// *************************************************************************** *
// *                                                                           *
// * Description:         CANDB File                                           *
// * Generated at:        2025-10-17 10:36                                     *
// * System:              SPA8410_Final2                                       *
// * Variant:             ConfigurationsSPA3d2                                 *
// * Network:             ASDM3CANFD                                           *
// *                                                                           *
// *************************************************************************** *
VERSION "ASDM3CANFD"

NS_ :

BS_ :

BU_ :  ASDM RSRL RSRR
VAL_TABLE_ ElevAlignment_States_RR 2 "MBASC_ELEV_MISALIGNED" 1 "MBASC_ELEV_ALIGNED" 0 "MBASC_ELEV_CALIBRATING" ;
VAL_TABLE_ ElevAlignment_States_RL 2 "MBASC_ELEV_MISALIGNED" 1 "MBASC_ELEV_ALIGNED" 0 "MBASC_ELEV_CALIBRATING" ;

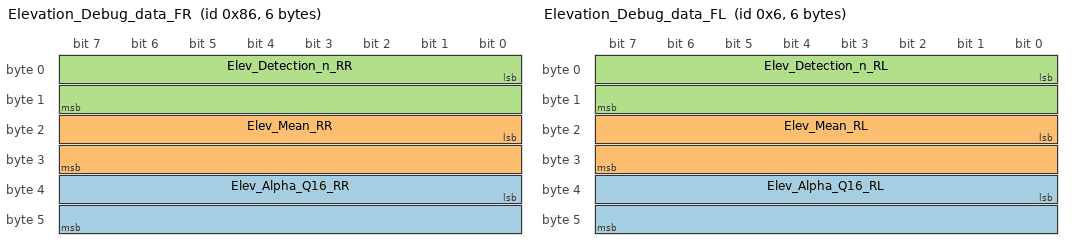
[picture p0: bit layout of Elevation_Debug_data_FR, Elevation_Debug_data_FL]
BO_ 134 Elevation_Debug_data_FR: 6 RSRR
 SG_ Elev_Alpha_Q16_RR : 32|16@1+ (1,0) [0|65535] ""  ASDM
 SG_ Elev_Mean_RR : 16|16@1- (1,0) [-32768|32767] ""  ASDM
 SG_ Elev_Detection_n_RR : 0|16@1+ (1,0) [0|65535] ""  ASDM

BO_ 6 Elevation_Debug_data_FL: 6 RSRL
 SG_ Elev_Alpha_Q16_RL : 32|16@1+ (1,0) [0|65535] ""  ASDM
 SG_ Elev_Mean_RL : 16|16@1- (1,0) [-32768|32767] ""  ASDM
 SG_ Elev_Detection_n_RL : 0|16@1+ (1,0) [0|65535] ""  ASDM

BO_ 917 MB79_PARAMETERS_RR: 24 RSRR
 SG_ Sensor_Serial_Number_RR : 0|192@1+ (1,0) [0|16777215] ""  ASDM

BO_ 789 MB79_PARAMETERS_RL: 24 RSRL
 SG_ Sensor_Serial_Number_RL : 0|192@1+ (1,0) [0|16777215] ""  ASDM

BO_ 898 MB79_SYSTEM_STATUS_RR: 8 RSRR
 SG_ Reserved_2bits_RR : 29|2@1+ (1,0) [0|3] "" Vector__XXX
 SG_ Sensor_Error_Synchronization_Err : 25|1@1+ (1,0) [0|1] "" Vector__XXX
 SG_ Sensor_Error_Supply_Error_RR : 24|1@1+ (1,0) [0|1] "" Vector__XXX
 SG_ Sensor_Error_Software_Incompatib : 27|1@1+ (1,0) [0|1] "" Vector__XXX
 SG_ Sensor_Error_Security_Breach_RR : 28|1@1+ (1,0) [0|1] "" Vector__XXX
 SG_ Sensor_Error_Position_Error_RR : 19|1@1+ (1,0) [0|1] "" Vector__XXX
 SG_ Sensor_Error_Misaligned_RR : 20|1@1+ (1,0) [0|1] "" Vector__XXX
 SG_ Sensor_Error_Internal_Failure_RR : 17|1@1+ (1,0) [0|1] "" Vector__XXX
 SG_ Sensor_Error_Interference_RR : 22|1@1+ (1,0) [0|1] "" Vector__XXX
 SG_ Sensor_Error_Initialization_RR : 23|1@1+ (1,0) [0|1] "" Vector__XXX
 SG_ Sensor_Error_HW_Error_RR : 26|1@1+ (1,0) [0|1] "" Vector__XXX
 SG_ Sensor_Error_Communication_RR : 16|1@1+ (1,0) [0|1] "" Vector__XXX
 SG_ Sensor_Error_Calibration_Error_R : 18|1@1+ (1,0) [0|1] "" Vector__XXX
 SG_ Sensor_Error_Blocked_RR : 21|1@1+ (1,0) [0|1] "" Vector__XXX
 SG_ Heater_Trigger_RR : 31|1@1+ (1,0) [0|1] "" Vector__XXX
 SG_ Sensor_Operation_Mode_RR : 12|4@1+ (1,0) [0|15] ""  ASDM
 SG_ Clock_SystemStatus_RR : 8|4@1+ (1,0) [0|15] ""  ASDM
 SG_ CRC_SystemStatus_RR : 0|8@1+ (1,0) [0|255] ""  ASDM

BO_ 770 MB79_SYSTEM_STATUS_RL: 8 RSRL
 SG_ Reserved_2bits_RL : 29|2@1+ (1,0) [0|3] "" Vector__XXX
 SG_ Sensor_Error_Synchronizatio_0000 : 25|1@1+ (1,0) [0|1] "" Vector__XXX
 SG_ Sensor_Error_Supply_Error_RL : 24|1@1+ (1,0) [0|1] "" Vector__XXX
 SG_ Sensor_Error_Software_Incom_0000 : 27|1@1+ (1,0) [0|1] "" Vector__XXX
 SG_ Sensor_Error_Security_Breach_RL : 28|1@1+ (1,0) [0|1] "" Vector__XXX
 SG_ Sensor_Error_Position_Error_RL : 19|1@1+ (1,0) [0|1] "" Vector__XXX
 SG_ Sensor_Error_Misaligned_RL : 20|1@1+ (1,0) [0|1] "" Vector__XXX
 SG_ Sensor_Error_Internal_Failure_RL : 17|1@1+ (1,0) [0|1] "" Vector__XXX
 SG_ Sensor_Error_Interference_RL : 22|1@1+ (1,0) [0|1] "" Vector__XXX
 SG_ Sensor_Error_Initialization_RL : 23|1@1+ (1,0) [0|1] "" Vector__XXX
 SG_ Sensor_Error_HW_Error_RL : 26|1@1+ (1,0) [0|1] "" Vector__XXX
 SG_ Sensor_Error_Communication_RL : 16|1@1+ (1,0) [0|1] "" Vector__XXX
 SG_ Sensor_Error_Calibration_Er_0000 : 18|1@1+ (1,0) [0|1] "" Vector__XXX
 SG_ Sensor_Error_Blocked_RL : 21|1@1+ (1,0) [0|1] "" Vector__XXX
 SG_ Heater_Trigger_RL : 31|1@1+ (1,0) [0|1] "" Vector__XXX
 SG_ Sensor_Operation_Mode_RL : 12|4@1+ (1,0) [0|15] ""  ASDM
 SG_ Clock_SystemStatus_RL : 8|4@1+ (1,0) [0|15] ""  ASDM
 SG_ CRC_SystemStatus_RL : 0|8@1+ (1,0) [0|255] ""  ASDM

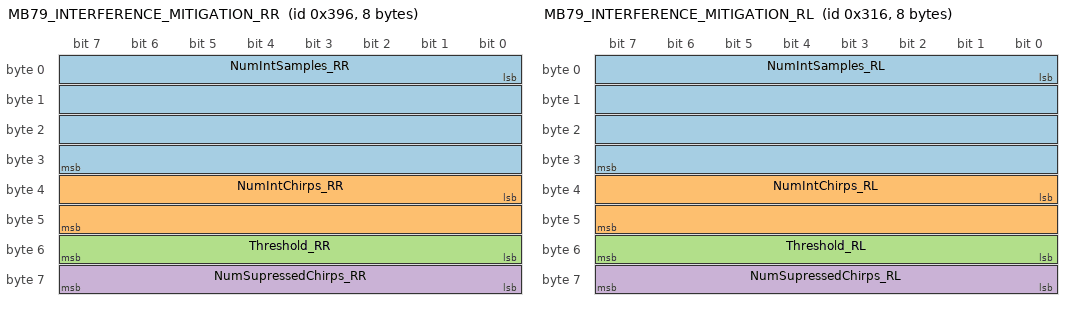
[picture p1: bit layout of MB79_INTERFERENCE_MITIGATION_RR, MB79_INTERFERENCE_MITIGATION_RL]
BO_ 918 MB79_INTERFERENCE_MITIGATION_RR: 8 RSRR
 SG_ NumIntSamples_RR : 0|32@1+ (1,0) [0|16777215] ""  ASDM
 SG_ NumIntChirps_RR : 32|16@1+ (1,0) [0|255] ""  ASDM
 SG_ Threshold_RR : 48|8@1+ (1,0) [0|65535] ""  ASDM
 SG_ NumSupressedChirps_RR : 56|8@1+ (1,0) [0|255] ""  ASDM

BO_ 790 MB79_INTERFERENCE_MITIGATION_RL: 8 RSRL
 SG_ NumIntSamples_RL : 0|32@1+ (1,0) [0|16777215] ""  ASDM
 SG_ NumIntChirps_RL : 32|16@1+ (1,0) [0|255] ""  ASDM
 SG_ Threshold_RL : 48|8@1+ (1,0) [0|65535] ""  ASDM
 SG_ NumSupressedChirps_RL : 56|8@1+ (1,0) [0|255] ""  ASDM

BO_ 2047 AsdmToAllFuncAsdm3CanDiagReqFrame : 64 ASDM
 SG_ AsdmToAllFuncAsdm3CanDiagReqNpdu : 7|512@0+ (1,0) [0|0] "" RSRL, RSRR

BO_ 1953 AsdmToRsrlAsdm3CanDiagReqFrame : 64 ASDM
 SG_ AsdmToRsrlAsdm3CanDiagReqNpdu : 7|512@0+ (1,0) [0|0] "" RSRL

BO_ 1954 AsdmToRsrrAsdm3CanDiagReqFrame : 64 ASDM
 SG_ AsdmToRsrrAsdm3CanDiagReqNpdu : 7|512@0+ (1,0) [0|0] "" RSRR

BO_ 1697 RsrlToAsdmAsdm3CanDiagResFrame : 64 RSRL
 SG_ RsrlToAsdmAsdm3CanDiagResNpdu : 7|512@0+ (1,0) [0|0] "" ASDM

BO_ 1698 RsrrToAsdmAsdm3CanDiagResFrame : 64 RSRR
 SG_ RsrrToAsdmAsdm3CanDiagResNpdu : 7|512@0+ (1,0) [0|0] "" ASDM

BO_ 288 ASDMtoRADAR: 20 ASDM
 SG_ Vehicle_Type : 123|8@0+ (1,0) [0|255] ""  RSRL,RSRR
 SG_ EmblmHeatrOutSts : 117|2@0+ (1,0) [0|0] ""  RSRL,RSRR
 SG_ WshngCycActv : 115|8@0+ (1,0) [0|1] ""  RSRL,RSRR
 SG_ isUsgModSts : 105|4@0+ (1,0) [0|15] ""  RSRL,RSRR
 SG_ PwrLvlElecSubtyp : 3|4@0+ (1,0) [0|15] ""  RSRL,RSRR
 SG_ PwrLvlElecMai : 7|4@0+ (1,0) [0|15] ""  RSRL,RSRR
 SG_ AmbTRawVal : 47|11@0+ (0.1,-70) [-70|134.7] "degC"  RSRL,RSRR
 SG_ AmbTRawQly : 52|2@0+ (1,0) [0|3] ""  RSRL,RSRR
 SG_ BkpOfDstTrvld : 50|21@0+ (1,0) [0|2000000] "km"  RSRL,RSRR
 SG_ CarTiGlb : 15|32@0+ (0.1,0) [0|429496729.5] "s"  RSRL,RSRR
 SG_ CarModSts1 : 81|3@0+ (1,0) [0|7] "N/A"  RSRL,RSRR
 SG_ DrvModReq : 85|4@0+ (1,0) [0|15] ""  RSRL,RSRR
 SG_ VehBattUSysU : 77|8@0+ (0.1,0) [0|25] "Volt"  RSRL,RSRR
 SG_ VehBattUSysUQf : 91|2@0+ (1,0) [0|3] ""  RSRL,RSRR
 SG_ WipgInfoWipgSpdInfo : 94|3@0+ (1,0) [0|7] ""  RSRL,RSRR
 SG_ WipgInfoWiprActv : 97|8@0+ (1,0) [0|255] ""  RSRL,RSRR
 SG_ WipgInfoWiprInWipgAr : 89|8@0+ (1,0) [0|255] ""  RSRL,RSRR

BO_ 1281 MB79_ECU_WAKE_UP_RL: 64 RSRL
 SG_ ECU_Wake_UP_0_RL : 7|8@0+ (1,0) [0|255] "N/A"  ASDM
 SG_ ECU_Wake_UP_1_RL : 15|8@0+ (1,0) [0|255] "N/A"  ASDM
 SG_ ECU_Wake_UP_2_RL : 23|8@0+ (1,0) [0|255] "N/A"  ASDM
 SG_ ECU_Wake_UP_3_RL : 31|8@0+ (1,0) [0|255] "N/A"  ASDM
 SG_ ECU_Wake_UP_4_RL : 39|8@0+ (1,0) [0|255] "N/A"  ASDM
 SG_ ECU_Wake_UP_5_RL : 47|8@0+ (1,0) [0|255] "N/A"  ASDM
 SG_ ECU_Wake_UP_6_RL : 55|8@0+ (1,0) [0|255] "N/A"  ASDM
 SG_ ECU_Wake_UP_7_RL : 63|8@0+ (1,0) [0|255] "N/A"  ASDM

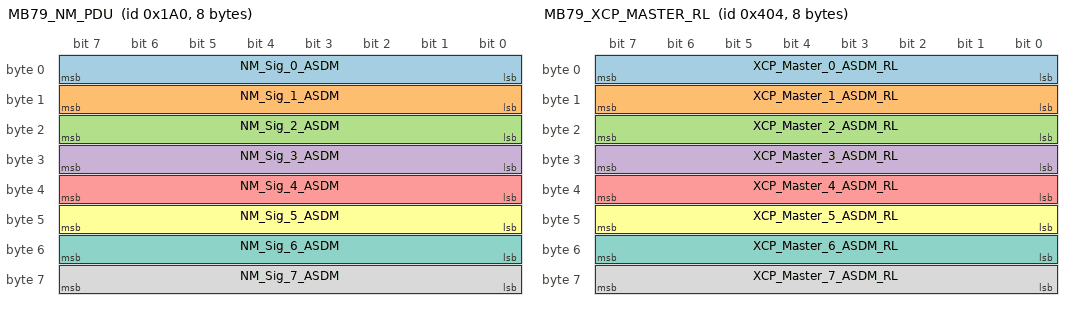
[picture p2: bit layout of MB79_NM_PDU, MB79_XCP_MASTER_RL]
BO_ 416 MB79_NM_PDU: 8 ASDM
 SG_ NM_Sig_0_ASDM : 7|8@0+ (1,0) [0|255] "N/A"  RSRL,RSRR
 SG_ NM_Sig_1_ASDM : 15|8@0+ (1,0) [0|255] "N/A"  RSRL,RSRR
 SG_ NM_Sig_2_ASDM : 23|8@0+ (1,0) [0|255] "N/A"  RSRL,RSRR
 SG_ NM_Sig_3_ASDM : 31|8@0+ (1,0) [0|255] "N/A"  RSRL,RSRR
 SG_ NM_Sig_4_ASDM : 39|8@0+ (1,0) [0|255] "N/A"  RSRL,RSRR
 SG_ NM_Sig_5_ASDM : 47|8@0+ (1,0) [0|255] "N/A"  RSRL,RSRR
 SG_ NM_Sig_6_ASDM : 55|8@0+ (1,0) [0|255] "N/A"  RSRL,RSRR
 SG_ NM_Sig_7_ASDM : 63|8@0+ (1,0) [0|255] "N/A"  RSRL,RSRR

BO_ 1028 MB79_XCP_MASTER_RL: 8 ASDM
 SG_ XCP_Master_0_ASDM_RL : 7|8@0+ (1,0) [0|255] "N/A"  RSRL
 SG_ XCP_Master_1_ASDM_RL : 15|8@0+ (1,0) [0|255] "N/A"  RSRL
 SG_ XCP_Master_2_ASDM_RL : 23|8@0+ (1,0) [0|255] "N/A"  RSRL
 SG_ XCP_Master_3_ASDM_RL : 31|8@0+ (1,0) [0|255] "N/A"  RSRL
 SG_ XCP_Master_4_ASDM_RL : 39|8@0+ (1,0) [0|255] "N/A"  RSRL
 SG_ XCP_Master_5_ASDM_RL : 47|8@0+ (1,0) [0|255] "N/A"  RSRL
 SG_ XCP_Master_6_ASDM_RL : 55|8@0+ (1,0) [0|255] "N/A"  RSRL
 SG_ XCP_Master_7_ASDM_RL : 63|8@0+ (1,0) [0|255] "N/A"  RSRL

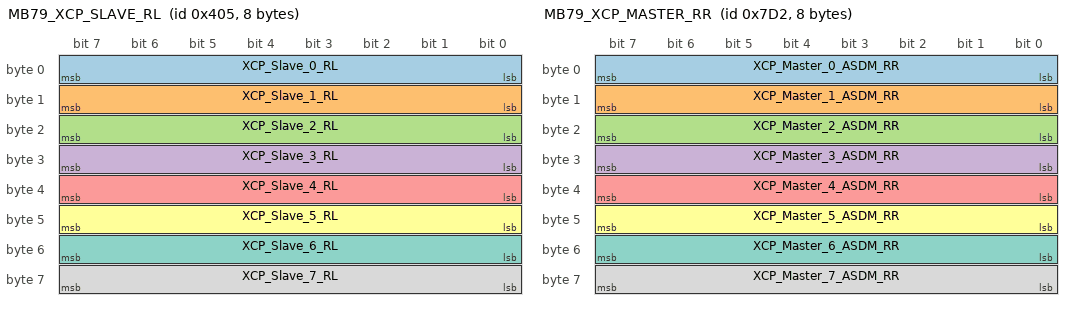
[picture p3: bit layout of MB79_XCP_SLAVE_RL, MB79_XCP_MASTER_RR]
BO_ 1029 MB79_XCP_SLAVE_RL: 8 RSRL
 SG_ XCP_Slave_0_RL : 7|8@0+ (1,0) [0|255] "N/A"  ASDM
 SG_ XCP_Slave_1_RL : 15|8@0+ (1,0) [0|255] "N/A"  ASDM
 SG_ XCP_Slave_2_RL : 23|8@0+ (1,0) [0|255] "N/A"  ASDM
 SG_ XCP_Slave_3_RL : 31|8@0+ (1,0) [0|255] "N/A"  ASDM
 SG_ XCP_Slave_4_RL : 39|8@0+ (1,0) [0|255] "N/A"  ASDM
 SG_ XCP_Slave_5_RL : 47|8@0+ (1,0) [0|255] "N/A"  ASDM
 SG_ XCP_Slave_6_RL : 55|8@0+ (1,0) [0|255] "N/A"  ASDM
 SG_ XCP_Slave_7_RL : 63|8@0+ (1,0) [0|255] "N/A"  ASDM

BO_ 1282 MB79_ECU_WAKE_UP_RR: 64 RSRR
 SG_ ECU_Wake_UP_0_RR : 7|8@0+ (1,0) [0|255] "N/A"  ASDM
 SG_ ECU_Wake_UP_1_RR : 15|8@0+ (1,0) [0|255] "N/A"  ASDM
 SG_ ECU_Wake_UP_2_RR : 23|8@0+ (1,0) [0|255] "N/A"  ASDM
 SG_ ECU_Wake_UP_3_RR : 31|8@0+ (1,0) [0|255] "N/A"  ASDM
 SG_ ECU_Wake_UP_4_RR : 39|8@0+ (1,0) [0|255] "N/A"  ASDM
 SG_ ECU_Wake_UP_5_RR : 47|8@0+ (1,0) [0|255] "N/A"  ASDM
 SG_ ECU_Wake_UP_6_RR : 55|8@0+ (1,0) [0|255] "N/A"  ASDM
 SG_ ECU_Wake_UP_7_RR : 63|8@0+ (1,0) [0|255] "N/A"  ASDM

BO_ 2002 MB79_XCP_MASTER_RR: 8 ASDM
 SG_ XCP_Master_0_ASDM_RR : 7|8@0+ (1,0) [0|255] "N/A"  RSRR
 SG_ XCP_Master_1_ASDM_RR : 15|8@0+ (1,0) [0|255] "N/A"  RSRR
 SG_ XCP_Master_2_ASDM_RR : 23|8@0+ (1,0) [0|255] "N/A"  RSRR
 SG_ XCP_Master_3_ASDM_RR : 31|8@0+ (1,0) [0|255] "N/A"  RSRR
 SG_ XCP_Master_4_ASDM_RR : 39|8@0+ (1,0) [0|255] "N/A"  RSRR
 SG_ XCP_Master_5_ASDM_RR : 47|8@0+ (1,0) [0|255] "N/A"  RSRR
 SG_ XCP_Master_6_ASDM_RR : 55|8@0+ (1,0) [0|255] "N/A"  RSRR
 SG_ XCP_Master_7_ASDM_RR : 63|8@0+ (1,0) [0|255] "N/A"  RSRR

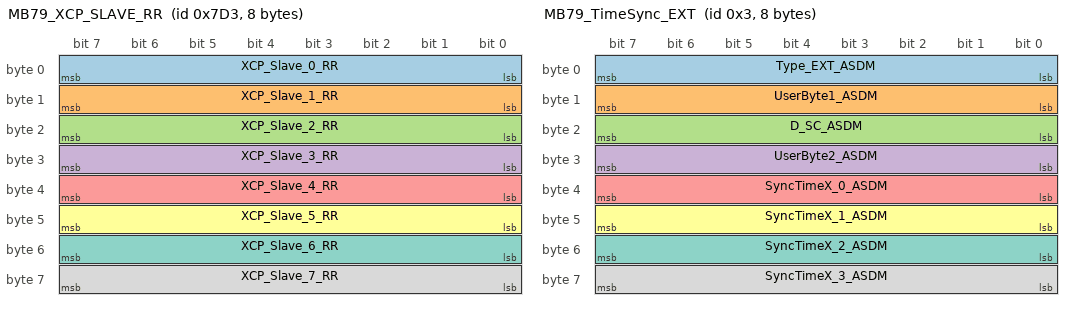
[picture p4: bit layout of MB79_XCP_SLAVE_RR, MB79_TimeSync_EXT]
BO_ 2003 MB79_XCP_SLAVE_RR: 8 RSRR
 SG_ XCP_Slave_0_RR : 7|8@0+ (1,0) [0|255] "N/A"  ASDM
 SG_ XCP_Slave_1_RR : 15|8@0+ (1,0) [0|255] "N/A"  ASDM
 SG_ XCP_Slave_2_RR : 23|8@0+ (1,0) [0|255] "N/A"  ASDM
 SG_ XCP_Slave_3_RR : 31|8@0+ (1,0) [0|255] "N/A"  ASDM
 SG_ XCP_Slave_4_RR : 39|8@0+ (1,0) [0|255] "N/A"  ASDM
 SG_ XCP_Slave_5_RR : 47|8@0+ (1,0) [0|255] "N/A"  ASDM
 SG_ XCP_Slave_6_RR : 55|8@0+ (1,0) [0|255] "N/A"  ASDM
 SG_ XCP_Slave_7_RR : 63|8@0+ (1,0) [0|255] "N/A"  ASDM

BO_ 3 MB79_TimeSync_EXT: 8 ASDM
 SG_ Type_EXT_ASDM : 7|8@0+ (1,0) [0|255] "N/A"  RSRL,RSRR
 SG_ UserByte1_ASDM : 15|8@0+ (1,0) [0|255] "N/A"  RSRL,RSRR
 SG_ D_SC_ASDM : 23|8@0+ (1,0) [0|255] "N/A"  RSRL,RSRR
 SG_ UserByte2_ASDM : 31|8@0+ (1,0) [0|255] "N/A"  RSRL,RSRR
 SG_ SyncTimeX_0_ASDM : 39|8@0+ (1,0) [0|255] "N/A"  RSRL,RSRR
 SG_ SyncTimeX_1_ASDM : 47|8@0+ (1,0) [0|255] "N/A"  RSRL,RSRR
 SG_ SyncTimeX_2_ASDM : 55|8@0+ (1,0) [0|255] "N/A"  RSRL,RSRR
 SG_ SyncTimeX_3_ASDM : 63|8@0+ (1,0) [0|255] "N/A"  RSRL,RSRR

BO_ 257 MB79_DETECTION_HEADER_RL: 64 RSRL
 SG_ ElevAlignment_Status_RL : 504|2@1+ (1,0) [0|3] "" Vector__XXX
 SG_ CRC_DetectionList_RL : 0|32@1+ (1,0) [0|4294967295] "N/A"  ASDM
 SG_ CycleNumber_RL : 32|32@1+ (1,0) [0|4294967295] "cycle"  ASDM
 SG_ TimeStamp_RL : 64|32@1+ (1,0) [0|4294967295] "us"  ASDM
 SG_ HostVelEst_RL : 96|16@1- (1,0) [-2000|14000] "cm/s"  ASDM
 SG_ HostYawEst_RL : 112|16@1- (0.000977,0) [-2|2] "rad/s"  ASDM
 SG_ HostAccelLatEst_RL : 128|16@1- (1,0) [-2000|2000] "cm/s.s"  ASDM
 SG_ HostAccelLongEst_RL : 144|16@1- (1,0) [-2000|2000] "cm/s.s"  ASDM
 SG_ Sensor_Elev_Angle_corr_RL : 160|16@1- (0.01,0) [-180|655.35] "degree"  ASDM
 SG_ Alignment_update_cycle_RL : 176|8@1+ (1,0) [0|255] "N/A"  ASDM
 SG_ Velocity_Correction_RL : 184|16@1- (0.0196,0) [-5|5] "%"  ASDM
 SG_ Sensor_Pos_X_RL : 200|16@1- (0.001,0) [-20|65.535] "m"  ASDM
 SG_ Sensor_Pos_Y_RL : 216|16@1- (0.001,0) [-20|65.535] "m"  ASDM
 SG_ Orientation_Angle_RL : 232|16@1- (0.1,0) [-180|180] "degree"  ASDM
 SG_ Calibrated_Angle_Az_RL : 248|16@1- (0.1,0) [-180|180] "degree"  ASDM
 SG_ Sensor_Pos_Z_RL : 264|8@1+ (0.01,0) [0|2.55] "m"  ASDM
 SG_ Sensor_FoV_Max_RL : 272|8@1+ (1,0) [0|255] "degree"  ASDM
 SG_ Sensor_FoV_Min_RL : 280|8@1+ (1,0) [0|255] "degree"  ASDM
 SG_ BW100KHz1_RL : 288|16@1+ (100,0) [0|6553500] "N/A"  ASDM
 SG_ UnambiguousVelMeas1_RL : 304|8@1+ (1,0) [0|255] "N/A"  ASDM
 SG_ Radar_Sensor_type_RL : 312|8@1+ (1,0) [0|255] "N/A"  ASDM
 SG_ Sensor_Position_ID_RL : 320|4@1+ (1,0) [0|15] "N/A"  ASDM
 SG_ DetectionListVersion_RL : 324|4@1+ (1,0) [0|15] "N/A"  ASDM
 SG_ Detection_Header_Version_RL : 328|4@1+ (1,0) [0|15] "N/A"  ASDM
 SG_ numInfrastructureDetected_RL : 332|10@1+ (1,0) [0|1023] "detection"  ASDM
 SG_ numNonInfraDetected_RL : 342|10@1+ (1,0) [0|1023] "detection"  ASDM
 SG_ numFreespaceDetections_RL : 352|2@1+ (1,0) [0|3] "detection"  ASDM
 SG_ interferenceDetected_RL : 354|2@1+ (1,0) [0|3] "N/A"  ASDM
 SG_ Blockage_Confidence_RL : 356|8@1+ (0.5,0) [0|200] "%"  ASDM
 SG_ Blockage_Level_RL : 364|8@1+ (0.5,0) [0|200] "%"  ASDM
 SG_ Blockage_Status_RL : 372|3@1+ (1,0) [0|7] "N/A"  ASDM
 SG_ max_instrumented_range_2m_RL : 375|8@1+ (2,0) [0|510] "m"  ASDM
 SG_ Sensor_Operation_Mode_RL : 383|4@1+ (1,0) [0|15] "Mode"  ASDM
 SG_ AutoAlignment_Status_RL : 387|4@1+ (1,0) [0|15] "N/A"  ASDM
 SG_ Testing_Mode_RL : 391|4@1+ (1,0) [0|15] "N/A"  ASDM
 SG_ NearZoneDetectionsCount_RL : 395|10@1+ (1,0) [0|512] "detection" Vector__XXX
 SG_ HorizonZoneDetectionsCount_RL : 405|10@1+ (1,0) [0|512] "detection" Vector__XXX
 SG_ Reserved_1byte_RL : 415|8@1- (1,0) [0|0] "" Vector__XXX
 SG_ Detection_Data_Mode_RL : 423|1@1+ (1,0) [0|1] "" Vector__XXX
 SG_ Reserved_3bits_RL : 424|3@1- (1,0) [0|0] "" Vector__XXX
 SG_ AR_Counter_DetectionList_RL : 427|32@1+ (1,0) [0|4294967295] "N/A"  ASDM
 SG_ MAC_DetectionList_RL : 459|24@1+ (1,0) [0|16777215] "N/A"  ASDM
 SG_ Sensor_Topology_RL : 483|1@1+ (1,0) [0|1] "N/A"  ASDM
 SG_ AASC_Calibration_flag_RL : 484|1@1+ (1,0) [0|1] "N/A"  ASDM
 SG_ selected_chirp_config_RL : 485|3@1+ (1,0) [0|7] "N/A"  ASDM
 SG_ FC1MHz1_RL : 488|16@1+ (10,0) [0|65535] "MHz"  ASDM

BO_ 304 MB79_DETECTIONS_0_RL: 64 RSRL
 SG_ zipy_serialized_data_0_RL : 0|32@1- (0.1,0) [-102.4|429496729.5] "degree"  ASDM
 SG_ zipy_serialized_data_1_RL : 32|32@1- (0.1,0) [-102.4|429496729.5] "degree"  ASDM
 SG_ zipy_serialized_data_2_RL : 64|32@1- (0.1,0) [-102.4|429496729.5] "degree"  ASDM
 SG_ zipy_serialized_data_3_RL : 96|32@1- (0.1,0) [-102.4|429496729.5] "degree"  ASDM
 SG_ zipy_serialized_data_4_RL : 128|32@1- (0.1,0) [-102.4|429496729.5] "degree"  ASDM
 SG_ zipy_serialized_data_5_RL : 160|32@1- (0.1,0) [-102.4|429496729.5] "degree"  ASDM
 SG_ zipy_serialized_data_6_RL : 192|32@1- (0.1,0) [-102.4|429496729.5] "degree"  ASDM
 SG_ zipy_serialized_data_7_RL : 224|32@1- (0.1,0) [-102.4|429496729.5] "degree"  ASDM
 SG_ zipy_serialized_data_8_RL : 256|32@1- (0.1,0) [-102.4|429496729.5] "degree"  ASDM
 SG_ zipy_serialized_data_9_RL : 288|32@1- (0.1,0) [-102.4|429496729.5] "degree"  ASDM
 SG_ zipy_serialized_data_10_RL : 320|32@1- (0.1,0) [-102.4|429496729.5] "degree"  ASDM
 SG_ zipy_serialized_data_11_RL : 352|32@1- (0.1,0) [-102.4|429496729.5] "degree"  ASDM
 SG_ zipy_serialized_data_12_RL : 384|32@1- (0.1,0) [-102.4|429496729.5] "degree"  ASDM
 SG_ zipy_serialized_data_13_RL : 416|32@1- (0.1,0) [-102.4|429496729.5] "degree"  ASDM
 SG_ zipy_serialized_data_14_RL : 448|32@1- (0.1,0) [-102.4|429496729.5] "degree"  ASDM
 SG_ zipy_serialized_data_15_RL : 480|32@1- (0.1,0) [-102.4|429496729.5] "degree"  ASDM

BO_ 305 MB79_DETECTIONS_1_RL: 64 RSRL
 SG_ zipy_serialized_data_16_RL : 0|32@1- (0.1,0) [-102.4|429496729.5] "degree"  ASDM
 SG_ zipy_serialized_data_17_RL : 32|32@1- (0.1,0) [-102.4|429496729.5] "degree"  ASDM
 SG_ zipy_serialized_data_18_RL : 64|32@1- (0.1,0) [-102.4|429496729.5] "degree"  ASDM
 SG_ zipy_serialized_data_19_RL : 96|32@1- (0.1,0) [-102.4|429496729.5] "degree"  ASDM
 SG_ zipy_serialized_data_20_RL : 128|32@1- (0.1,0) [-102.4|429496729.5] "degree"  ASDM
 SG_ zipy_serialized_data_21_RL : 160|32@1- (0.1,0) [-102.4|429496729.5] "degree"  ASDM
 SG_ zipy_serialized_data_22_RL : 192|32@1- (0.1,0) [-102.4|429496729.5] "degree"  ASDM
 SG_ zipy_serialized_data_23_RL : 224|32@1- (0.1,0) [-102.4|429496729.5] "degree"  ASDM
 SG_ zipy_serialized_data_24_RL : 256|32@1- (0.1,0) [-102.4|429496729.5] "degree"  ASDM
 SG_ zipy_serialized_data_25_RL : 288|32@1- (0.1,0) [-102.4|429496729.5] "degree"  ASDM
 SG_ zipy_serialized_data_26_RL : 320|32@1- (0.1,0) [-102.4|429496729.5] "degree"  ASDM
 SG_ zipy_serialized_data_27_RL : 352|32@1- (0.1,0) [-102.4|429496729.5] "degree"  ASDM
 SG_ zipy_serialized_data_28_RL : 384|32@1- (0.1,0) [-102.4|429496729.5] "degree"  ASDM
 SG_ zipy_serialized_data_29_RL : 416|32@1- (0.1,0) [-102.4|429496729.5] "degree"  ASDM
 SG_ zipy_serialized_data_30_RL : 448|32@1- (0.1,0) [-102.4|429496729.5] "degree"  ASDM
 SG_ zipy_serialized_data_31_RL : 480|32@1- (0.1,0) [-102.4|429496729.5] "degree"  ASDM

BO_ 306 MB79_DETECTIONS_2_RL: 64 RSRL
 SG_ zipy_serialized_data_32_RL : 0|32@1- (0.1,0) [-102.4|429496729.5] "degree"  ASDM
 SG_ zipy_serialized_data_33_RL : 32|32@1- (0.1,0) [-102.4|429496729.5] "degree"  ASDM
 SG_ zipy_serialized_data_34_RL : 64|32@1- (0.1,0) [-102.4|429496729.5] "degree"  ASDM
 SG_ zipy_serialized_data_35_RL : 96|32@1- (0.1,0) [-102.4|429496729.5] "degree"  ASDM
 SG_ zipy_serialized_data_36_RL : 128|32@1- (0.1,0) [-102.4|429496729.5] "degree"  ASDM
 SG_ zipy_serialized_data_37_RL : 160|32@1- (0.1,0) [-102.4|429496729.5] "degree"  ASDM
 SG_ zipy_serialized_data_38_RL : 192|32@1- (0.1,0) [-102.4|429496729.5] "degree"  ASDM
 SG_ zipy_serialized_data_39_RL : 224|32@1- (0.1,0) [-102.4|429496729.5] "degree"  ASDM
 SG_ zipy_serialized_data_40_RL : 256|32@1- (0.1,0) [-102.4|429496729.5] "degree"  ASDM
 SG_ zipy_serialized_data_41_RL : 288|32@1- (0.1,0) [-102.4|429496729.5] "degree"  ASDM
 SG_ zipy_serialized_data_42_RL : 320|32@1- (0.1,0) [-102.4|429496729.5] "degree"  ASDM
 SG_ zipy_serialized_data_43_RL : 352|32@1- (0.1,0) [-102.4|429496729.5] "degree"  ASDM
 SG_ zipy_serialized_data_44_RL : 384|32@1- (0.1,0) [-102.4|429496729.5] "degree"  ASDM
 SG_ zipy_serialized_data_45_RL : 416|32@1- (0.1,0) [-102.4|429496729.5] "degree"  ASDM
 SG_ zipy_serialized_data_46_RL : 448|32@1- (0.1,0) [-102.4|429496729.5] "degree"  ASDM
 SG_ zipy_serialized_data_47_RL : 480|32@1- (0.1,0) [-102.4|429496729.5] "degree"  ASDM

BO_ 307 MB79_DETECTIONS_3_RL: 64 RSRL
 SG_ zipy_serialized_data_48_RL : 0|32@1- (0.1,0) [-102.4|429496729.5] "degree"  ASDM
 SG_ zipy_serialized_data_49_RL : 32|32@1- (0.1,0) [-102.4|429496729.5] "degree"  ASDM
 SG_ zipy_serialized_data_50_RL : 64|32@1- (0.1,0) [-102.4|429496729.5] "degree"  ASDM
 SG_ zipy_serialized_data_51_RL : 96|32@1- (0.1,0) [-102.4|429496729.5] "degree"  ASDM
 SG_ zipy_serialized_data_52_RL : 128|32@1- (0.1,0) [-102.4|429496729.5] "degree"  ASDM
 SG_ zipy_serialized_data_53_RL : 160|32@1- (0.1,0) [-102.4|429496729.5] "degree"  ASDM
 SG_ zipy_serialized_data_54_RL : 192|32@1- (0.1,0) [-102.4|429496729.5] "degree"  ASDM
 SG_ zipy_serialized_data_55_RL : 224|32@1- (0.1,0) [-102.4|429496729.5] "degree"  ASDM
 SG_ zipy_serialized_data_56_RL : 256|32@1- (0.1,0) [-102.4|429496729.5] "degree"  ASDM
 SG_ zipy_serialized_data_57_RL : 288|32@1- (0.1,0) [-102.4|429496729.5] "degree"  ASDM
 SG_ zipy_serialized_data_58_RL : 320|32@1- (0.1,0) [-102.4|429496729.5] "degree"  ASDM
 SG_ zipy_serialized_data_59_RL : 352|32@1- (0.1,0) [-102.4|429496729.5] "degree"  ASDM
 SG_ zipy_serialized_data_60_RL : 384|32@1- (0.1,0) [-102.4|429496729.5] "degree"  ASDM
 SG_ zipy_serialized_data_61_RL : 416|32@1- (0.1,0) [-102.4|429496729.5] "degree"  ASDM
 SG_ zipy_serialized_data_62_RL : 448|32@1- (0.1,0) [-102.4|429496729.5] "degree"  ASDM
 SG_ zipy_serialized_data_63_RL : 480|32@1- (0.1,0) [-102.4|429496729.5] "degree"  ASDM

BO_ 308 MB79_DETECTIONS_4_RL: 64 RSRL
 SG_ zipy_serialized_data_64_RL : 0|32@1- (0.1,0) [-102.4|429496729.5] "degree"  ASDM
 SG_ zipy_serialized_data_65_RL : 32|32@1- (0.1,0) [-102.4|429496729.5] "degree"  ASDM
 SG_ zipy_serialized_data_66_RL : 64|32@1- (0.1,0) [-102.4|429496729.5] "degree"  ASDM
 SG_ zipy_serialized_data_67_RL : 96|32@1- (0.1,0) [-102.4|429496729.5] "degree"  ASDM
 SG_ zipy_serialized_data_68_RL : 128|32@1- (0.1,0) [-102.4|429496729.5] "degree"  ASDM
 SG_ zipy_serialized_data_69_RL : 160|32@1- (0.1,0) [-102.4|429496729.5] "degree"  ASDM
 SG_ zipy_serialized_data_70_RL : 192|32@1- (0.1,0) [-102.4|429496729.5] "degree"  ASDM
 SG_ zipy_serialized_data_71_RL : 224|32@1- (0.1,0) [-102.4|429496729.5] "degree"  ASDM
 SG_ zipy_serialized_data_72_RL : 256|32@1- (0.1,0) [-102.4|429496729.5] "degree"  ASDM
 SG_ zipy_serialized_data_73_RL : 288|32@1- (0.1,0) [-102.4|429496729.5] "degree"  ASDM
 SG_ zipy_serialized_data_74_RL : 320|32@1- (0.1,0) [-102.4|429496729.5] "degree"  ASDM
 SG_ zipy_serialized_data_75_RL : 352|32@1- (0.1,0) [-102.4|429496729.5] "degree"  ASDM
 SG_ zipy_serialized_data_76_RL : 384|32@1- (0.1,0) [-102.4|429496729.5] "degree"  ASDM
 SG_ zipy_serialized_data_77_RL : 416|32@1- (0.1,0) [-102.4|429496729.5] "degree"  ASDM
 SG_ zipy_serialized_data_78_RL : 448|32@1- (0.1,0) [-102.4|429496729.5] "degree"  ASDM
 SG_ zipy_serialized_data_79_RL : 480|32@1- (0.1,0) [-102.4|429496729.5] "degree"  ASDM

BO_ 309 MB79_DETECTIONS_5_RL: 64 RSRL
 SG_ zipy_serialized_data_80_RL : 0|32@1- (0.1,0) [-102.4|429496729.5] "degree"  ASDM
 SG_ zipy_serialized_data_81_RL : 32|32@1- (0.1,0) [-102.4|429496729.5] "degree"  ASDM
 SG_ zipy_serialized_data_82_RL : 64|32@1- (0.1,0) [-102.4|429496729.5] "degree"  ASDM
 SG_ zipy_serialized_data_83_RL : 96|32@1- (0.1,0) [-102.4|429496729.5] "degree"  ASDM
 SG_ zipy_serialized_data_84_RL : 128|32@1- (0.1,0) [-102.4|429496729.5] "degree"  ASDM
 SG_ zipy_serialized_data_85_RL : 160|32@1- (0.1,0) [-102.4|429496729.5] "degree"  ASDM
 SG_ zipy_serialized_data_86_RL : 192|32@1- (0.1,0) [-102.4|429496729.5] "degree"  ASDM
 SG_ zipy_serialized_data_87_RL : 224|32@1- (0.1,0) [-102.4|429496729.5] "degree"  ASDM
 SG_ zipy_serialized_data_88_RL : 256|32@1- (0.1,0) [-102.4|429496729.5] "degree"  ASDM
 SG_ zipy_serialized_data_89_RL : 288|32@1- (0.1,0) [-102.4|429496729.5] "degree"  ASDM
 SG_ zipy_serialized_data_90_RL : 320|32@1- (0.1,0) [-102.4|429496729.5] "degree"  ASDM
 SG_ zipy_serialized_data_91_RL : 352|32@1- (0.1,0) [-102.4|429496729.5] "degree"  ASDM
 SG_ zipy_serialized_data_92_RL : 384|32@1- (0.1,0) [-102.4|429496729.5] "degree"  ASDM
 SG_ zipy_serialized_data_93_RL : 416|32@1- (0.1,0) [-102.4|429496729.5] "degree"  ASDM
 SG_ zipy_serialized_data_94_RL : 448|32@1- (0.1,0) [-102.4|429496729.5] "degree"  ASDM
 SG_ zipy_serialized_data_95_RL : 480|32@1- (0.1,0) [-102.4|429496729.5] "degree"  ASDM

BO_ 310 MB79_DETECTIONS_6_RL: 64 RSRL
 SG_ zipy_serialized_data_96_RL : 0|32@1- (0.1,0) [-102.4|429496729.5] "degree"  ASDM
 SG_ zipy_serialized_data_97_RL : 32|32@1- (0.1,0) [-102.4|429496729.5] "degree"  ASDM
 SG_ zipy_serialized_data_98_RL : 64|32@1- (0.1,0) [-102.4|429496729.5] "degree"  ASDM
 SG_ zipy_serialized_data_99_RL : 96|32@1- (0.1,0) [-102.4|429496729.5] "degree"  ASDM
 SG_ zipy_serialized_data_100_RL : 128|32@1- (0.1,0) [-102.4|429496729.5] "degree"  ASDM
 SG_ zipy_serialized_data_101_RL : 160|32@1- (0.1,0) [-102.4|429496729.5] "degree"  ASDM
 SG_ zipy_serialized_data_102_RL : 192|32@1- (0.1,0) [-102.4|429496729.5] "degree"  ASDM
 SG_ zipy_serialized_data_103_RL : 224|32@1- (0.1,0) [-102.4|429496729.5] "degree"  ASDM
 SG_ zipy_serialized_data_104_RL : 256|32@1- (0.1,0) [-102.4|429496729.5] "degree"  ASDM
 SG_ zipy_serialized_data_105_RL : 288|32@1- (0.1,0) [-102.4|429496729.5] "degree"  ASDM
 SG_ zipy_serialized_data_106_RL : 320|32@1- (0.1,0) [-102.4|429496729.5] "degree"  ASDM
 SG_ zipy_serialized_data_107_RL : 352|32@1- (0.1,0) [-102.4|429496729.5] "degree"  ASDM
 SG_ zipy_serialized_data_108_RL : 384|32@1- (0.1,0) [-102.4|429496729.5] "degree"  ASDM
 SG_ zipy_serialized_data_109_RL : 416|32@1- (0.1,0) [-102.4|429496729.5] "degree"  ASDM
 SG_ zipy_serialized_data_110_RL : 448|32@1- (0.1,0) [-102.4|429496729.5] "degree"  ASDM
 SG_ zipy_serialized_data_111_RL : 480|32@1- (0.1,0) [-102.4|429496729.5] "degree"  ASDM

BO_ 311 MB79_DETECTIONS_7_RL: 64 RSRL
 SG_ zipy_serialized_data_112_RL : 0|32@1- (0.1,0) [-102.4|429496729.5] "degree"  ASDM
 SG_ zipy_serialized_data_113_RL : 32|32@1- (0.1,0) [-102.4|429496729.5] "degree"  ASDM
 SG_ zipy_serialized_data_114_RL : 64|32@1- (0.1,0) [-102.4|429496729.5] "degree"  ASDM
 SG_ zipy_serialized_data_115_RL : 96|32@1- (0.1,0) [-102.4|429496729.5] "degree"  ASDM
 SG_ zipy_serialized_data_116_RL : 128|32@1- (0.1,0) [-102.4|429496729.5] "degree"  ASDM
 SG_ zipy_serialized_data_117_RL : 160|32@1- (0.1,0) [-102.4|429496729.5] "degree"  ASDM
 SG_ zipy_serialized_data_118_RL : 192|32@1- (0.1,0) [-102.4|429496729.5] "degree"  ASDM
 SG_ zipy_serialized_data_119_RL : 224|32@1- (0.1,0) [-102.4|429496729.5] "degree"  ASDM
 SG_ zipy_serialized_data_120_RL : 256|32@1- (0.1,0) [-102.4|429496729.5] "degree"  ASDM
 SG_ zipy_serialized_data_121_RL : 288|32@1- (0.1,0) [-102.4|429496729.5] "degree"  ASDM
 SG_ zipy_serialized_data_122_RL : 320|32@1- (0.1,0) [-102.4|429496729.5] "degree"  ASDM
 SG_ zipy_serialized_data_123_RL : 352|32@1- (0.1,0) [-102.4|429496729.5] "degree"  ASDM
 SG_ zipy_serialized_data_124_RL : 384|32@1- (0.1,0) [-102.4|429496729.5] "degree"  ASDM
 SG_ zipy_serialized_data_125_RL : 416|32@1- (0.1,0) [-102.4|429496729.5] "degree"  ASDM
 SG_ zipy_serialized_data_126_RL : 448|32@1- (0.1,0) [-102.4|429496729.5] "degree"  ASDM
 SG_ zipy_serialized_data_127_RL : 480|32@1- (0.1,0) [-102.4|429496729.5] "degree"  ASDM

BO_ 312 MB79_DETECTIONS_8_RL: 64 RSRL
 SG_ zipy_serialized_data_128_RL : 0|32@1- (0.1,0) [-102.4|429496729.5] "degree"  ASDM
 SG_ zipy_serialized_data_129_RL : 32|32@1- (0.1,0) [-102.4|429496729.5] "degree"  ASDM
 SG_ zipy_serialized_data_130_RL : 64|32@1- (0.1,0) [-102.4|429496729.5] "degree"  ASDM
 SG_ zipy_serialized_data_131_RL : 96|32@1- (0.1,0) [-102.4|429496729.5] "degree"  ASDM
 SG_ zipy_serialized_data_132_RL : 128|32@1- (0.1,0) [-102.4|429496729.5] "degree"  ASDM
 SG_ zipy_serialized_data_133_RL : 160|32@1- (0.1,0) [-102.4|429496729.5] "degree"  ASDM
 SG_ zipy_serialized_data_134_RL : 192|32@1- (0.1,0) [-102.4|429496729.5] "degree"  ASDM
 SG_ zipy_serialized_data_135_RL : 224|32@1- (0.1,0) [-102.4|429496729.5] "degree"  ASDM
 SG_ zipy_serialized_data_136_RL : 256|32@1- (0.1,0) [-102.4|429496729.5] "degree"  ASDM
 SG_ zipy_serialized_data_137_RL : 288|32@1- (0.1,0) [-102.4|429496729.5] "degree"  ASDM
 SG_ zipy_serialized_data_138_RL : 320|32@1- (0.1,0) [-102.4|429496729.5] "degree"  ASDM
 SG_ zipy_serialized_data_139_RL : 352|32@1- (0.1,0) [-102.4|429496729.5] "degree"  ASDM
 SG_ zipy_serialized_data_140_RL : 384|32@1- (0.1,0) [-102.4|429496729.5] "degree"  ASDM
 SG_ zipy_serialized_data_141_RL : 416|32@1- (0.1,0) [-102.4|429496729.5] "degree"  ASDM
 SG_ zipy_serialized_data_142_RL : 448|32@1- (0.1,0) [-102.4|429496729.5] "degree"  ASDM
 SG_ zipy_serialized_data_143_RL : 480|32@1- (0.1,0) [-102.4|429496729.5] "degree"  ASDM

BO_ 313 MB79_DETECTIONS_9_RL: 64 RSRL
 SG_ zipy_serialized_data_144_RL : 0|32@1- (0.1,0) [-102.4|429496729.5] "degree"  ASDM
 SG_ zipy_serialized_data_145_RL : 32|32@1- (0.1,0) [-102.4|429496729.5] "degree"  ASDM
 SG_ zipy_serialized_data_146_RL : 64|32@1- (0.1,0) [-102.4|429496729.5] "degree"  ASDM
 SG_ zipy_serialized_data_147_RL : 96|32@1- (0.1,0) [-102.4|429496729.5] "degree"  ASDM
 SG_ zipy_serialized_data_148_RL : 128|32@1- (0.1,0) [-102.4|429496729.5] "degree"  ASDM
 SG_ zipy_serialized_data_149_RL : 160|32@1- (0.1,0) [-102.4|429496729.5] "degree"  ASDM
 SG_ zipy_serialized_data_150_RL : 192|32@1- (0.1,0) [-102.4|429496729.5] "degree"  ASDM
 SG_ zipy_serialized_data_151_RL : 224|32@1- (0.1,0) [-102.4|429496729.5] "degree"  ASDM
 SG_ zipy_serialized_data_152_RL : 256|32@1- (0.1,0) [-102.4|429496729.5] "degree"  ASDM
 SG_ zipy_serialized_data_153_RL : 288|32@1- (0.1,0) [-102.4|429496729.5] "degree"  ASDM
 SG_ zipy_serialized_data_154_RL : 320|32@1- (0.1,0) [-102.4|429496729.5] "degree"  ASDM
 SG_ zipy_serialized_data_155_RL : 352|32@1- (0.1,0) [-102.4|429496729.5] "degree"  ASDM
 SG_ zipy_serialized_data_156_RL : 384|32@1- (0.1,0) [-102.4|429496729.5] "degree"  ASDM
 SG_ zipy_serialized_data_157_RL : 416|32@1- (0.1,0) [-102.4|429496729.5] "degree"  ASDM
 SG_ zipy_serialized_data_158_RL : 448|32@1- (0.1,0) [-102.4|429496729.5] "degree"  ASDM
 SG_ zipy_serialized_data_159_RL : 480|32@1- (0.1,0) [-102.4|429496729.5] "degree"  ASDM

BO_ 314 MB79_DETECTIONS_10_RL: 64 RSRL
 SG_ zipy_serialized_data_160_RL : 0|32@1- (0.1,0) [-102.4|429496729.5] "degree"  ASDM
 SG_ zipy_serialized_data_161_RL : 32|32@1- (0.1,0) [-102.4|429496729.5] "degree"  ASDM
 SG_ zipy_serialized_data_162_RL : 64|32@1- (0.1,0) [-102.4|429496729.5] "degree"  ASDM
 SG_ zipy_serialized_data_163_RL : 96|32@1- (0.1,0) [-102.4|429496729.5] "degree"  ASDM
 SG_ zipy_serialized_data_164_RL : 128|32@1- (0.1,0) [-102.4|429496729.5] "degree"  ASDM
 SG_ zipy_serialized_data_165_RL : 160|32@1- (0.1,0) [-102.4|429496729.5] "degree"  ASDM
 SG_ zipy_serialized_data_166_RL : 192|32@1- (0.1,0) [-102.4|429496729.5] "degree"  ASDM
 SG_ zipy_serialized_data_167_RL : 224|32@1- (0.1,0) [-102.4|429496729.5] "degree"  ASDM
 SG_ zipy_serialized_data_168_RL : 256|32@1- (0.1,0) [-102.4|429496729.5] "degree"  ASDM
 SG_ zipy_serialized_data_169_RL : 288|32@1- (0.1,0) [-102.4|429496729.5] "degree"  ASDM
 SG_ zipy_serialized_data_170_RL : 320|32@1- (0.1,0) [-102.4|429496729.5] "degree"  ASDM
 SG_ zipy_serialized_data_171_RL : 352|32@1- (0.1,0) [-102.4|429496729.5] "degree"  ASDM
 SG_ zipy_serialized_data_172_RL : 384|32@1- (0.1,0) [-102.4|429496729.5] "degree"  ASDM
 SG_ zipy_serialized_data_173_RL : 416|32@1- (0.1,0) [-102.4|429496729.5] "degree"  ASDM
 SG_ zipy_serialized_data_174_RL : 448|32@1- (0.1,0) [-102.4|429496729.5] "degree"  ASDM
 SG_ zipy_serialized_data_175_RL : 480|32@1- (0.1,0) [-102.4|429496729.5] "degree"  ASDM

BO_ 315 MB79_DETECTIONS_11_RL: 64 RSRL
 SG_ zipy_serialized_data_176_RL : 0|32@1- (0.1,0) [-102.4|429496729.5] "degree"  ASDM
 SG_ zipy_serialized_data_177_RL : 32|32@1- (0.1,0) [-102.4|429496729.5] "degree"  ASDM
 SG_ zipy_serialized_data_178_RL : 64|32@1- (0.1,0) [-102.4|429496729.5] "degree"  ASDM
 SG_ zipy_serialized_data_179_RL : 96|32@1- (0.1,0) [-102.4|429496729.5] "degree"  ASDM
 SG_ zipy_serialized_data_180_RL : 128|32@1- (0.1,0) [-102.4|429496729.5] "degree"  ASDM
 SG_ zipy_serialized_data_181_RL : 160|32@1- (0.1,0) [-102.4|429496729.5] "degree"  ASDM
 SG_ zipy_serialized_data_182_RL : 192|32@1- (0.1,0) [-102.4|429496729.5] "degree"  ASDM
 SG_ zipy_serialized_data_183_RL : 224|32@1- (0.1,0) [-102.4|429496729.5] "degree"  ASDM
 SG_ zipy_serialized_data_184_RL : 256|32@1- (0.1,0) [-102.4|429496729.5] "degree"  ASDM
 SG_ zipy_serialized_data_185_RL : 288|32@1- (0.1,0) [-102.4|429496729.5] "degree"  ASDM
 SG_ zipy_serialized_data_186_RL : 320|32@1- (0.1,0) [-102.4|429496729.5] "degree"  ASDM
 SG_ zipy_serialized_data_187_RL : 352|32@1- (0.1,0) [-102.4|429496729.5] "degree"  ASDM
 SG_ zipy_serialized_data_188_RL : 384|32@1- (0.1,0) [-102.4|429496729.5] "degree"  ASDM
 SG_ zipy_serialized_data_189_RL : 416|32@1- (0.1,0) [-102.4|429496729.5] "degree"  ASDM
 SG_ zipy_serialized_data_190_RL : 448|32@1- (0.1,0) [-102.4|429496729.5] "degree"  ASDM
 SG_ zipy_serialized_data_191_RL : 480|32@1- (0.1,0) [-102.4|429496729.5] "degree"  ASDM

BO_ 316 MB79_DETECTIONS_12_RL: 64 RSRL
 SG_ zipy_serialized_data_192_RL : 0|32@1- (0.1,0) [-102.4|429496729.5] "degree"  ASDM
 SG_ zipy_serialized_data_193_RL : 32|32@1- (0.1,0) [-102.4|429496729.5] "degree"  ASDM
 SG_ zipy_serialized_data_194_RL : 64|32@1- (0.1,0) [-102.4|429496729.5] "degree"  ASDM
 SG_ zipy_serialized_data_195_RL : 96|32@1- (0.1,0) [-102.4|429496729.5] "degree"  ASDM
 SG_ zipy_serialized_data_196_RL : 128|32@1- (0.1,0) [-102.4|429496729.5] "degree"  ASDM
 SG_ zipy_serialized_data_197_RL : 160|32@1- (0.1,0) [-102.4|429496729.5] "degree"  ASDM
 SG_ zipy_serialized_data_198_RL : 192|32@1- (0.1,0) [-102.4|429496729.5] "degree"  ASDM
 SG_ zipy_serialized_data_199_RL : 224|32@1- (0.1,0) [-102.4|429496729.5] "degree"  ASDM
 SG_ zipy_serialized_data_200_RL : 256|32@1- (0.1,0) [-102.4|429496729.5] "degree"  ASDM
 SG_ zipy_serialized_data_201_RL : 288|32@1- (0.1,0) [-102.4|429496729.5] "degree"  ASDM
 SG_ zipy_serialized_data_202_RL : 320|32@1- (0.1,0) [-102.4|429496729.5] "degree"  ASDM
 SG_ zipy_serialized_data_203_RL : 352|32@1- (0.1,0) [-102.4|429496729.5] "degree"  ASDM
 SG_ zipy_serialized_data_204_RL : 384|32@1- (0.1,0) [-102.4|429496729.5] "degree"  ASDM
 SG_ zipy_serialized_data_205_RL : 416|32@1- (0.1,0) [-102.4|429496729.5] "degree"  ASDM
 SG_ zipy_serialized_data_206_RL : 448|32@1- (0.1,0) [-102.4|429496729.5] "degree"  ASDM
 SG_ zipy_serialized_data_207_RL : 480|32@1- (0.1,0) [-102.4|429496729.5] "degree"  ASDM

BO_ 317 MB79_DETECTIONS_13_RL: 64 RSRL
 SG_ zipy_serialized_data_208_RL : 0|32@1- (0.1,0) [-102.4|429496729.5] "degree"  ASDM
 SG_ zipy_serialized_data_209_RL : 32|32@1- (0.1,0) [-102.4|429496729.5] "degree"  ASDM
 SG_ zipy_serialized_data_210_RL : 64|32@1- (0.1,0) [-102.4|429496729.5] "degree"  ASDM
 SG_ zipy_serialized_data_211_RL : 96|32@1- (0.1,0) [-102.4|429496729.5] "degree"  ASDM
 SG_ zipy_serialized_data_212_RL : 128|32@1- (0.1,0) [-102.4|429496729.5] "degree"  ASDM
 SG_ zipy_serialized_data_213_RL : 160|32@1- (0.1,0) [-102.4|429496729.5] "degree"  ASDM
 SG_ zipy_serialized_data_214_RL : 192|32@1- (0.1,0) [-102.4|429496729.5] "degree"  ASDM
 SG_ zipy_serialized_data_215_RL : 224|32@1- (0.1,0) [-102.4|429496729.5] "degree"  ASDM
 SG_ zipy_serialized_data_216_RL : 256|32@1- (0.1,0) [-102.4|429496729.5] "degree"  ASDM
 SG_ zipy_serialized_data_217_RL : 288|32@1- (0.1,0) [-102.4|429496729.5] "degree"  ASDM
 SG_ zipy_serialized_data_218_RL : 320|32@1- (0.1,0) [-102.4|429496729.5] "degree"  ASDM
 SG_ zipy_serialized_data_219_RL : 352|32@1- (0.1,0) [-102.4|429496729.5] "degree"  ASDM
 SG_ zipy_serialized_data_220_RL : 384|32@1- (0.1,0) [-102.4|429496729.5] "degree"  ASDM
 SG_ zipy_serialized_data_221_RL : 416|32@1- (0.1,0) [-102.4|429496729.5] "degree"  ASDM
 SG_ zipy_serialized_data_222_RL : 448|32@1- (0.1,0) [-102.4|429496729.5] "degree"  ASDM
 SG_ zipy_serialized_data_223_RL : 480|32@1- (0.1,0) [-102.4|429496729.5] "degree"  ASDM

BO_ 318 MB79_DETECTIONS_14_RL: 64 RSRL
 SG_ zipy_serialized_data_224_RL : 0|32@1- (0.1,0) [-102.4|429496729.5] "degree"  ASDM
 SG_ zipy_serialized_data_225_RL : 32|32@1- (0.1,0) [-102.4|429496729.5] "degree"  ASDM
 SG_ zipy_serialized_data_226_RL : 64|32@1- (0.1,0) [-102.4|429496729.5] "degree"  ASDM
 SG_ zipy_serialized_data_227_RL : 96|32@1- (0.1,0) [-102.4|429496729.5] "degree"  ASDM
 SG_ zipy_serialized_data_228_RL : 128|32@1- (0.1,0) [-102.4|429496729.5] "degree"  ASDM
 SG_ zipy_serialized_data_229_RL : 160|32@1- (0.1,0) [-102.4|429496729.5] "degree"  ASDM
 SG_ zipy_serialized_data_230_RL : 192|32@1- (0.1,0) [-102.4|429496729.5] "degree"  ASDM
 SG_ zipy_serialized_data_231_RL : 224|32@1- (0.1,0) [-102.4|429496729.5] "degree"  ASDM
 SG_ zipy_serialized_data_232_RL : 256|32@1- (0.1,0) [-102.4|429496729.5] "degree"  ASDM
 SG_ zipy_serialized_data_233_RL : 288|32@1- (0.1,0) [-102.4|429496729.5] "degree"  ASDM
 SG_ zipy_serialized_data_234_RL : 320|32@1- (0.1,0) [-102.4|429496729.5] "degree"  ASDM
 SG_ zipy_serialized_data_235_RL : 352|32@1- (0.1,0) [-102.4|429496729.5] "degree"  ASDM
 SG_ zipy_serialized_data_236_RL : 384|32@1- (0.1,0) [-102.4|429496729.5] "degree"  ASDM
 SG_ zipy_serialized_data_237_RL : 416|32@1- (0.1,0) [-102.4|429496729.5] "degree"  ASDM
 SG_ zipy_serialized_data_238_RL : 448|32@1- (0.1,0) [-102.4|429496729.5] "degree"  ASDM
 SG_ zipy_serialized_data_239_RL : 480|32@1- (0.1,0) [-102.4|429496729.5] "degree"  ASDM

BO_ 319 MB79_DETECTIONS_15_RL: 64 RSRL
 SG_ zipy_serialized_data_240_RL : 0|32@1- (0.1,0) [-102.4|429496729.5] "degree"  ASDM
 SG_ zipy_serialized_data_241_RL : 32|32@1- (0.1,0) [-102.4|429496729.5] "degree"  ASDM
 SG_ zipy_serialized_data_242_RL : 64|32@1- (0.1,0) [-102.4|429496729.5] "degree"  ASDM
 SG_ zipy_serialized_data_243_RL : 96|32@1- (0.1,0) [-102.4|429496729.5] "degree"  ASDM
 SG_ zipy_serialized_data_244_RL : 128|32@1- (0.1,0) [-102.4|429496729.5] "degree"  ASDM
 SG_ zipy_serialized_data_245_RL : 160|32@1- (0.1,0) [-102.4|429496729.5] "degree"  ASDM
 SG_ zipy_serialized_data_246_RL : 192|32@1- (0.1,0) [-102.4|429496729.5] "degree"  ASDM
 SG_ zipy_serialized_data_247_RL : 224|32@1- (0.1,0) [-102.4|429496729.5] "degree"  ASDM
 SG_ zipy_serialized_data_248_RL : 256|32@1- (0.1,0) [-102.4|429496729.5] "degree"  ASDM
 SG_ zipy_serialized_data_249_RL : 288|32@1- (0.1,0) [-102.4|429496729.5] "degree"  ASDM
 SG_ zipy_serialized_data_250_RL : 320|32@1- (0.1,0) [-102.4|429496729.5] "degree"  ASDM
 SG_ zipy_serialized_data_251_RL : 352|32@1- (0.1,0) [-102.4|429496729.5] "degree"  ASDM
 SG_ zipy_serialized_data_252_RL : 384|32@1- (0.1,0) [-102.4|429496729.5] "degree"  ASDM
 SG_ zipy_serialized_data_253_RL : 416|32@1- (0.1,0) [-102.4|429496729.5] "degree"  ASDM
 SG_ zipy_serialized_data_254_RL : 448|32@1- (0.1,0) [-102.4|429496729.5] "degree"  ASDM
 SG_ zipy_serialized_data_255_RL : 480|32@1- (0.1,0) [-102.4|429496729.5] "degree"  ASDM

BO_ 320 MB79_DETECTIONS_16_RL: 64 RSRL
 SG_ zipy_serialized_data_256_RL : 0|32@1- (0.1,0) [-102.4|429496729.5] "degree"  ASDM
 SG_ zipy_serialized_data_257_RL : 32|32@1- (0.1,0) [-102.4|429496729.5] "degree"  ASDM
 SG_ zipy_serialized_data_258_RL : 64|32@1- (0.1,0) [-102.4|429496729.5] "degree"  ASDM
 SG_ zipy_serialized_data_259_RL : 96|32@1- (0.1,0) [-102.4|429496729.5] "degree"  ASDM
 SG_ zipy_serialized_data_260_RL : 128|32@1- (0.1,0) [-102.4|429496729.5] "degree"  ASDM
 SG_ zipy_serialized_data_261_RL : 160|32@1- (0.1,0) [-102.4|429496729.5] "degree"  ASDM
 SG_ zipy_serialized_data_262_RL : 192|32@1- (0.1,0) [-102.4|429496729.5] "degree"  ASDM
 SG_ zipy_serialized_data_263_RL : 224|32@1- (0.1,0) [-102.4|429496729.5] "degree"  ASDM
 SG_ zipy_serialized_data_264_RL : 256|32@1- (0.1,0) [-102.4|429496729.5] "degree"  ASDM
 SG_ zipy_serialized_data_265_RL : 288|32@1- (0.1,0) [-102.4|429496729.5] "degree"  ASDM
 SG_ zipy_serialized_data_266_RL : 320|32@1- (0.1,0) [-102.4|429496729.5] "degree"  ASDM
 SG_ zipy_serialized_data_267_RL : 352|32@1- (0.1,0) [-102.4|429496729.5] "degree"  ASDM
 SG_ zipy_serialized_data_268_RL : 384|32@1- (0.1,0) [-102.4|429496729.5] "degree"  ASDM
 SG_ zipy_serialized_data_269_RL : 416|32@1- (0.1,0) [-102.4|429496729.5] "degree"  ASDM
 SG_ zipy_serialized_data_270_RL : 448|32@1- (0.1,0) [-102.4|429496729.5] "degree"  ASDM
 SG_ zipy_serialized_data_271_RL : 480|32@1- (0.1,0) [-102.4|429496729.5] "degree"  ASDM

BO_ 321 MB79_DETECTIONS_17_RL: 64 RSRL
 SG_ zipy_serialized_data_272_RL : 0|32@1- (0.1,0) [-102.4|429496729.5] "degree"  ASDM
 SG_ zipy_serialized_data_273_RL : 32|32@1- (0.1,0) [-102.4|429496729.5] "degree"  ASDM
 SG_ zipy_serialized_data_274_RL : 64|32@1- (0.1,0) [-102.4|429496729.5] "degree"  ASDM
 SG_ zipy_serialized_data_275_RL : 96|32@1- (0.1,0) [-102.4|429496729.5] "degree"  ASDM
 SG_ zipy_serialized_data_276_RL : 128|32@1- (0.1,0) [-102.4|429496729.5] "degree"  ASDM
 SG_ zipy_serialized_data_277_RL : 160|32@1- (0.1,0) [-102.4|429496729.5] "degree"  ASDM
 SG_ zipy_serialized_data_278_RL : 192|32@1- (0.1,0) [-102.4|429496729.5] "degree"  ASDM
 SG_ zipy_serialized_data_279_RL : 224|32@1- (0.1,0) [-102.4|429496729.5] "degree"  ASDM
 SG_ zipy_serialized_data_280_RL : 256|32@1- (0.1,0) [-102.4|429496729.5] "degree"  ASDM
 SG_ zipy_serialized_data_281_RL : 288|32@1- (0.1,0) [-102.4|429496729.5] "degree"  ASDM
 SG_ zipy_serialized_data_282_RL : 320|32@1- (0.1,0) [-102.4|429496729.5] "degree"  ASDM
 SG_ zipy_serialized_data_283_RL : 352|32@1- (0.1,0) [-102.4|429496729.5] "degree"  ASDM
 SG_ zipy_serialized_data_284_RL : 384|32@1- (0.1,0) [-102.4|429496729.5] "degree"  ASDM
 SG_ zipy_serialized_data_285_RL : 416|32@1- (0.1,0) [-102.4|429496729.5] "degree"  ASDM
 SG_ zipy_serialized_data_286_RL : 448|32@1- (0.1,0) [-102.4|429496729.5] "degree"  ASDM
 SG_ zipy_serialized_data_287_RL : 480|32@1- (0.1,0) [-102.4|429496729.5] "degree"  ASDM

BO_ 322 MB79_DETECTIONS_18_RL: 64 RSRL
 SG_ zipy_serialized_data_288_RL : 0|32@1- (0.1,0) [-102.4|429496729.5] "degree"  ASDM
 SG_ zipy_serialized_data_289_RL : 32|32@1- (0.1,0) [-102.4|429496729.5] "degree"  ASDM
 SG_ zipy_serialized_data_290_RL : 64|32@1- (0.1,0) [-102.4|429496729.5] "degree"  ASDM
 SG_ zipy_serialized_data_291_RL : 96|32@1- (0.1,0) [-102.4|429496729.5] "degree"  ASDM
 SG_ zipy_serialized_data_292_RL : 128|32@1- (0.1,0) [-102.4|429496729.5] "degree"  ASDM
 SG_ zipy_serialized_data_293_RL : 160|32@1- (0.1,0) [-102.4|429496729.5] "degree"  ASDM
 SG_ zipy_serialized_data_294_RL : 192|32@1- (0.1,0) [-102.4|429496729.5] "degree"  ASDM
 SG_ zipy_serialized_data_295_RL : 224|32@1- (0.1,0) [-102.4|429496729.5] "degree"  ASDM
 SG_ zipy_serialized_data_296_RL : 256|32@1- (0.1,0) [-102.4|429496729.5] "degree"  ASDM
 SG_ zipy_serialized_data_297_RL : 288|32@1- (0.1,0) [-102.4|429496729.5] "degree"  ASDM
 SG_ zipy_serialized_data_298_RL : 320|32@1- (0.1,0) [-102.4|429496729.5] "degree"  ASDM
 SG_ zipy_serialized_data_299_RL : 352|32@1- (0.1,0) [-102.4|429496729.5] "degree"  ASDM
 SG_ zipy_serialized_data_300_RL : 384|32@1- (0.1,0) [-102.4|429496729.5] "degree"  ASDM
 SG_ zipy_serialized_data_301_RL : 416|32@1- (0.1,0) [-102.4|429496729.5] "degree"  ASDM
 SG_ zipy_serialized_data_302_RL : 448|32@1- (0.1,0) [-102.4|429496729.5] "degree"  ASDM
 SG_ zipy_serialized_data_303_RL : 480|32@1- (0.1,0) [-102.4|429496729.5] "degree"  ASDM

BO_ 323 MB79_DETECTIONS_19_RL: 64 RSRL
 SG_ zipy_serialized_data_304_RL : 0|32@1- (0.1,0) [-102.4|429496729.5] "degree"  ASDM
 SG_ zipy_serialized_data_305_RL : 32|32@1- (0.1,0) [-102.4|429496729.5] "degree"  ASDM
 SG_ zipy_serialized_data_306_RL : 64|32@1- (0.1,0) [-102.4|429496729.5] "degree"  ASDM
 SG_ zipy_serialized_data_307_RL : 96|32@1- (0.1,0) [-102.4|429496729.5] "degree"  ASDM
 SG_ zipy_serialized_data_308_RL : 128|32@1- (0.1,0) [-102.4|429496729.5] "degree"  ASDM
 SG_ zipy_serialized_data_309_RL : 160|32@1- (0.1,0) [-102.4|429496729.5] "degree"  ASDM
 SG_ zipy_serialized_data_310_RL : 192|32@1- (0.1,0) [-102.4|429496729.5] "degree"  ASDM
 SG_ zipy_serialized_data_311_RL : 224|32@1- (0.1,0) [-102.4|429496729.5] "degree"  ASDM
 SG_ zipy_serialized_data_312_RL : 256|32@1- (0.1,0) [-102.4|429496729.5] "degree"  ASDM
 SG_ zipy_serialized_data_313_RL : 288|32@1- (0.1,0) [-102.4|429496729.5] "degree"  ASDM
 SG_ zipy_serialized_data_314_RL : 320|32@1- (0.1,0) [-102.4|429496729.5] "degree"  ASDM
 SG_ zipy_serialized_data_315_RL : 352|32@1- (0.1,0) [-102.4|429496729.5] "degree"  ASDM
 SG_ zipy_serialized_data_316_RL : 384|32@1- (0.1,0) [-102.4|429496729.5] "degree"  ASDM
 SG_ zipy_serialized_data_317_RL : 416|32@1- (0.1,0) [-102.4|429496729.5] "degree"  ASDM
 SG_ zipy_serialized_data_318_RL : 448|32@1- (0.1,0) [-102.4|429496729.5] "degree"  ASDM
 SG_ zipy_serialized_data_319_RL : 480|32@1- (0.1,0) [-102.4|429496729.5] "degree"  ASDM

BO_ 324 MB79_DETECTIONS_20_RL: 64 RSRL
 SG_ zipy_serialized_data_320_RL : 0|32@1- (0.1,0) [-102.4|429496729.5] "degree"  ASDM
 SG_ zipy_serialized_data_321_RL : 32|32@1- (0.1,0) [-102.4|429496729.5] "degree"  ASDM
 SG_ zipy_serialized_data_322_RL : 64|32@1- (0.1,0) [-102.4|429496729.5] "degree"  ASDM
 SG_ zipy_serialized_data_323_RL : 96|32@1- (0.1,0) [-102.4|429496729.5] "degree"  ASDM
 SG_ zipy_serialized_data_324_RL : 128|32@1- (0.1,0) [-102.4|429496729.5] "degree"  ASDM
 SG_ zipy_serialized_data_325_RL : 160|32@1- (0.1,0) [-102.4|429496729.5] "degree"  ASDM
 SG_ zipy_serialized_data_326_RL : 192|32@1- (0.1,0) [-102.4|429496729.5] "degree"  ASDM
 SG_ zipy_serialized_data_327_RL : 224|32@1- (0.1,0) [-102.4|429496729.5] "degree"  ASDM
 SG_ zipy_serialized_data_328_RL : 256|32@1- (0.1,0) [-102.4|429496729.5] "degree"  ASDM
 SG_ zipy_serialized_data_329_RL : 288|32@1- (0.1,0) [-102.4|429496729.5] "degree"  ASDM
 SG_ zipy_serialized_data_330_RL : 320|32@1- (0.1,0) [-102.4|429496729.5] "degree"  ASDM
 SG_ zipy_serialized_data_331_RL : 352|32@1- (0.1,0) [-102.4|429496729.5] "degree"  ASDM
 SG_ zipy_serialized_data_332_RL : 384|32@1- (0.1,0) [-102.4|429496729.5] "degree"  ASDM
 SG_ zipy_serialized_data_333_RL : 416|32@1- (0.1,0) [-102.4|429496729.5] "degree"  ASDM
 SG_ zipy_serialized_data_334_RL : 448|32@1- (0.1,0) [-102.4|429496729.5] "degree"  ASDM
 SG_ zipy_serialized_data_335_RL : 480|32@1- (0.1,0) [-102.4|429496729.5] "degree"  ASDM

BO_ 325 MB79_DETECTIONS_21_RL: 64 RSRL
 SG_ zipy_serialized_data_336_RL : 0|32@1- (0.1,0) [-102.4|429496729.5] "degree"  ASDM
 SG_ zipy_serialized_data_337_RL : 32|32@1- (0.1,0) [-102.4|429496729.5] "degree"  ASDM
 SG_ zipy_serialized_data_338_RL : 64|32@1- (0.1,0) [-102.4|429496729.5] "degree"  ASDM
 SG_ zipy_serialized_data_339_RL : 96|32@1- (0.1,0) [-102.4|429496729.5] "degree"  ASDM
 SG_ zipy_serialized_data_340_RL : 128|32@1- (0.1,0) [-102.4|429496729.5] "degree"  ASDM
 SG_ zipy_serialized_data_341_RL : 160|32@1- (0.1,0) [-102.4|429496729.5] "degree"  ASDM
 SG_ zipy_serialized_data_342_RL : 192|32@1- (0.1,0) [-102.4|429496729.5] "degree"  ASDM
 SG_ zipy_serialized_data_343_RL : 224|32@1- (0.1,0) [-102.4|429496729.5] "degree"  ASDM
 SG_ zipy_serialized_data_344_RL : 256|32@1- (0.1,0) [-102.4|429496729.5] "degree"  ASDM
 SG_ zipy_serialized_data_345_RL : 288|32@1- (0.1,0) [-102.4|429496729.5] "degree"  ASDM
 SG_ zipy_serialized_data_346_RL : 320|32@1- (0.1,0) [-102.4|429496729.5] "degree"  ASDM
 SG_ zipy_serialized_data_347_RL : 352|32@1- (0.1,0) [-102.4|429496729.5] "degree"  ASDM
 SG_ zipy_serialized_data_348_RL : 384|32@1- (0.1,0) [-102.4|429496729.5] "degree"  ASDM
 SG_ zipy_serialized_data_349_RL : 416|32@1- (0.1,0) [-102.4|429496729.5] "degree"  ASDM
 SG_ zipy_serialized_data_350_RL : 448|32@1- (0.1,0) [-102.4|429496729.5] "degree"  ASDM
 SG_ zipy_serialized_data_351_RL : 480|32@1- (0.1,0) [-102.4|429496729.5] "degree"  ASDM

BO_ 326 MB79_DETECTIONS_22_RL: 64 RSRL
 SG_ zipy_serialized_data_352_RL : 0|32@1- (0.1,0) [-102.4|429496729.5] "degree"  ASDM
 SG_ zipy_serialized_data_353_RL : 32|32@1- (0.1,0) [-102.4|429496729.5] "degree"  ASDM
 SG_ zipy_serialized_data_354_RL : 64|32@1- (0.1,0) [-102.4|429496729.5] "degree"  ASDM
 SG_ zipy_serialized_data_355_RL : 96|32@1- (0.1,0) [-102.4|429496729.5] "degree"  ASDM
 SG_ zipy_serialized_data_356_RL : 128|32@1- (0.1,0) [-102.4|429496729.5] "degree"  ASDM
 SG_ zipy_serialized_data_357_RL : 160|32@1- (0.1,0) [-102.4|429496729.5] "degree"  ASDM
 SG_ zipy_serialized_data_358_RL : 192|32@1- (0.1,0) [-102.4|429496729.5] "degree"  ASDM
 SG_ zipy_serialized_data_359_RL : 224|32@1- (0.1,0) [-102.4|429496729.5] "degree"  ASDM
 SG_ zipy_serialized_data_360_RL : 256|32@1- (0.1,0) [-102.4|429496729.5] "degree"  ASDM
 SG_ zipy_serialized_data_361_RL : 288|32@1- (0.1,0) [-102.4|429496729.5] "degree"  ASDM
 SG_ zipy_serialized_data_362_RL : 320|32@1- (0.1,0) [-102.4|429496729.5] "degree"  ASDM
 SG_ zipy_serialized_data_363_RL : 352|32@1- (0.1,0) [-102.4|429496729.5] "degree"  ASDM
 SG_ zipy_serialized_data_364_RL : 384|32@1- (0.1,0) [-102.4|429496729.5] "degree"  ASDM
 SG_ zipy_serialized_data_365_RL : 416|32@1- (0.1,0) [-102.4|429496729.5] "degree"  ASDM
 SG_ zipy_serialized_data_366_RL : 448|32@1- (0.1,0) [-102.4|429496729.5] "degree"  ASDM
 SG_ zipy_serialized_data_367_RL : 480|32@1- (0.1,0) [-102.4|429496729.5] "degree"  ASDM

BO_ 327 MB79_DETECTIONS_23_RL: 64 RSRL
 SG_ zipy_serialized_data_368_RL : 0|32@1- (0.1,0) [-102.4|429496729.5] "degree"  ASDM
 SG_ zipy_serialized_data_369_RL : 32|32@1- (0.1,0) [-102.4|429496729.5] "degree"  ASDM
 SG_ zipy_serialized_data_370_RL : 64|32@1- (0.1,0) [-102.4|429496729.5] "degree"  ASDM
 SG_ zipy_serialized_data_371_RL : 96|32@1- (0.1,0) [-102.4|429496729.5] "degree"  ASDM
 SG_ zipy_serialized_data_372_RL : 128|32@1- (0.1,0) [-102.4|429496729.5] "degree"  ASDM
 SG_ zipy_serialized_data_373_RL : 160|32@1- (0.1,0) [-102.4|429496729.5] "degree"  ASDM
 SG_ zipy_serialized_data_374_RL : 192|32@1- (0.1,0) [-102.4|429496729.5] "degree"  ASDM
 SG_ zipy_serialized_data_375_RL : 224|32@1- (0.1,0) [-102.4|429496729.5] "degree"  ASDM
 SG_ zipy_serialized_data_376_RL : 256|32@1- (0.1,0) [-102.4|429496729.5] "degree"  ASDM
 SG_ zipy_serialized_data_377_RL : 288|32@1- (0.1,0) [-102.4|429496729.5] "degree"  ASDM
 SG_ zipy_serialized_data_378_RL : 320|32@1- (0.1,0) [-102.4|429496729.5] "degree"  ASDM
 SG_ zipy_serialized_data_379_RL : 352|32@1- (0.1,0) [-102.4|429496729.5] "degree"  ASDM
 SG_ zipy_serialized_data_380_RL : 384|32@1- (0.1,0) [-102.4|429496729.5] "degree"  ASDM
 SG_ zipy_serialized_data_381_RL : 416|32@1- (0.1,0) [-102.4|429496729.5] "degree"  ASDM
 SG_ zipy_serialized_data_382_RL : 448|32@1- (0.1,0) [-102.4|429496729.5] "degree"  ASDM
 SG_ zipy_serialized_data_383_RL : 480|32@1- (0.1,0) [-102.4|429496729.5] "degree"  ASDM

BO_ 328 MB79_DETECTIONS_24_RL: 64 RSRL
 SG_ zipy_serialized_data_384_RL : 0|32@1- (0.1,0) [-102.4|429496729.5] "degree"  ASDM
 SG_ zipy_serialized_data_385_RL : 32|32@1- (0.1,0) [-102.4|429496729.5] "degree"  ASDM
 SG_ zipy_serialized_data_386_RL : 64|32@1- (0.1,0) [-102.4|429496729.5] "degree"  ASDM
 SG_ zipy_serialized_data_387_RL : 96|32@1- (0.1,0) [-102.4|429496729.5] "degree"  ASDM
 SG_ zipy_serialized_data_388_RL : 128|32@1- (0.1,0) [-102.4|429496729.5] "degree"  ASDM
 SG_ zipy_serialized_data_389_RL : 160|32@1- (0.1,0) [-102.4|429496729.5] "degree"  ASDM
 SG_ zipy_serialized_data_390_RL : 192|32@1- (0.1,0) [-102.4|429496729.5] "degree"  ASDM
 SG_ zipy_serialized_data_391_RL : 224|32@1- (0.1,0) [-102.4|429496729.5] "degree"  ASDM
 SG_ zipy_serialized_data_392_RL : 256|32@1- (0.1,0) [-102.4|429496729.5] "degree"  ASDM
 SG_ zipy_serialized_data_393_RL : 288|32@1- (0.1,0) [-102.4|429496729.5] "degree"  ASDM
 SG_ zipy_serialized_data_394_RL : 320|32@1- (0.1,0) [-102.4|429496729.5] "degree"  ASDM
 SG_ zipy_serialized_data_395_RL : 352|32@1- (0.1,0) [-102.4|429496729.5] "degree"  ASDM
 SG_ zipy_serialized_data_396_RL : 384|32@1- (0.1,0) [-102.4|429496729.5] "degree"  ASDM
 SG_ zipy_serialized_data_397_RL : 416|32@1- (0.1,0) [-102.4|429496729.5] "degree"  ASDM
 SG_ zipy_serialized_data_398_RL : 448|32@1- (0.1,0) [-102.4|429496729.5] "degree"  ASDM
 SG_ zipy_serialized_data_399_RL : 480|32@1- (0.1,0) [-102.4|429496729.5] "degree"  ASDM

BO_ 329 MB79_DETECTIONS_25_RL: 64 RSRL
 SG_ zipy_serialized_data_400_RL : 0|32@1- (0.1,0) [-102.4|429496729.5] "degree"  ASDM
 SG_ zipy_serialized_data_401_RL : 32|32@1- (0.1,0) [-102.4|429496729.5] "degree"  ASDM
 SG_ zipy_serialized_data_402_RL : 64|32@1- (0.1,0) [-102.4|429496729.5] "degree"  ASDM
 SG_ zipy_serialized_data_403_RL : 96|32@1- (0.1,0) [-102.4|429496729.5] "degree"  ASDM
 SG_ zipy_serialized_data_404_RL : 128|32@1- (0.1,0) [-102.4|429496729.5] "degree"  ASDM
 SG_ zipy_serialized_data_405_RL : 160|32@1- (0.1,0) [-102.4|429496729.5] "degree"  ASDM
 SG_ zipy_serialized_data_406_RL : 192|32@1- (0.1,0) [-102.4|429496729.5] "degree"  ASDM
 SG_ zipy_serialized_data_407_RL : 224|32@1- (0.1,0) [-102.4|429496729.5] "degree"  ASDM
 SG_ zipy_serialized_data_408_RL : 256|32@1- (0.1,0) [-102.4|429496729.5] "degree"  ASDM
 SG_ zipy_serialized_data_409_RL : 288|32@1- (0.1,0) [-102.4|429496729.5] "degree"  ASDM
 SG_ zipy_serialized_data_410_RL : 320|32@1- (0.1,0) [-102.4|429496729.5] "degree"  ASDM
 SG_ zipy_serialized_data_411_RL : 352|32@1- (0.1,0) [-102.4|429496729.5] "degree"  ASDM
 SG_ zipy_serialized_data_412_RL : 384|32@1- (0.1,0) [-102.4|429496729.5] "degree"  ASDM
 SG_ zipy_serialized_data_413_RL : 416|32@1- (0.1,0) [-102.4|429496729.5] "degree"  ASDM
 SG_ zipy_serialized_data_414_RL : 448|32@1- (0.1,0) [-102.4|429496729.5] "degree"  ASDM
 SG_ zipy_serialized_data_415_RL : 480|32@1- (0.1,0) [-102.4|429496729.5] "degree"  ASDM

BO_ 330 MB79_DETECTIONS_26_RL: 64 RSRL
 SG_ zipy_serialized_data_416_RL : 0|32@1- (0.1,0) [-102.4|429496729.5] "degree"  ASDM
 SG_ zipy_serialized_data_417_RL : 32|32@1- (0.1,0) [-102.4|429496729.5] "degree"  ASDM
 SG_ zipy_serialized_data_418_RL : 64|32@1- (0.1,0) [-102.4|429496729.5] "degree"  ASDM
 SG_ zipy_serialized_data_419_RL : 96|32@1- (0.1,0) [-102.4|429496729.5] "degree"  ASDM
 SG_ zipy_serialized_data_420_RL : 128|32@1- (0.1,0) [-102.4|429496729.5] "degree"  ASDM
 SG_ zipy_serialized_data_421_RL : 160|32@1- (0.1,0) [-102.4|429496729.5] "degree"  ASDM
 SG_ zipy_serialized_data_422_RL : 192|32@1- (0.1,0) [-102.4|429496729.5] "degree"  ASDM
 SG_ zipy_serialized_data_423_RL : 224|32@1- (0.1,0) [-102.4|429496729.5] "degree"  ASDM
 SG_ zipy_serialized_data_424_RL : 256|32@1- (0.1,0) [-102.4|429496729.5] "degree"  ASDM
 SG_ zipy_serialized_data_425_RL : 288|32@1- (0.1,0) [-102.4|429496729.5] "degree"  ASDM
 SG_ zipy_serialized_data_426_RL : 320|32@1- (0.1,0) [-102.4|429496729.5] "degree"  ASDM
 SG_ zipy_serialized_data_427_RL : 352|32@1- (0.1,0) [-102.4|429496729.5] "degree"  ASDM
 SG_ zipy_serialized_data_428_RL : 384|32@1- (0.1,0) [-102.4|429496729.5] "degree"  ASDM
 SG_ zipy_serialized_data_429_RL : 416|32@1- (0.1,0) [-102.4|429496729.5] "degree"  ASDM
 SG_ zipy_serialized_data_430_RL : 448|32@1- (0.1,0) [-102.4|429496729.5] "degree"  ASDM
 SG_ zipy_serialized_data_431_RL : 480|32@1- (0.1,0) [-102.4|429496729.5] "degree"  ASDM

BO_ 331 MB79_DETECTIONS_27_RL: 64 RSRL
 SG_ zipy_serialized_data_432_RL : 0|32@1- (0.1,0) [-102.4|429496729.5] "degree"  ASDM
 SG_ zipy_serialized_data_433_RL : 32|32@1- (0.1,0) [-102.4|429496729.5] "degree"  ASDM
 SG_ zipy_serialized_data_434_RL : 64|32@1- (0.1,0) [-102.4|429496729.5] "degree"  ASDM
 SG_ zipy_serialized_data_435_RL : 96|32@1- (0.1,0) [-102.4|429496729.5] "degree"  ASDM
 SG_ zipy_serialized_data_436_RL : 128|32@1- (0.1,0) [-102.4|429496729.5] "degree"  ASDM
 SG_ zipy_serialized_data_437_RL : 160|32@1- (0.1,0) [-102.4|429496729.5] "degree"  ASDM
 SG_ zipy_serialized_data_438_RL : 192|32@1- (0.1,0) [-102.4|429496729.5] "degree"  ASDM
 SG_ zipy_serialized_data_439_RL : 224|32@1- (0.1,0) [-102.4|429496729.5] "degree"  ASDM
 SG_ zipy_serialized_data_440_RL : 256|32@1- (0.1,0) [-102.4|429496729.5] "degree"  ASDM
 SG_ zipy_serialized_data_441_RL : 288|32@1- (0.1,0) [-102.4|429496729.5] "degree"  ASDM
 SG_ zipy_serialized_data_442_RL : 320|32@1- (0.1,0) [-102.4|429496729.5] "degree"  ASDM
 SG_ zipy_serialized_data_443_RL : 352|32@1- (0.1,0) [-102.4|429496729.5] "degree"  ASDM
 SG_ zipy_serialized_data_444_RL : 384|32@1- (0.1,0) [-102.4|429496729.5] "degree"  ASDM
 SG_ zipy_serialized_data_445_RL : 416|32@1- (0.1,0) [-102.4|429496729.5] "degree"  ASDM
 SG_ zipy_serialized_data_446_RL : 448|32@1- (0.1,0) [-102.4|429496729.5] "degree"  ASDM
 SG_ zipy_serialized_data_447_RL : 480|32@1- (0.1,0) [-102.4|429496729.5] "degree"  ASDM

BO_ 332 MB79_DETECTIONS_28_RL: 64 RSRL
 SG_ zipy_serialized_data_448_RL : 0|32@1- (0.1,0) [-102.4|429496729.5] "degree"  ASDM
 SG_ zipy_serialized_data_449_RL : 32|32@1- (0.1,0) [-102.4|429496729.5] "degree"  ASDM
 SG_ zipy_serialized_data_450_RL : 64|32@1- (0.1,0) [-102.4|429496729.5] "degree"  ASDM
 SG_ zipy_serialized_data_451_RL : 96|32@1- (0.1,0) [-102.4|429496729.5] "degree"  ASDM
 SG_ zipy_serialized_data_452_RL : 128|32@1- (0.1,0) [-102.4|429496729.5] "degree"  ASDM
 SG_ zipy_serialized_data_453_RL : 160|32@1- (0.1,0) [-102.4|429496729.5] "degree"  ASDM
 SG_ zipy_serialized_data_454_RL : 192|32@1- (0.1,0) [-102.4|429496729.5] "degree"  ASDM
 SG_ zipy_serialized_data_455_RL : 224|32@1- (0.1,0) [-102.4|429496729.5] "degree"  ASDM
 SG_ zipy_serialized_data_456_RL : 256|32@1- (0.1,0) [-102.4|429496729.5] "degree"  ASDM
 SG_ zipy_serialized_data_457_RL : 288|32@1- (0.1,0) [-102.4|429496729.5] "degree"  ASDM
 SG_ zipy_serialized_data_458_RL : 320|32@1- (0.1,0) [-102.4|429496729.5] "degree"  ASDM
 SG_ zipy_serialized_data_459_RL : 352|32@1- (0.1,0) [-102.4|429496729.5] "degree"  ASDM
 SG_ zipy_serialized_data_460_RL : 384|32@1- (0.1,0) [-102.4|429496729.5] "degree"  ASDM
 SG_ zipy_serialized_data_461_RL : 416|32@1- (0.1,0) [-102.4|429496729.5] "degree"  ASDM
 SG_ zipy_serialized_data_462_RL : 448|32@1- (0.1,0) [-102.4|429496729.5] "degree"  ASDM
 SG_ zipy_serialized_data_463_RL : 480|32@1- (0.1,0) [-102.4|429496729.5] "degree"  ASDM

BO_ 333 MB79_DETECTIONS_29_RL: 64 RSRL
 SG_ zipy_serialized_data_464_RL : 0|32@1- (0.1,0) [-102.4|429496729.5] "degree"  ASDM
 SG_ zipy_serialized_data_465_RL : 32|32@1- (0.1,0) [-102.4|429496729.5] "degree"  ASDM
 SG_ zipy_serialized_data_466_RL : 64|32@1- (0.1,0) [-102.4|429496729.5] "degree"  ASDM
 SG_ zipy_serialized_data_467_RL : 96|32@1- (0.1,0) [-102.4|429496729.5] "degree"  ASDM
 SG_ zipy_serialized_data_468_RL : 128|32@1- (0.1,0) [-102.4|429496729.5] "degree"  ASDM
 SG_ zipy_serialized_data_469_RL : 160|32@1- (0.1,0) [-102.4|429496729.5] "degree"  ASDM
 SG_ zipy_serialized_data_470_RL : 192|32@1- (0.1,0) [-102.4|429496729.5] "degree"  ASDM
 SG_ zipy_serialized_data_471_RL : 224|32@1- (0.1,0) [-102.4|429496729.5] "degree"  ASDM
 SG_ zipy_serialized_data_472_RL : 256|32@1- (0.1,0) [-102.4|429496729.5] "degree"  ASDM
 SG_ zipy_serialized_data_473_RL : 288|32@1- (0.1,0) [-102.4|429496729.5] "degree"  ASDM
 SG_ zipy_serialized_data_474_RL : 320|32@1- (0.1,0) [-102.4|429496729.5] "degree"  ASDM
 SG_ zipy_serialized_data_475_RL : 352|32@1- (0.1,0) [-102.4|429496729.5] "degree"  ASDM
 SG_ zipy_serialized_data_476_RL : 384|32@1- (0.1,0) [-102.4|429496729.5] "degree"  ASDM
 SG_ zipy_serialized_data_477_RL : 416|32@1- (0.1,0) [-102.4|429496729.5] "degree"  ASDM
 SG_ zipy_serialized_data_478_RL : 448|32@1- (0.1,0) [-102.4|429496729.5] "degree"  ASDM
 SG_ zipy_serialized_data_479_RL : 480|32@1- (0.1,0) [-102.4|429496729.5] "degree"  ASDM

BO_ 334 MB79_DETECTIONS_30_RL: 64 RSRL
 SG_ zipy_serialized_data_480_RL : 0|32@1- (0.1,0) [-102.4|429496729.5] "degree"  ASDM
 SG_ zipy_serialized_data_481_RL : 32|32@1- (0.1,0) [-102.4|429496729.5] "degree"  ASDM
 SG_ zipy_serialized_data_482_RL : 64|32@1- (0.1,0) [-102.4|429496729.5] "degree"  ASDM
 SG_ zipy_serialized_data_483_RL : 96|32@1- (0.1,0) [-102.4|429496729.5] "degree"  ASDM
 SG_ zipy_serialized_data_484_RL : 128|32@1- (0.1,0) [-102.4|429496729.5] "degree"  ASDM
 SG_ zipy_serialized_data_485_RL : 160|32@1- (0.1,0) [-102.4|429496729.5] "degree"  ASDM
 SG_ zipy_serialized_data_486_RL : 192|32@1- (0.1,0) [-102.4|429496729.5] "degree"  ASDM
 SG_ zipy_serialized_data_487_RL : 224|32@1- (0.1,0) [-102.4|429496729.5] "degree"  ASDM
 SG_ zipy_serialized_data_488_RL : 256|32@1- (0.1,0) [-102.4|429496729.5] "degree"  ASDM
 SG_ zipy_serialized_data_489_RL : 288|32@1- (0.1,0) [-102.4|429496729.5] "degree"  ASDM
 SG_ zipy_serialized_data_490_RL : 320|32@1- (0.1,0) [-102.4|429496729.5] "degree"  ASDM
 SG_ zipy_serialized_data_491_RL : 352|32@1- (0.1,0) [-102.4|429496729.5] "degree"  ASDM
 SG_ zipy_serialized_data_492_RL : 384|32@1- (0.1,0) [-102.4|429496729.5] "degree"  ASDM
 SG_ zipy_serialized_data_493_RL : 416|32@1- (0.1,0) [-102.4|429496729.5] "degree"  ASDM
 SG_ zipy_serialized_data_494_RL : 448|32@1- (0.1,0) [-102.4|429496729.5] "degree"  ASDM
 SG_ zipy_serialized_data_495_RL : 480|32@1- (0.1,0) [-102.4|429496729.5] "degree"  ASDM

BO_ 335 MB79_DETECTIONS_31_RL: 64 RSRL
 SG_ zipy_serialized_data_496_RL : 0|32@1- (0.1,0) [-102.4|429496729.5] "degree"  ASDM
 SG_ zipy_serialized_data_497_RL : 32|32@1- (0.1,0) [-102.4|429496729.5] "degree"  ASDM
 SG_ zipy_serialized_data_498_RL : 64|32@1- (0.1,0) [-102.4|429496729.5] "degree"  ASDM
 SG_ zipy_serialized_data_499_RL : 96|32@1- (0.1,0) [-102.4|429496729.5] "degree"  ASDM
 SG_ zipy_serialized_data_500_RL : 128|32@1- (0.1,0) [-102.4|429496729.5] "degree"  ASDM
 SG_ zipy_serialized_data_501_RL : 160|32@1- (0.1,0) [-102.4|429496729.5] "degree"  ASDM
 SG_ zipy_serialized_data_502_RL : 192|32@1- (0.1,0) [-102.4|429496729.5] "degree"  ASDM
 SG_ zipy_serialized_data_503_RL : 224|32@1- (0.1,0) [-102.4|429496729.5] "degree"  ASDM
 SG_ zipy_serialized_data_504_RL : 256|32@1- (0.1,0) [-102.4|429496729.5] "degree"  ASDM
 SG_ zipy_serialized_data_505_RL : 288|32@1- (0.1,0) [-102.4|429496729.5] "degree"  ASDM
 SG_ zipy_serialized_data_506_RL : 320|32@1- (0.1,0) [-102.4|429496729.5] "degree"  ASDM
 SG_ zipy_serialized_data_507_RL : 352|32@1- (0.1,0) [-102.4|429496729.5] "degree"  ASDM
 SG_ zipy_serialized_data_508_RL : 384|32@1- (0.1,0) [-102.4|429496729.5] "degree"  ASDM
 SG_ zipy_serialized_data_509_RL : 416|32@1- (0.1,0) [-102.4|429496729.5] "degree"  ASDM
 SG_ zipy_serialized_data_510_RL : 448|32@1- (0.1,0) [-102.4|429496729.5] "degree"  ASDM
 SG_ zipy_serialized_data_511_RL : 480|32@1- (0.1,0) [-102.4|429496729.5] "degree"  ASDM

BO_ 336 MB79_DETECTIONS_32_RL: 64 RSRL
 SG_ zipy_serialized_data_512_RL : 0|32@1- (0.1,0) [-102.4|429496729.5] "degree"  ASDM
 SG_ zipy_serialized_data_513_RL : 32|32@1- (0.1,0) [-102.4|429496729.5] "degree"  ASDM
 SG_ zipy_serialized_data_514_RL : 64|32@1- (0.1,0) [-102.4|429496729.5] "degree"  ASDM
 SG_ zipy_serialized_data_515_RL : 96|32@1- (0.1,0) [-102.4|429496729.5] "degree"  ASDM
 SG_ zipy_serialized_data_516_RL : 128|32@1- (0.1,0) [-102.4|429496729.5] "degree"  ASDM
 SG_ zipy_serialized_data_517_RL : 160|32@1- (0.1,0) [-102.4|429496729.5] "degree"  ASDM
 SG_ zipy_serialized_data_518_RL : 192|32@1- (0.1,0) [-102.4|429496729.5] "degree"  ASDM
 SG_ zipy_serialized_data_519_RL : 224|32@1- (0.1,0) [-102.4|429496729.5] "degree"  ASDM
 SG_ zipy_serialized_data_520_RL : 256|32@1- (0.1,0) [-102.4|429496729.5] "degree"  ASDM
 SG_ zipy_serialized_data_521_RL : 288|32@1- (0.1,0) [-102.4|429496729.5] "degree"  ASDM
 SG_ zipy_serialized_data_522_RL : 320|32@1- (0.1,0) [-102.4|429496729.5] "degree"  ASDM
 SG_ zipy_serialized_data_523_RL : 352|32@1- (0.1,0) [-102.4|429496729.5] "degree"  ASDM
 SG_ zipy_serialized_data_524_RL : 384|32@1- (0.1,0) [-102.4|429496729.5] "degree"  ASDM
 SG_ zipy_serialized_data_525_RL : 416|32@1- (0.1,0) [-102.4|429496729.5] "degree"  ASDM
 SG_ zipy_serialized_data_526_RL : 448|32@1- (0.1,0) [-102.4|429496729.5] "degree"  ASDM
 SG_ zipy_serialized_data_527_RL : 480|32@1- (0.1,0) [-102.4|429496729.5] "degree"  ASDM

BO_ 337 MB79_DETECTIONS_33_RL: 64 RSRL
 SG_ zipy_serialized_data_528_RL : 0|32@1- (0.1,0) [-102.4|429496729.5] "degree"  ASDM
 SG_ zipy_serialized_data_529_RL : 32|32@1- (0.1,0) [-102.4|429496729.5] "degree"  ASDM
 SG_ zipy_serialized_data_530_RL : 64|32@1- (0.1,0) [-102.4|429496729.5] "degree"  ASDM
 SG_ zipy_serialized_data_531_RL : 96|32@1- (0.1,0) [-102.4|429496729.5] "degree"  ASDM
 SG_ zipy_serialized_data_532_RL : 128|32@1- (0.1,0) [-102.4|429496729.5] "degree"  ASDM
 SG_ zipy_serialized_data_533_RL : 160|32@1- (0.1,0) [-102.4|429496729.5] "degree"  ASDM
 SG_ zipy_serialized_data_534_RL : 192|32@1- (0.1,0) [-102.4|429496729.5] "degree"  ASDM
 SG_ zipy_serialized_data_535_RL : 224|32@1- (0.1,0) [-102.4|429496729.5] "degree"  ASDM
 SG_ zipy_serialized_data_536_RL : 256|32@1- (0.1,0) [-102.4|429496729.5] "degree"  ASDM
 SG_ zipy_serialized_data_537_RL : 288|32@1- (0.1,0) [-102.4|429496729.5] "degree"  ASDM
 SG_ zipy_serialized_data_538_RL : 320|32@1- (0.1,0) [-102.4|429496729.5] "degree"  ASDM
 SG_ zipy_serialized_data_539_RL : 352|32@1- (0.1,0) [-102.4|429496729.5] "degree"  ASDM
 SG_ zipy_serialized_data_540_RL : 384|32@1- (0.1,0) [-102.4|429496729.5] "degree"  ASDM
 SG_ zipy_serialized_data_541_RL : 416|32@1- (0.1,0) [-102.4|429496729.5] "degree"  ASDM
 SG_ zipy_serialized_data_542_RL : 448|32@1- (0.1,0) [-102.4|429496729.5] "degree"  ASDM
 SG_ zipy_serialized_data_543_RL : 480|32@1- (0.1,0) [-102.4|429496729.5] "degree"  ASDM

BO_ 338 MB79_DETECTIONS_34_RL: 64 RSRL
 SG_ zipy_serialized_data_544_RL : 0|32@1- (0.1,0) [-102.4|429496729.5] "degree"  ASDM
 SG_ zipy_serialized_data_545_RL : 32|32@1- (0.1,0) [-102.4|429496729.5] "degree"  ASDM
 SG_ zipy_serialized_data_546_RL : 64|32@1- (0.1,0) [-102.4|429496729.5] "degree"  ASDM
 SG_ zipy_serialized_data_547_RL : 96|32@1- (0.1,0) [-102.4|429496729.5] "degree"  ASDM
 SG_ zipy_serialized_data_548_RL : 128|32@1- (0.1,0) [-102.4|429496729.5] "degree"  ASDM
 SG_ zipy_serialized_data_549_RL : 160|32@1- (0.1,0) [-102.4|429496729.5] "degree"  ASDM
 SG_ zipy_serialized_data_550_RL : 192|32@1- (0.1,0) [-102.4|429496729.5] "degree"  ASDM
 SG_ zipy_serialized_data_551_RL : 224|32@1- (0.1,0) [-102.4|429496729.5] "degree"  ASDM
 SG_ zipy_serialized_data_552_RL : 256|32@1- (0.1,0) [-102.4|429496729.5] "degree"  ASDM
 SG_ zipy_serialized_data_553_RL : 288|32@1- (0.1,0) [-102.4|429496729.5] "degree"  ASDM
 SG_ zipy_serialized_data_554_RL : 320|32@1- (0.1,0) [-102.4|429496729.5] "degree"  ASDM
 SG_ zipy_serialized_data_555_RL : 352|32@1- (0.1,0) [-102.4|429496729.5] "degree"  ASDM
 SG_ zipy_serialized_data_556_RL : 384|32@1- (0.1,0) [-102.4|429496729.5] "degree"  ASDM
 SG_ zipy_serialized_data_557_RL : 416|32@1- (0.1,0) [-102.4|429496729.5] "degree"  ASDM
 SG_ zipy_serialized_data_558_RL : 448|32@1- (0.1,0) [-102.4|429496729.5] "degree"  ASDM
 SG_ zipy_serialized_data_559_RL : 480|32@1- (0.1,0) [-102.4|429496729.5] "degree"  ASDM

BO_ 339 MB79_DETECTIONS_35_RL: 64 RSRL
 SG_ zipy_serialized_data_560_RL : 0|32@1- (0.1,0) [-102.4|429496729.5] "degree"  ASDM
 SG_ zipy_serialized_data_561_RL : 32|32@1- (0.1,0) [-102.4|429496729.5] "degree"  ASDM
 SG_ zipy_serialized_data_562_RL : 64|32@1- (0.1,0) [-102.4|429496729.5] "degree"  ASDM
 SG_ zipy_serialized_data_563_RL : 96|32@1- (0.1,0) [-102.4|429496729.5] "degree"  ASDM
 SG_ zipy_serialized_data_564_RL : 128|32@1- (0.1,0) [-102.4|429496729.5] "degree"  ASDM
 SG_ zipy_serialized_data_565_RL : 160|32@1- (0.1,0) [-102.4|429496729.5] "degree"  ASDM
 SG_ zipy_serialized_data_566_RL : 192|32@1- (0.1,0) [-102.4|429496729.5] "degree"  ASDM
 SG_ zipy_serialized_data_567_RL : 224|32@1- (0.1,0) [-102.4|429496729.5] "degree"  ASDM
 SG_ zipy_serialized_data_568_RL : 256|32@1- (0.1,0) [-102.4|429496729.5] "degree"  ASDM
 SG_ zipy_serialized_data_569_RL : 288|32@1- (0.1,0) [-102.4|429496729.5] "degree"  ASDM
 SG_ zipy_serialized_data_570_RL : 320|32@1- (0.1,0) [-102.4|429496729.5] "degree"  ASDM
 SG_ zipy_serialized_data_571_RL : 352|32@1- (0.1,0) [-102.4|429496729.5] "degree"  ASDM
 SG_ zipy_serialized_data_572_RL : 384|32@1- (0.1,0) [-102.4|429496729.5] "degree"  ASDM
 SG_ zipy_serialized_data_573_RL : 416|32@1- (0.1,0) [-102.4|429496729.5] "degree"  ASDM
 SG_ zipy_serialized_data_574_RL : 448|32@1- (0.1,0) [-102.4|429496729.5] "degree"  ASDM
 SG_ zipy_serialized_data_575_RL : 480|32@1- (0.1,0) [-102.4|429496729.5] "degree"  ASDM

BO_ 340 MB79_DETECTIONS_36_RL: 64 RSRL
 SG_ zipy_serialized_data_576_RL : 0|32@1- (0.1,0) [-102.4|429496729.5] "degree"  ASDM
 SG_ zipy_serialized_data_577_RL : 32|32@1- (0.1,0) [-102.4|429496729.5] "degree"  ASDM
 SG_ zipy_serialized_data_578_RL : 64|32@1- (0.1,0) [-102.4|429496729.5] "degree"  ASDM
 SG_ zipy_serialized_data_579_RL : 96|32@1- (0.1,0) [-102.4|429496729.5] "degree"  ASDM
 SG_ zipy_serialized_data_580_RL : 128|32@1- (0.1,0) [-102.4|429496729.5] "degree"  ASDM
 SG_ zipy_serialized_data_581_RL : 160|32@1- (0.1,0) [-102.4|429496729.5] "degree"  ASDM
 SG_ zipy_serialized_data_582_RL : 192|32@1- (0.1,0) [-102.4|429496729.5] "degree"  ASDM
 SG_ zipy_serialized_data_583_RL : 224|32@1- (0.1,0) [-102.4|429496729.5] "degree"  ASDM
 SG_ zipy_serialized_data_584_RL : 256|32@1- (0.1,0) [-102.4|429496729.5] "degree"  ASDM
 SG_ zipy_serialized_data_585_RL : 288|32@1- (0.1,0) [-102.4|429496729.5] "degree"  ASDM
 SG_ zipy_serialized_data_586_RL : 320|32@1- (0.1,0) [-102.4|429496729.5] "degree"  ASDM
 SG_ zipy_serialized_data_587_RL : 352|32@1- (0.1,0) [-102.4|429496729.5] "degree"  ASDM
 SG_ zipy_serialized_data_588_RL : 384|32@1- (0.1,0) [-102.4|429496729.5] "degree"  ASDM
 SG_ zipy_serialized_data_589_RL : 416|32@1- (0.1,0) [-102.4|429496729.5] "degree"  ASDM
 SG_ zipy_serialized_data_590_RL : 448|32@1- (0.1,0) [-102.4|429496729.5] "degree"  ASDM
 SG_ zipy_serialized_data_591_RL : 480|32@1- (0.1,0) [-102.4|429496729.5] "degree"  ASDM

BO_ 341 MB79_DETECTIONS_37_RL: 64 RSRL
 SG_ zipy_serialized_data_592_RL : 0|32@1- (0.1,0) [-102.4|429496729.5] "degree"  ASDM
 SG_ zipy_serialized_data_593_RL : 32|32@1- (0.1,0) [-102.4|429496729.5] "degree"  ASDM
 SG_ zipy_serialized_data_594_RL : 64|32@1- (0.1,0) [-102.4|429496729.5] "degree"  ASDM
 SG_ zipy_serialized_data_595_RL : 96|32@1- (0.1,0) [-102.4|429496729.5] "degree"  ASDM
 SG_ zipy_serialized_data_596_RL : 128|32@1- (0.1,0) [-102.4|429496729.5] "degree"  ASDM
 SG_ zipy_serialized_data_597_RL : 160|32@1- (0.1,0) [-102.4|429496729.5] "degree"  ASDM
 SG_ zipy_serialized_data_598_RL : 192|32@1- (0.1,0) [-102.4|429496729.5] "degree"  ASDM
 SG_ zipy_serialized_data_599_RL : 224|32@1- (0.1,0) [-102.4|429496729.5] "degree"  ASDM
 SG_ zipy_serialized_data_600_RL : 256|32@1- (0.1,0) [-102.4|429496729.5] "degree"  ASDM
 SG_ zipy_serialized_data_601_RL : 288|32@1- (0.1,0) [-102.4|429496729.5] "degree"  ASDM
 SG_ zipy_serialized_data_602_RL : 320|32@1- (0.1,0) [-102.4|429496729.5] "degree"  ASDM
 SG_ zipy_serialized_data_603_RL : 352|32@1- (0.1,0) [-102.4|429496729.5] "degree"  ASDM
 SG_ zipy_serialized_data_604_RL : 384|32@1- (0.1,0) [-102.4|429496729.5] "degree"  ASDM
 SG_ zipy_serialized_data_605_RL : 416|32@1- (0.1,0) [-102.4|429496729.5] "degree"  ASDM
 SG_ zipy_serialized_data_606_RL : 448|32@1- (0.1,0) [-102.4|429496729.5] "degree"  ASDM
 SG_ zipy_serialized_data_607_RL : 480|32@1- (0.1,0) [-102.4|429496729.5] "degree"  ASDM

BO_ 342 MB79_DETECTIONS_38_RL: 64 RSRL
 SG_ zipy_serialized_data_608_RL : 0|32@1- (0.1,0) [-102.4|429496729.5] "degree"  ASDM
 SG_ zipy_serialized_data_609_RL : 32|32@1- (0.1,0) [-102.4|429496729.5] "degree"  ASDM
 SG_ zipy_serialized_data_610_RL : 64|32@1- (0.1,0) [-102.4|429496729.5] "degree"  ASDM
 SG_ zipy_serialized_data_611_RL : 96|32@1- (0.1,0) [-102.4|429496729.5] "degree"  ASDM
 SG_ zipy_serialized_data_612_RL : 128|32@1- (0.1,0) [-102.4|429496729.5] "degree"  ASDM
 SG_ zipy_serialized_data_613_RL : 160|32@1- (0.1,0) [-102.4|429496729.5] "degree"  ASDM
 SG_ zipy_serialized_data_614_RL : 192|32@1- (0.1,0) [-102.4|429496729.5] "degree"  ASDM
 SG_ zipy_serialized_data_615_RL : 224|32@1- (0.1,0) [-102.4|429496729.5] "degree"  ASDM
 SG_ zipy_serialized_data_616_RL : 256|32@1- (0.1,0) [-102.4|429496729.5] "degree"  ASDM
 SG_ zipy_serialized_data_617_RL : 288|32@1- (0.1,0) [-102.4|429496729.5] "degree"  ASDM
 SG_ zipy_serialized_data_618_RL : 320|32@1- (0.1,0) [-102.4|429496729.5] "degree"  ASDM
 SG_ zipy_serialized_data_619_RL : 352|32@1- (0.1,0) [-102.4|429496729.5] "degree"  ASDM
 SG_ zipy_serialized_data_620_RL : 384|32@1- (0.1,0) [-102.4|429496729.5] "degree"  ASDM
 SG_ zipy_serialized_data_621_RL : 416|32@1- (0.1,0) [-102.4|429496729.5] "degree"  ASDM
 SG_ zipy_serialized_data_622_RL : 448|32@1- (0.1,0) [-102.4|429496729.5] "degree"  ASDM
 SG_ zipy_serialized_data_623_RL : 480|32@1- (0.1,0) [-102.4|429496729.5] "degree"  ASDM

BO_ 343 MB79_DETECTIONS_39_RL: 64 RSRL
 SG_ zipy_serialized_data_624_RL : 0|32@1- (0.1,0) [-102.4|429496729.5] "degree"  ASDM
 SG_ zipy_serialized_data_625_RL : 32|32@1- (0.1,0) [-102.4|429496729.5] "degree"  ASDM
 SG_ zipy_serialized_data_626_RL : 64|32@1- (0.1,0) [-102.4|429496729.5] "degree"  ASDM
 SG_ zipy_serialized_data_627_RL : 96|32@1- (0.1,0) [-102.4|429496729.5] "degree"  ASDM
 SG_ zipy_serialized_data_628_RL : 128|32@1- (0.1,0) [-102.4|429496729.5] "degree"  ASDM
 SG_ zipy_serialized_data_629_RL : 160|32@1- (0.1,0) [-102.4|429496729.5] "degree"  ASDM
 SG_ zipy_serialized_data_630_RL : 192|32@1- (0.1,0) [-102.4|429496729.5] "degree"  ASDM
 SG_ zipy_serialized_data_631_RL : 224|32@1- (0.1,0) [-102.4|429496729.5] "degree"  ASDM
 SG_ zipy_serialized_data_632_RL : 256|32@1- (0.1,0) [-102.4|429496729.5] "degree"  ASDM
 SG_ zipy_serialized_data_633_RL : 288|32@1- (0.1,0) [-102.4|429496729.5] "degree"  ASDM
 SG_ zipy_serialized_data_634_RL : 320|32@1- (0.1,0) [-102.4|429496729.5] "degree"  ASDM
 SG_ zipy_serialized_data_635_RL : 352|32@1- (0.1,0) [-102.4|429496729.5] "degree"  ASDM
 SG_ zipy_serialized_data_636_RL : 384|32@1- (0.1,0) [-102.4|429496729.5] "degree"  ASDM
 SG_ zipy_serialized_data_637_RL : 416|32@1- (0.1,0) [-102.4|429496729.5] "degree"  ASDM
 SG_ zipy_serialized_data_638_RL : 448|32@1- (0.1,0) [-102.4|429496729.5] "degree"  ASDM
 SG_ zipy_serialized_data_639_RL : 480|32@1- (0.1,0) [-102.4|429496729.5] "degree"  ASDM

BO_ 344 MB79_DETECTIONS_40_RL: 64 RSRL
 SG_ zipy_serialized_data_640_RL : 0|32@1- (0.1,0) [-102.4|429496729.5] "degree"  ASDM
 SG_ zipy_serialized_data_641_RL : 32|32@1- (0.1,0) [-102.4|429496729.5] "degree"  ASDM
 SG_ zipy_serialized_data_642_RL : 64|32@1- (0.1,0) [-102.4|429496729.5] "degree"  ASDM
 SG_ zipy_serialized_data_643_RL : 96|32@1- (0.1,0) [-102.4|429496729.5] "degree"  ASDM
 SG_ zipy_serialized_data_644_RL : 128|32@1- (0.1,0) [-102.4|429496729.5] "degree"  ASDM
 SG_ zipy_serialized_data_645_RL : 160|32@1- (0.1,0) [-102.4|429496729.5] "degree"  ASDM
 SG_ zipy_serialized_data_646_RL : 192|32@1- (0.1,0) [-102.4|429496729.5] "degree"  ASDM
 SG_ zipy_serialized_data_647_RL : 224|32@1- (0.1,0) [-102.4|429496729.5] "degree"  ASDM
 SG_ zipy_serialized_data_648_RL : 256|32@1- (0.1,0) [-102.4|429496729.5] "degree"  ASDM
 SG_ zipy_serialized_data_649_RL : 288|32@1- (0.1,0) [-102.4|429496729.5] "degree"  ASDM
 SG_ zipy_serialized_data_650_RL : 320|32@1- (0.1,0) [-102.4|429496729.5] "degree"  ASDM
 SG_ zipy_serialized_data_651_RL : 352|32@1- (0.1,0) [-102.4|429496729.5] "degree"  ASDM
 SG_ zipy_serialized_data_652_RL : 384|32@1- (0.1,0) [-102.4|429496729.5] "degree"  ASDM
 SG_ zipy_serialized_data_653_RL : 416|32@1- (0.1,0) [-102.4|429496729.5] "degree"  ASDM
 SG_ zipy_serialized_data_654_RL : 448|32@1- (0.1,0) [-102.4|429496729.5] "degree"  ASDM
 SG_ zipy_serialized_data_655_RL : 480|32@1- (0.1,0) [-102.4|429496729.5] "degree"  ASDM

BO_ 345 MB79_DETECTIONS_41_RL: 64 RSRL
 SG_ zipy_serialized_data_656_RL : 0|32@1- (0.1,0) [-102.4|429496729.5] "degree"  ASDM
 SG_ zipy_serialized_data_657_RL : 32|32@1- (0.1,0) [-102.4|429496729.5] "degree"  ASDM
 SG_ zipy_serialized_data_658_RL : 64|32@1- (0.1,0) [-102.4|429496729.5] "degree"  ASDM
 SG_ zipy_serialized_data_659_RL : 96|32@1- (0.1,0) [-102.4|429496729.5] "degree"  ASDM
 SG_ zipy_serialized_data_660_RL : 128|32@1- (0.1,0) [-102.4|429496729.5] "degree"  ASDM
 SG_ zipy_serialized_data_661_RL : 160|32@1- (0.1,0) [-102.4|429496729.5] "degree"  ASDM
 SG_ zipy_serialized_data_662_RL : 192|32@1- (0.1,0) [-102.4|429496729.5] "degree"  ASDM
 SG_ zipy_serialized_data_663_RL : 224|32@1- (0.1,0) [-102.4|429496729.5] "degree"  ASDM
 SG_ zipy_serialized_data_664_RL : 256|32@1- (0.1,0) [-102.4|429496729.5] "degree"  ASDM
 SG_ zipy_serialized_data_665_RL : 288|32@1- (0.1,0) [-102.4|429496729.5] "degree"  ASDM
 SG_ zipy_serialized_data_666_RL : 320|32@1- (0.1,0) [-102.4|429496729.5] "degree"  ASDM
 SG_ zipy_serialized_data_667_RL : 352|32@1- (0.1,0) [-102.4|429496729.5] "degree"  ASDM
 SG_ zipy_serialized_data_668_RL : 384|32@1- (0.1,0) [-102.4|429496729.5] "degree"  ASDM
 SG_ zipy_serialized_data_669_RL : 416|32@1- (0.1,0) [-102.4|429496729.5] "degree"  ASDM
 SG_ zipy_serialized_data_670_RL : 448|32@1- (0.1,0) [-102.4|429496729.5] "degree"  ASDM
 SG_ zipy_serialized_data_671_RL : 480|32@1- (0.1,0) [-102.4|429496729.5] "degree"  ASDM

BO_ 346 MB79_DETECTIONS_42_RL: 64 RSRL
 SG_ zipy_serialized_data_672_RL : 0|32@1- (0.1,0) [-102.4|429496729.5] "degree"  ASDM
 SG_ zipy_serialized_data_673_RL : 32|32@1- (0.1,0) [-102.4|429496729.5] "degree"  ASDM
 SG_ zipy_serialized_data_674_RL : 64|32@1- (0.1,0) [-102.4|429496729.5] "degree"  ASDM
 SG_ zipy_serialized_data_675_RL : 96|32@1- (0.1,0) [-102.4|429496729.5] "degree"  ASDM
 SG_ zipy_serialized_data_676_RL : 128|32@1- (0.1,0) [-102.4|429496729.5] "degree"  ASDM
 SG_ zipy_serialized_data_677_RL : 160|32@1- (0.1,0) [-102.4|429496729.5] "degree"  ASDM
 SG_ zipy_serialized_data_678_RL : 192|32@1- (0.1,0) [-102.4|429496729.5] "degree"  ASDM
 SG_ zipy_serialized_data_679_RL : 224|32@1- (0.1,0) [-102.4|429496729.5] "degree"  ASDM
 SG_ zipy_serialized_data_680_RL : 256|32@1- (0.1,0) [-102.4|429496729.5] "degree"  ASDM
 SG_ zipy_serialized_data_681_RL : 288|32@1- (0.1,0) [-102.4|429496729.5] "degree"  ASDM
 SG_ zipy_serialized_data_682_RL : 320|32@1- (0.1,0) [-102.4|429496729.5] "degree"  ASDM
 SG_ zipy_serialized_data_683_RL : 352|32@1- (0.1,0) [-102.4|429496729.5] "degree"  ASDM
 SG_ zipy_serialized_data_684_RL : 384|32@1- (0.1,0) [-102.4|429496729.5] "degree"  ASDM
 SG_ zipy_serialized_data_685_RL : 416|32@1- (0.1,0) [-102.4|429496729.5] "degree"  ASDM
 SG_ zipy_serialized_data_686_RL : 448|32@1- (0.1,0) [-102.4|429496729.5] "degree"  ASDM
 SG_ zipy_serialized_data_687_RL : 480|32@1- (0.1,0) [-102.4|429496729.5] "degree"  ASDM

BO_ 347 MB79_DETECTIONS_43_RL: 64 RSRL
 SG_ zipy_serialized_data_688_RL : 0|32@1- (0.1,0) [-102.4|429496729.5] "degree"  ASDM
 SG_ zipy_serialized_data_689_RL : 32|32@1- (0.1,0) [-102.4|429496729.5] "degree"  ASDM
 SG_ zipy_serialized_data_690_RL : 64|32@1- (0.1,0) [-102.4|429496729.5] "degree"  ASDM
 SG_ zipy_serialized_data_691_RL : 96|32@1- (0.1,0) [-102.4|429496729.5] "degree"  ASDM
 SG_ zipy_serialized_data_692_RL : 128|32@1- (0.1,0) [-102.4|429496729.5] "degree"  ASDM
 SG_ zipy_serialized_data_693_RL : 160|32@1- (0.1,0) [-102.4|429496729.5] "degree"  ASDM
 SG_ zipy_serialized_data_694_RL : 192|32@1- (0.1,0) [-102.4|429496729.5] "degree"  ASDM
 SG_ zipy_serialized_data_695_RL : 224|32@1- (0.1,0) [-102.4|429496729.5] "degree"  ASDM
 SG_ zipy_serialized_data_696_RL : 256|32@1- (0.1,0) [-102.4|429496729.5] "degree"  ASDM
 SG_ zipy_serialized_data_697_RL : 288|32@1- (0.1,0) [-102.4|429496729.5] "degree"  ASDM
 SG_ zipy_serialized_data_698_RL : 320|32@1- (0.1,0) [-102.4|429496729.5] "degree"  ASDM
 SG_ zipy_serialized_data_699_RL : 352|32@1- (0.1,0) [-102.4|429496729.5] "degree"  ASDM
 SG_ zipy_serialized_data_700_RL : 384|32@1- (0.1,0) [-102.4|429496729.5] "degree"  ASDM
 SG_ zipy_serialized_data_701_RL : 416|32@1- (0.1,0) [-102.4|429496729.5] "degree"  ASDM
 SG_ zipy_serialized_data_702_RL : 448|32@1- (0.1,0) [-102.4|429496729.5] "degree"  ASDM
 SG_ zipy_serialized_data_703_RL : 480|32@1- (0.1,0) [-102.4|429496729.5] "degree"  ASDM

BO_ 348 MB79_DETECTIONS_44_RL: 64 RSRL
 SG_ zipy_serialized_data_704_RL : 0|32@1- (0.1,0) [-102.4|429496729.5] "degree"  ASDM
 SG_ zipy_serialized_data_705_RL : 32|32@1- (0.1,0) [-102.4|429496729.5] "degree"  ASDM
 SG_ zipy_serialized_data_706_RL : 64|32@1- (0.1,0) [-102.4|429496729.5] "degree"  ASDM
 SG_ zipy_serialized_data_707_RL : 96|32@1- (0.1,0) [-102.4|429496729.5] "degree"  ASDM
 SG_ zipy_serialized_data_708_RL : 128|32@1- (0.1,0) [-102.4|429496729.5] "degree"  ASDM
 SG_ zipy_serialized_data_709_RL : 160|32@1- (0.1,0) [-102.4|429496729.5] "degree"  ASDM
 SG_ zipy_serialized_data_710_RL : 192|32@1- (0.1,0) [-102.4|429496729.5] "degree"  ASDM
 SG_ zipy_serialized_data_711_RL : 224|32@1- (0.1,0) [-102.4|429496729.5] "degree"  ASDM
 SG_ zipy_serialized_data_712_RL : 256|32@1- (0.1,0) [-102.4|429496729.5] "degree"  ASDM
 SG_ zipy_serialized_data_713_RL : 288|32@1- (0.1,0) [-102.4|429496729.5] "degree"  ASDM
 SG_ zipy_serialized_data_714_RL : 320|32@1- (0.1,0) [-102.4|429496729.5] "degree"  ASDM
 SG_ zipy_serialized_data_715_RL : 352|32@1- (0.1,0) [-102.4|429496729.5] "degree"  ASDM
 SG_ zipy_serialized_data_716_RL : 384|32@1- (0.1,0) [-102.4|429496729.5] "degree"  ASDM
 SG_ zipy_serialized_data_717_RL : 416|32@1- (0.1,0) [-102.4|429496729.5] "degree"  ASDM
 SG_ zipy_serialized_data_718_RL : 448|32@1- (0.1,0) [-102.4|429496729.5] "degree"  ASDM
 SG_ zipy_serialized_data_719_RL : 480|32@1- (0.1,0) [-102.4|429496729.5] "degree"  ASDM

BO_ 349 MB79_DETECTIONS_45_RL: 64 RSRL
 SG_ zipy_serialized_data_720_RL : 0|32@1- (0.1,0) [-102.4|429496729.5] "degree"  ASDM
 SG_ zipy_serialized_data_721_RL : 32|32@1- (0.1,0) [-102.4|429496729.5] "degree"  ASDM
 SG_ zipy_serialized_data_722_RL : 64|32@1- (0.1,0) [-102.4|429496729.5] "degree"  ASDM
 SG_ zipy_serialized_data_723_RL : 96|32@1- (0.1,0) [-102.4|429496729.5] "degree"  ASDM
 SG_ zipy_serialized_data_724_RL : 128|32@1- (0.1,0) [-102.4|429496729.5] "degree"  ASDM
 SG_ zipy_serialized_data_725_RL : 160|32@1- (0.1,0) [-102.4|429496729.5] "degree"  ASDM
 SG_ zipy_serialized_data_726_RL : 192|32@1- (0.1,0) [-102.4|429496729.5] "degree"  ASDM
 SG_ zipy_serialized_data_727_RL : 224|32@1- (0.1,0) [-102.4|429496729.5] "degree"  ASDM
 SG_ zipy_serialized_data_728_RL : 256|32@1- (0.1,0) [-102.4|429496729.5] "degree"  ASDM
 SG_ zipy_serialized_data_729_RL : 288|32@1- (0.1,0) [-102.4|429496729.5] "degree"  ASDM
 SG_ zipy_serialized_data_730_RL : 320|32@1- (0.1,0) [-102.4|429496729.5] "degree"  ASDM
 SG_ zipy_serialized_data_731_RL : 352|32@1- (0.1,0) [-102.4|429496729.5] "degree"  ASDM
 SG_ zipy_serialized_data_732_RL : 384|32@1- (0.1,0) [-102.4|429496729.5] "degree"  ASDM
 SG_ zipy_serialized_data_733_RL : 416|32@1- (0.1,0) [-102.4|429496729.5] "degree"  ASDM
 SG_ zipy_serialized_data_734_RL : 448|32@1- (0.1,0) [-102.4|429496729.5] "degree"  ASDM
 SG_ zipy_serialized_data_735_RL : 480|32@1- (0.1,0) [-102.4|429496729.5] "degree"  ASDM

BO_ 350 MB79_DETECTIONS_46_RL: 64 RSRL
 SG_ zipy_serialized_data_736_RL : 0|32@1- (0.1,0) [-102.4|429496729.5] "degree"  ASDM
 SG_ zipy_serialized_data_737_RL : 32|32@1- (0.1,0) [-102.4|429496729.5] "degree"  ASDM
 SG_ zipy_serialized_data_738_RL : 64|32@1- (0.1,0) [-102.4|429496729.5] "degree"  ASDM
 SG_ zipy_serialized_data_739_RL : 96|32@1- (0.1,0) [-102.4|429496729.5] "degree"  ASDM
 SG_ zipy_serialized_data_740_RL : 128|32@1- (0.1,0) [-102.4|429496729.5] "degree"  ASDM
 SG_ zipy_serialized_data_741_RL : 160|32@1- (0.1,0) [-102.4|429496729.5] "degree"  ASDM
 SG_ zipy_serialized_data_742_RL : 192|32@1- (0.1,0) [-102.4|429496729.5] "degree"  ASDM
 SG_ zipy_serialized_data_743_RL : 224|32@1- (0.1,0) [-102.4|429496729.5] "degree"  ASDM
 SG_ zipy_serialized_data_744_RL : 256|32@1- (0.1,0) [-102.4|429496729.5] "degree"  ASDM
 SG_ zipy_serialized_data_745_RL : 288|32@1- (0.1,0) [-102.4|429496729.5] "degree"  ASDM
 SG_ zipy_serialized_data_746_RL : 320|32@1- (0.1,0) [-102.4|429496729.5] "degree"  ASDM
 SG_ zipy_serialized_data_747_RL : 352|32@1- (0.1,0) [-102.4|429496729.5] "degree"  ASDM
 SG_ zipy_serialized_data_748_RL : 384|32@1- (0.1,0) [-102.4|429496729.5] "degree"  ASDM
 SG_ zipy_serialized_data_749_RL : 416|32@1- (0.1,0) [-102.4|429496729.5] "degree"  ASDM
 SG_ zipy_serialized_data_750_RL : 448|32@1- (0.1,0) [-102.4|429496729.5] "degree"  ASDM
 SG_ zipy_serialized_data_751_RL : 480|32@1- (0.1,0) [-102.4|429496729.5] "degree"  ASDM

BO_ 351 MB79_DETECTIONS_47_RL: 64 RSRL
 SG_ zipy_serialized_data_752_RL : 0|32@1- (0.1,0) [-102.4|429496729.5] "degree"  ASDM
 SG_ zipy_serialized_data_753_RL : 32|32@1- (0.1,0) [-102.4|429496729.5] "degree"  ASDM
 SG_ zipy_serialized_data_754_RL : 64|32@1- (0.1,0) [-102.4|429496729.5] "degree"  ASDM
 SG_ zipy_serialized_data_755_RL : 96|32@1- (0.1,0) [-102.4|429496729.5] "degree"  ASDM
 SG_ zipy_serialized_data_756_RL : 128|32@1- (0.1,0) [-102.4|429496729.5] "degree"  ASDM
 SG_ zipy_serialized_data_757_RL : 160|32@1- (0.1,0) [-102.4|429496729.5] "degree"  ASDM
 SG_ zipy_serialized_data_758_RL : 192|32@1- (0.1,0) [-102.4|429496729.5] "degree"  ASDM
 SG_ zipy_serialized_data_759_RL : 224|32@1- (0.1,0) [-102.4|429496729.5] "degree"  ASDM
 SG_ zipy_serialized_data_760_RL : 256|32@1- (0.1,0) [-102.4|429496729.5] "degree"  ASDM
 SG_ zipy_serialized_data_761_RL : 288|32@1- (0.1,0) [-102.4|429496729.5] "degree"  ASDM
 SG_ zipy_serialized_data_762_RL : 320|32@1- (0.1,0) [-102.4|429496729.5] "degree"  ASDM
 SG_ zipy_serialized_data_763_RL : 352|32@1- (0.1,0) [-102.4|429496729.5] "degree"  ASDM
 SG_ zipy_serialized_data_764_RL : 384|32@1- (0.1,0) [-102.4|429496729.5] "degree"  ASDM
 SG_ zipy_serialized_data_765_RL : 416|32@1- (0.1,0) [-102.4|429496729.5] "degree"  ASDM
 SG_ zipy_serialized_data_766_RL : 448|32@1- (0.1,0) [-102.4|429496729.5] "degree"  ASDM
 SG_ zipy_serialized_data_767_RL : 480|32@1- (0.1,0) [-102.4|429496729.5] "degree"  ASDM

BO_ 352 MB79_DETECTIONS_48_RL: 64 RSRL
 SG_ zipy_serialized_data_768_RL : 0|32@1- (0.1,0) [-102.4|429496729.5] "degree"  ASDM
 SG_ zipy_serialized_data_769_RL : 32|32@1- (0.1,0) [-102.4|429496729.5] "degree"  ASDM
 SG_ zipy_serialized_data_770_RL : 64|32@1- (0.1,0) [-102.4|429496729.5] "degree"  ASDM
 SG_ zipy_serialized_data_771_RL : 96|32@1- (0.1,0) [-102.4|429496729.5] "degree"  ASDM
 SG_ zipy_serialized_data_772_RL : 128|32@1- (0.1,0) [-102.4|429496729.5] "degree"  ASDM
 SG_ zipy_serialized_data_773_RL : 160|32@1- (0.1,0) [-102.4|429496729.5] "degree"  ASDM
 SG_ zipy_serialized_data_774_RL : 192|32@1- (0.1,0) [-102.4|429496729.5] "degree"  ASDM
 SG_ zipy_serialized_data_775_RL : 224|32@1- (0.1,0) [-102.4|429496729.5] "degree"  ASDM
 SG_ zipy_serialized_data_776_RL : 256|32@1- (0.1,0) [-102.4|429496729.5] "degree"  ASDM
 SG_ zipy_serialized_data_777_RL : 288|32@1- (0.1,0) [-102.4|429496729.5] "degree"  ASDM
 SG_ zipy_serialized_data_778_RL : 320|32@1- (0.1,0) [-102.4|429496729.5] "degree"  ASDM
 SG_ zipy_serialized_data_779_RL : 352|32@1- (0.1,0) [-102.4|429496729.5] "degree"  ASDM
 SG_ zipy_serialized_data_780_RL : 384|32@1- (0.1,0) [-102.4|429496729.5] "degree"  ASDM
 SG_ zipy_serialized_data_781_RL : 416|32@1- (0.1,0) [-102.4|429496729.5] "degree"  ASDM
 SG_ zipy_serialized_data_782_RL : 448|32@1- (0.1,0) [-102.4|429496729.5] "degree"  ASDM
 SG_ zipy_serialized_data_783_RL : 480|32@1- (0.1,0) [-102.4|429496729.5] "degree"  ASDM

BO_ 353 MB79_DETECTIONS_49_RL: 64 RSRL
 SG_ zipy_serialized_data_784_RL : 0|32@1- (0.1,0) [-102.4|429496729.5] "degree"  ASDM
 SG_ zipy_serialized_data_785_RL : 32|32@1- (0.1,0) [-102.4|429496729.5] "degree"  ASDM
 SG_ zipy_serialized_data_786_RL : 64|32@1- (0.1,0) [-102.4|429496729.5] "degree"  ASDM
 SG_ zipy_serialized_data_787_RL : 96|32@1- (0.1,0) [-102.4|429496729.5] "degree"  ASDM
 SG_ zipy_serialized_data_788_RL : 128|32@1- (0.1,0) [-102.4|429496729.5] "degree"  ASDM
 SG_ zipy_serialized_data_789_RL : 160|32@1- (0.1,0) [-102.4|429496729.5] "degree"  ASDM
 SG_ zipy_serialized_data_790_RL : 192|32@1- (0.1,0) [-102.4|429496729.5] "degree"  ASDM
 SG_ zipy_serialized_data_791_RL : 224|32@1- (0.1,0) [-102.4|429496729.5] "degree"  ASDM
 SG_ zipy_serialized_data_792_RL : 256|32@1- (0.1,0) [-102.4|429496729.5] "degree"  ASDM
 SG_ zipy_serialized_data_793_RL : 288|32@1- (0.1,0) [-102.4|429496729.5] "degree"  ASDM
 SG_ zipy_serialized_data_794_RL : 320|32@1- (0.1,0) [-102.4|429496729.5] "degree"  ASDM
 SG_ zipy_serialized_data_795_RL : 352|32@1- (0.1,0) [-102.4|429496729.5] "degree"  ASDM
 SG_ zipy_serialized_data_796_RL : 384|32@1- (0.1,0) [-102.4|429496729.5] "degree"  ASDM
 SG_ zipy_serialized_data_797_RL : 416|32@1- (0.1,0) [-102.4|429496729.5] "degree"  ASDM
 SG_ zipy_serialized_data_798_RL : 448|32@1- (0.1,0) [-102.4|429496729.5] "degree"  ASDM
 SG_ zipy_serialized_data_799_RL : 480|32@1- (0.1,0) [-102.4|429496729.5] "degree"  ASDM

BO_ 354 MB79_DETECTIONS_50_RL: 64 RSRL
 SG_ zipy_serialized_data_800_RL : 0|32@1- (0.1,0) [-102.4|429496729.5] "degree"  ASDM
 SG_ zipy_serialized_data_801_RL : 32|32@1- (0.1,0) [-102.4|429496729.5] "degree"  ASDM
 SG_ zipy_serialized_data_802_RL : 64|32@1- (0.1,0) [-102.4|429496729.5] "degree"  ASDM
 SG_ zipy_serialized_data_803_RL : 96|32@1- (0.1,0) [-102.4|429496729.5] "degree"  ASDM
 SG_ zipy_serialized_data_804_RL : 128|32@1- (0.1,0) [-102.4|429496729.5] "degree"  ASDM
 SG_ zipy_serialized_data_805_RL : 160|32@1- (0.1,0) [-102.4|429496729.5] "degree"  ASDM
 SG_ zipy_serialized_data_806_RL : 192|32@1- (0.1,0) [-102.4|429496729.5] "degree"  ASDM
 SG_ zipy_serialized_data_807_RL : 224|32@1- (0.1,0) [-102.4|429496729.5] "degree"  ASDM
 SG_ zipy_serialized_data_808_RL : 256|32@1- (0.1,0) [-102.4|429496729.5] "degree"  ASDM
 SG_ zipy_serialized_data_809_RL : 288|32@1- (0.1,0) [-102.4|429496729.5] "degree"  ASDM
 SG_ zipy_serialized_data_810_RL : 320|32@1- (0.1,0) [-102.4|429496729.5] "degree"  ASDM
 SG_ zipy_serialized_data_811_RL : 352|32@1- (0.1,0) [-102.4|429496729.5] "degree"  ASDM
 SG_ zipy_serialized_data_812_RL : 384|32@1- (0.1,0) [-102.4|429496729.5] "degree"  ASDM
 SG_ zipy_serialized_data_813_RL : 416|32@1- (0.1,0) [-102.4|429496729.5] "degree"  ASDM
 SG_ zipy_serialized_data_814_RL : 448|32@1- (0.1,0) [-102.4|429496729.5] "degree"  ASDM
 SG_ zipy_serialized_data_815_RL : 480|32@1- (0.1,0) [-102.4|429496729.5] "degree"  ASDM

BO_ 355 MB79_DETECTIONS_51_RL: 64 RSRL
 SG_ zipy_serialized_data_816_RL : 0|32@1- (0.1,0) [-102.4|429496729.5] "degree"  ASDM
 SG_ zipy_serialized_data_817_RL : 32|32@1- (0.1,0) [-102.4|429496729.5] "degree"  ASDM
 SG_ zipy_serialized_data_818_RL : 64|32@1- (0.1,0) [-102.4|429496729.5] "degree"  ASDM
 SG_ zipy_serialized_data_819_RL : 96|32@1- (0.1,0) [-102.4|429496729.5] "degree"  ASDM
 SG_ zipy_serialized_data_820_RL : 128|32@1- (0.1,0) [-102.4|429496729.5] "degree"  ASDM
 SG_ zipy_serialized_data_821_RL : 160|32@1- (0.1,0) [-102.4|429496729.5] "degree"  ASDM
 SG_ zipy_serialized_data_822_RL : 192|32@1- (0.1,0) [-102.4|429496729.5] "degree"  ASDM
 SG_ zipy_serialized_data_823_RL : 224|32@1- (0.1,0) [-102.4|429496729.5] "degree"  ASDM
 SG_ zipy_serialized_data_824_RL : 256|32@1- (0.1,0) [-102.4|429496729.5] "degree"  ASDM
 SG_ zipy_serialized_data_825_RL : 288|32@1- (0.1,0) [-102.4|429496729.5] "degree"  ASDM
 SG_ zipy_serialized_data_826_RL : 320|32@1- (0.1,0) [-102.4|429496729.5] "degree"  ASDM
 SG_ zipy_serialized_data_827_RL : 352|32@1- (0.1,0) [-102.4|429496729.5] "degree"  ASDM
 SG_ zipy_serialized_data_828_RL : 384|32@1- (0.1,0) [-102.4|429496729.5] "degree"  ASDM
 SG_ zipy_serialized_data_829_RL : 416|32@1- (0.1,0) [-102.4|429496729.5] "degree"  ASDM
 SG_ zipy_serialized_data_830_RL : 448|32@1- (0.1,0) [-102.4|429496729.5] "degree"  ASDM
 SG_ zipy_serialized_data_831_RL : 480|32@1- (0.1,0) [-102.4|429496729.5] "degree"  ASDM

BO_ 356 MB79_DETECTIONS_52_RL: 64 RSRL
 SG_ zipy_serialized_data_832_RL : 0|32@1- (0.1,0) [-102.4|429496729.5] "degree"  ASDM
 SG_ zipy_serialized_data_833_RL : 32|32@1- (0.1,0) [-102.4|429496729.5] "degree"  ASDM
 SG_ zipy_serialized_data_834_RL : 64|32@1- (0.1,0) [-102.4|429496729.5] "degree"  ASDM
 SG_ zipy_serialized_data_835_RL : 96|32@1- (0.1,0) [-102.4|429496729.5] "degree"  ASDM
 SG_ zipy_serialized_data_836_RL : 128|32@1- (0.1,0) [-102.4|429496729.5] "degree"  ASDM
 SG_ zipy_serialized_data_837_RL : 160|32@1- (0.1,0) [-102.4|429496729.5] "degree"  ASDM
 SG_ zipy_serialized_data_838_RL : 192|32@1- (0.1,0) [-102.4|429496729.5] "degree"  ASDM
 SG_ zipy_serialized_data_839_RL : 224|32@1- (0.1,0) [-102.4|429496729.5] "degree"  ASDM
 SG_ zipy_serialized_data_840_RL : 256|32@1- (0.1,0) [-102.4|429496729.5] "degree"  ASDM
 SG_ zipy_serialized_data_841_RL : 288|32@1- (0.1,0) [-102.4|429496729.5] "degree"  ASDM
 SG_ zipy_serialized_data_842_RL : 320|32@1- (0.1,0) [-102.4|429496729.5] "degree"  ASDM
 SG_ zipy_serialized_data_843_RL : 352|32@1- (0.1,0) [-102.4|429496729.5] "degree"  ASDM
 SG_ zipy_serialized_data_844_RL : 384|32@1- (0.1,0) [-102.4|429496729.5] "degree"  ASDM
 SG_ zipy_serialized_data_845_RL : 416|32@1- (0.1,0) [-102.4|429496729.5] "degree"  ASDM
 SG_ zipy_serialized_data_846_RL : 448|32@1- (0.1,0) [-102.4|429496729.5] "degree"  ASDM
 SG_ zipy_serialized_data_847_RL : 480|32@1- (0.1,0) [-102.4|429496729.5] "degree"  ASDM

BO_ 357 MB79_DETECTIONS_53_RL: 64 RSRL
 SG_ zipy_serialized_data_848_RL : 0|32@1- (0.1,0) [-102.4|429496729.5] "degree"  ASDM
 SG_ zipy_serialized_data_849_RL : 32|32@1- (0.1,0) [-102.4|429496729.5] "degree"  ASDM
 SG_ zipy_serialized_data_850_RL : 64|32@1- (0.1,0) [-102.4|429496729.5] "degree"  ASDM
 SG_ zipy_serialized_data_851_RL : 96|32@1- (0.1,0) [-102.4|429496729.5] "degree"  ASDM
 SG_ zipy_serialized_data_852_RL : 128|32@1- (0.1,0) [-102.4|429496729.5] "degree"  ASDM
 SG_ zipy_serialized_data_853_RL : 160|32@1- (0.1,0) [-102.4|429496729.5] "degree"  ASDM
 SG_ zipy_serialized_data_854_RL : 192|32@1- (0.1,0) [-102.4|429496729.5] "degree"  ASDM
 SG_ zipy_serialized_data_855_RL : 224|32@1- (0.1,0) [-102.4|429496729.5] "degree"  ASDM
 SG_ zipy_serialized_data_856_RL : 256|32@1- (0.1,0) [-102.4|429496729.5] "degree"  ASDM
 SG_ zipy_serialized_data_857_RL : 288|32@1- (0.1,0) [-102.4|429496729.5] "degree"  ASDM
 SG_ zipy_serialized_data_858_RL : 320|32@1- (0.1,0) [-102.4|429496729.5] "degree"  ASDM
 SG_ zipy_serialized_data_859_RL : 352|32@1- (0.1,0) [-102.4|429496729.5] "degree"  ASDM
 SG_ zipy_serialized_data_860_RL : 384|32@1- (0.1,0) [-102.4|429496729.5] "degree"  ASDM
 SG_ zipy_serialized_data_861_RL : 416|32@1- (0.1,0) [-102.4|429496729.5] "degree"  ASDM
 SG_ zipy_serialized_data_862_RL : 448|32@1- (0.1,0) [-102.4|429496729.5] "degree"  ASDM
 SG_ zipy_serialized_data_863_RL : 480|32@1- (0.1,0) [-102.4|429496729.5] "degree"  ASDM

BO_ 358 MB79_DETECTIONS_54_RL: 64 RSRL
 SG_ zipy_serialized_data_864_RL : 0|32@1- (0.1,0) [-102.4|429496729.5] "degree"  ASDM
 SG_ zipy_serialized_data_865_RL : 32|32@1- (0.1,0) [-102.4|429496729.5] "degree"  ASDM
 SG_ zipy_serialized_data_866_RL : 64|32@1- (0.1,0) [-102.4|429496729.5] "degree"  ASDM
 SG_ zipy_serialized_data_867_RL : 96|32@1- (0.1,0) [-102.4|429496729.5] "degree"  ASDM
 SG_ zipy_serialized_data_868_RL : 128|32@1- (0.1,0) [-102.4|429496729.5] "degree"  ASDM
 SG_ zipy_serialized_data_869_RL : 160|32@1- (0.1,0) [-102.4|429496729.5] "degree"  ASDM
 SG_ zipy_serialized_data_870_RL : 192|32@1- (0.1,0) [-102.4|429496729.5] "degree"  ASDM
 SG_ zipy_serialized_data_871_RL : 224|32@1- (0.1,0) [-102.4|429496729.5] "degree"  ASDM
 SG_ zipy_serialized_data_872_RL : 256|32@1- (0.1,0) [-102.4|429496729.5] "degree"  ASDM
 SG_ zipy_serialized_data_873_RL : 288|32@1- (0.1,0) [-102.4|429496729.5] "degree"  ASDM
 SG_ zipy_serialized_data_874_RL : 320|32@1- (0.1,0) [-102.4|429496729.5] "degree"  ASDM
 SG_ zipy_serialized_data_875_RL : 352|32@1- (0.1,0) [-102.4|429496729.5] "degree"  ASDM
 SG_ zipy_serialized_data_876_RL : 384|32@1- (0.1,0) [-102.4|429496729.5] "degree"  ASDM
 SG_ zipy_serialized_data_877_RL : 416|32@1- (0.1,0) [-102.4|429496729.5] "degree"  ASDM
 SG_ zipy_serialized_data_878_RL : 448|32@1- (0.1,0) [-102.4|429496729.5] "degree"  ASDM
 SG_ zipy_serialized_data_879_RL : 480|32@1- (0.1,0) [-102.4|429496729.5] "degree"  ASDM

BO_ 359 MB79_DETECTIONS_55_RL: 64 RSRL
 SG_ zipy_serialized_data_880_RL : 0|32@1- (0.1,0) [-102.4|429496729.5] "degree"  ASDM
 SG_ zipy_serialized_data_881_RL : 32|32@1- (0.1,0) [-102.4|429496729.5] "degree"  ASDM
 SG_ zipy_serialized_data_882_RL : 64|32@1- (0.1,0) [-102.4|429496729.5] "degree"  ASDM
 SG_ zipy_serialized_data_883_RL : 96|32@1- (0.1,0) [-102.4|429496729.5] "degree"  ASDM
 SG_ zipy_serialized_data_884_RL : 128|32@1- (0.1,0) [-102.4|429496729.5] "degree"  ASDM
 SG_ zipy_serialized_data_885_RL : 160|32@1- (0.1,0) [-102.4|429496729.5] "degree"  ASDM
 SG_ zipy_serialized_data_886_RL : 192|32@1- (0.1,0) [-102.4|429496729.5] "degree"  ASDM
 SG_ zipy_serialized_data_887_RL : 224|32@1- (0.1,0) [-102.4|429496729.5] "degree"  ASDM
 SG_ zipy_serialized_data_888_RL : 256|32@1- (0.1,0) [-102.4|429496729.5] "degree"  ASDM
 SG_ zipy_serialized_data_889_RL : 288|32@1- (0.1,0) [-102.4|429496729.5] "degree"  ASDM
 SG_ zipy_serialized_data_890_RL : 320|32@1- (0.1,0) [-102.4|429496729.5] "degree"  ASDM
 SG_ zipy_serialized_data_891_RL : 352|32@1- (0.1,0) [-102.4|429496729.5] "degree"  ASDM
 SG_ zipy_serialized_data_892_RL : 384|32@1- (0.1,0) [-102.4|429496729.5] "degree"  ASDM
 SG_ zipy_serialized_data_893_RL : 416|32@1- (0.1,0) [-102.4|429496729.5] "degree"  ASDM
 SG_ zipy_serialized_data_894_RL : 448|32@1- (0.1,0) [-102.4|429496729.5] "degree"  ASDM
 SG_ zipy_serialized_data_895_RL : 480|32@1- (0.1,0) [-102.4|429496729.5] "degree"  ASDM

BO_ 769 MB79_VEHICLE_DATA: 12 ASDM
 SG_ VehiclePower_Gear_ASDM : 40|4@1+ (1,0) [0|15] "" Vector__XXX
 SG_ HostVel_ASDM : 7|16@0- (1,0) [-2000|14000] "cm/s"  RSRL,RSRR
 SG_ SteeringAngle_ASDM : 23|16@0- (1,0) [-800|800] "1/10 degree"  RSRL,RSRR
 SG_ Reserved_2_bytes_ASDM : 39|12@0+ (1,0) [0|65535] "N/A"  RSRL,RSRR
 SG_ HostYaw_ASDM : 55|16@0- (1,0) [-2048|2047] "1/1024 rad/sec"  RSRL,RSRR
 SG_ VehicleType_ASDM : 71|8@0+ (1,0) [0|255] "N/A"  RSRL,RSRR
 SG_ Clock_VehicleData_ASDM : 79|4@0+ (1,0) [0|15] "N/A"  RSRL,RSRR
 SG_ Reserved_2bit_ASDM : 75|2@0+ (1,0) [0|3] "N/A"  RSRL,RSRR
 SG_ HostTrailerAttached_ASDM : 73|1@0+ (1,0) [0|1] "N/A"  RSRL,RSRR
 SG_ HostDrivingForward_ASDM : 72|1@0+ (1,0) [0|1] "N/A"  RSRL,RSRR
 SG_ CRC_VehicleData_ASDM : 87|8@0+ (1,0) [0|255] "N/A"  RSRL,RSRR
 SG_ HostGear_ASDM : 95|8@0+ (1,0) [0|15] "N/A"  RSRL,RSRR

BO_ 784 MB79_PROCESSING_PROFIL_RL: 64 RSRL
 SG_ Function_ID_0_RL : 7|8@0+ (1,0) [0|255] ""  ASDM
 SG_ MaxExecTime_0_RL : 15|16@0+ (1,0) [0|65535] ""  ASDM
 SG_ MinExecTime_0_RL : 31|16@0+ (1,0) [0|65535] ""  ASDM
 SG_ AvgExecTime_0_RL : 47|16@0+ (1,0) [0|65535] ""  ASDM
 SG_ LatestStartTimeOffset_0_RL : 63|16@0+ (1,0) [0|65535] ""  ASDM
 SG_ EarliestStartTimeOffset_0_RL : 79|16@0+ (1,0) [0|65535] ""  ASDM
 SG_ AvgStartTimeOffset_0_RL : 95|16@0+ (1,0) [0|65535] ""  ASDM
 SG_ Function_ID_1_RL : 111|8@0+ (1,0) [0|255] ""  ASDM
 SG_ MaxExecTime_1_RL : 119|16@0+ (1,0) [0|65535] ""  ASDM
 SG_ MinExecTime_1_RL : 135|16@0+ (1,0) [0|65535] ""  ASDM
 SG_ AvgExecTime_1_RL : 151|16@0+ (1,0) [0|65535] ""  ASDM
 SG_ LatestStartTimeOffset_1_RL : 167|16@0+ (1,0) [0|65535] ""  ASDM
 SG_ EarliestStartTimeOffset_1_RL : 183|16@0+ (1,0) [0|65535] ""  ASDM
 SG_ AvgStartTimeOffset_1_RL : 199|16@0+ (1,0) [0|65535] ""  ASDM
 SG_ Function_ID_2_RL : 215|8@0+ (1,0) [0|255] ""  ASDM
 SG_ MaxExecTime_2_RL : 223|16@0+ (1,0) [0|65535] ""  ASDM
 SG_ MinExecTime_2_RL : 239|16@0+ (1,0) [0|65535] ""  ASDM
 SG_ AvgExecTime_2_RL : 255|16@0+ (1,0) [0|65535] ""  ASDM
 SG_ LatestStartTimeOffset_2_RL : 271|16@0+ (1,0) [0|65535] ""  ASDM
 SG_ EarliestStartTimeOffset_2_RL : 287|16@0+ (1,0) [0|65535] ""  ASDM
 SG_ AvgStartTimeOffset_2_RL : 303|16@0+ (1,0) [0|65535] ""  ASDM
 SG_ Function_ID_3_RL : 319|8@0+ (1,0) [0|255] ""  ASDM
 SG_ MaxExecTime_3_RL : 327|16@0+ (1,0) [0|65535] ""  ASDM
 SG_ MinExecTime_3_RL : 343|16@0+ (1,0) [0|65535] ""  ASDM
 SG_ AvgExecTime_3_RL : 359|16@0+ (1,0) [0|65535] ""  ASDM
 SG_ LatestStartTimeOffset_3_RL : 375|16@0+ (1,0) [0|65535] ""  ASDM
 SG_ EarliestStartTimeOffset_3_RL : 391|16@0+ (1,0) [0|65535] ""  ASDM
 SG_ AvgStartTimeOffset_3_RL : 407|16@0+ (1,0) [0|65535] ""  ASDM

BO_ 785 MB79_AUTOALIGN_RESULT_RL: 4 RSRL
 SG_ AutoAlignment_ErrorType_RL : 7|4@0+ (1,0) [0|15] "N/A"  ASDM
 SG_ AutoCalib_Status_RL : 3|4@0+ (1,0) [0|15] "N/A"  ASDM

BO_ 786 MB79_VOLT_MONITORING_RL: 24 RSRL
 SG_ voltage_VBAT_mv_RL : 7|16@0+ (1,0) [0|65535] "mv"  ASDM
 SG_ Reserved_2bytes_1_RL : 23|16@0+ (1,0) [0|65535] "mv"  ASDM
 SG_ Reserved_2bytes_2_RL : 39|16@0+ (1,0) [0|65535] "mv"  ASDM
 SG_ Reserved_2bytes_3_RL : 55|16@0+ (1,0) [0|65535] "mv"  ASDM
 SG_ Reserved_2bytes_4_RL : 71|16@0+ (1,0) [0|65535] "mv"  ASDM
 SG_ Reserved_2bytes_5_RL : 87|16@0+ (1,0) [0|65535] "mv"  ASDM
 SG_ Reserved_2bytes_6_RL : 103|16@0+ (1,0) [0|65535] "mv"  ASDM
 SG_ Reserved_2bytes_7_RL : 119|16@0+ (1,0) [0|65535] "mv"  ASDM
 SG_ voltage_SPOS1_mv_RL : 135|16@0+ (1,0) [0|65535] "mv"  ASDM
 SG_ voltage_SPOS2_mv_RL : 151|16@0+ (1,0) [0|65535] "mv"  ASDM
 SG_ Reserved_2bytes_8_RL : 167|16@0+ (1,0) [0|65535] "mv"  ASDM

BO_ 787 MB79_TEMP_MONITORING_RL: 32 RSRL
 SG_ Reserved_2_bytes_RL : 7|16@0- (1,0) [0|65535] "N/A"  ASDM
 SG_ TEMP_RX2_SENS_RL : 23|16@0- (1,0) [-256|255] "Celsius"  ASDM
 SG_ TSENSE2_RL : 39|16@0- (1,0) [-256|255] "Celsius"  ASDM
 SG_ TEMP_RX3_SENS_RL : 55|16@0- (1,0) [-256|255] "Celsius"  ASDM
 SG_ TEMP_RX1_SENS_RL : 71|16@0- (1,0) [-256|255] "Celsius"  ASDM
 SG_ TEMP_RX0_SENS_RL : 87|16@0- (1,0) [-256|255] "Celsius"  ASDM
 SG_ TSENSE1_RL : 103|16@0- (1,0) [-256|255] "Celsius"  ASDM
 SG_ TSENSE0_RL : 119|16@0- (1,0) [-256|255] "Celsius"  ASDM
 SG_ TEMP_TX2_SENS_RL : 135|16@0- (1,0) [-256|255] "Celsius"  ASDM
 SG_ TEMP_TX1_SENS_RL : 151|16@0- (1,0) [-256|255] "Celsius"  ASDM
 SG_ TEMP_TX0_SENS_RL : 167|16@0- (1,0) [-256|255] "Celsius"  ASDM
 SG_ TEMP_DIG1_TX3_SENS_RL : 183|16@0- (1,0) [-256|255] "Celsius"  ASDM
 SG_ MCU_Temp_Status_RL : 199|4@0- (1,0) [0|15] "N/A"  ASDM
 SG_ reserved_RL : 195|4@0- (1,0) [0|15] "N/A"  ASDM
 SG_ TEMP_PM_SENS_RL : 207|16@0- (1,0) [-256|255] "Celsius"  ASDM

BO_ 788 MB79_VERSIONS_RL: 64 RSRL
 SG_ PCANFD_Ver_App_RL : 7|8@0+ (1,0) [0|255] "N/A"  ASDM
 SG_ PCANFD_Ver_Major_RL : 15|8@0+ (1,0) [0|255] "N/A"  ASDM
 SG_ PCANFD_Ver_Minor_RL : 23|8@0+ (1,0) [0|255] "N/A"  ASDM
 SG_ SW_PIPP_Ver_App_RL : 31|16@0+ (1,0) [0|65535] "N/A"  ASDM
 SG_ SW_PIPP_Ver_Major_RL : 47|16@0+ (1,0) [0|65535] "N/A"  ASDM
 SG_ SW_PIPP_Ver_Minor_RL : 63|16@0+ (1,0) [0|65535] "N/A"  ASDM
 SG_ SW_RSP_Ver_App_RL : 79|16@0+ (1,0) [0|65535] "N/A"  ASDM
 SG_ SW_RSP_Ver_Major_RL : 95|16@0+ (1,0) [0|65535] "N/A"  ASDM
 SG_ SW_RSP_Ver_Minor_RL : 111|16@0+ (1,0) [0|65535] "N/A"  ASDM
 SG_ SW_CAFS_Ver_App_RL : 127|16@0+ (1,0) [0|65535] "N/A"  ASDM
 SG_ SW_CAFS_Ver_Major_RL : 143|16@0+ (1,0) [0|65535] "N/A"  ASDM
 SG_ SW_CAFS_Ver_Minor_RL : 159|16@0+ (1,0) [0|65535] "N/A"  ASDM
 SG_ CoresComProtcol_Ver_Major_RL : 175|16@0+ (1,0) [0|65535] "N/A"  ASDM
 SG_ CoresComProtcol_Ver_Minor_RL : 191|16@0+ (1,0) [0|65535] "N/A"  ASDM
 SG_ SW_Bootloader_Ver_App_RL : 207|16@0+ (1,0) [0|65535] "N/A"  ASDM
 SG_ SW_Bootloader_Ver_Major_RL : 223|16@0+ (1,0) [0|65535] "N/A"  ASDM
 SG_ SW_Bootloader_Ver_Minor_RL : 239|16@0+ (1,0) [0|65535] "N/A"  ASDM
 SG_ LCP2_Data_Ver_Major_RL : 255|8@0+ (1,0) [0|255] "N/A"  ASDM
 SG_ LCP2_Data_Ver_Minor_RL : 263|8@0+ (1,0) [0|255] "N/A"  ASDM
 SG_ LCP2_Design_Ver_Major_RL : 271|8@0+ (1,0) [0|255] "N/A"  ASDM
 SG_ LCP2_Design_Ver_Minor_RL : 279|8@0+ (1,0) [0|255] "N/A"  ASDM
 SG_ LCP3_SR_Ver_Major_RL : 287|16@0+ (1,0) [0|65535] "N/A"  ASDM
 SG_ LCP3_SR_Ver_Minor_RL : 303|16@0+ (1,0) [0|65535] "N/A"  ASDM
 SG_ LCP3_SR_Ver_Build_RL : 319|16@0+ (1,0) [0|65535] "N/A"  ASDM
 SG_ LCP3_LR_Ver_Major_RL : 335|16@0+ (1,0) [0|65535] "N/A"  ASDM
 SG_ LCP3_LR_Ver_Minor_RL : 351|16@0+ (1,0) [0|65535] "N/A"  ASDM
 SG_ LCP3_LR_Ver_Build_RL : 367|16@0+ (1,0) [0|65535] "N/A"  ASDM
 SG_ MCU_Cut_Ver_Major_RL : 383|16@0+ (1,0) [0|65535] "N/A"  ASDM
 SG_ MCU_Cut_Ver_Minor_RL : 399|16@0+ (1,0) [0|65535] "N/A"  ASDM
 SG_ RF_chip_Ver_RL : 415|16@0+ (1,0) [0|65535] "N/A"  ASDM
 SG_ Antenna_Ver_Major_RL : 431|8@0+ (1,0) [0|255] "N/A"  ASDM
 SG_ Antenna_Ver_Minor_RL : 439|8@0+ (1,0) [0|255] "N/A"  ASDM

BO_ 1280 MB79_LLHT_CONFIG_ERROR_RL: 64 RSRL
 SG_ Testing_Mode_ID_RL : 7|16@0+ (1,0) [0|65535] "N/A"  ASDM
 SG_ Testing_Mode_SubID_RL : 23|8@0+ (1,0) [0|255] "N/A"  ASDM
 SG_ Testing_Mode_Param_0_RL : 31|8@0+ (1,0) [0|255] "N/A"  ASDM
 SG_ Testing_Mode_Param_1_RL : 39|8@0+ (1,0) [0|255] "N/A"  ASDM
 SG_ Testing_Mode_Param_2_RL : 47|8@0+ (1,0) [0|255] "N/A"  ASDM
 SG_ Testing_Mode_Param_3_RL : 55|8@0+ (1,0) [0|255] "N/A"  ASDM
 SG_ Testing_Mode_Param_4_RL : 63|8@0+ (1,0) [0|255] "N/A"  ASDM
 SG_ Testing_Mode_Param_5_RL : 71|8@0+ (1,0) [0|255] "N/A"  ASDM
 SG_ Testing_Mode_Param_6_RL : 79|8@0+ (1,0) [0|255] "N/A"  ASDM
 SG_ Testing_Mode_Param_7_RL : 87|8@0+ (1,0) [0|255] "N/A"  ASDM
 SG_ Testing_Mode_Param_8_RL : 95|8@0+ (1,0) [0|255] "N/A"  ASDM
 SG_ Testing_Mode_Param_9_RL : 103|8@0+ (1,0) [0|255] "N/A"  ASDM
 SG_ Testing_Mode_Param_10_RL : 111|8@0+ (1,0) [0|255] "N/A"  ASDM
 SG_ Testing_Mode_Param_11_RL : 119|8@0+ (1,0) [0|255] "N/A"  ASDM
 SG_ Testing_Mode_Param_12_RL : 127|8@0+ (1,0) [0|255] "N/A"  ASDM
 SG_ Testing_Mode_Param_13_RL : 135|8@0+ (1,0) [0|255] "N/A"  ASDM
 SG_ Testing_Mode_Param_14_RL : 143|8@0+ (1,0) [0|255] "N/A"  ASDM
 SG_ Testing_Mode_Param_15_RL : 151|8@0+ (1,0) [0|255] "N/A"  ASDM
 SG_ Testing_Mode_Param_16_RL : 159|8@0+ (1,0) [0|255] "N/A"  ASDM
 SG_ Testing_Mode_Param_17_RL : 167|8@0+ (1,0) [0|255] "N/A"  ASDM
 SG_ Testing_Mode_Param_18_RL : 175|8@0+ (1,0) [0|255] "N/A"  ASDM
 SG_ Testing_Mode_Param_19_RL : 183|8@0+ (1,0) [0|255] "N/A"  ASDM
 SG_ Testing_Mode_Param_20_RL : 191|8@0+ (1,0) [0|255] "N/A"  ASDM
 SG_ Testing_Mode_Param_21_RL : 199|8@0+ (1,0) [0|255] "N/A"  ASDM
 SG_ Testing_Mode_Param_22_RL : 207|8@0+ (1,0) [0|255] "N/A"  ASDM
 SG_ Testing_Mode_Param_23_RL : 215|8@0+ (1,0) [0|255] "N/A"  ASDM
 SG_ Testing_Mode_Param_24_RL : 223|8@0+ (1,0) [0|255] "N/A"  ASDM
 SG_ Testing_Mode_Param_25_RL : 231|8@0+ (1,0) [0|255] "N/A"  ASDM
 SG_ Testing_Mode_Param_26_RL : 239|8@0+ (1,0) [0|255] "N/A"  ASDM
 SG_ Testing_Mode_Param_27_RL : 247|8@0+ (1,0) [0|255] "N/A"  ASDM
 SG_ Testing_Mode_Param_28_RL : 255|8@0+ (1,0) [0|255] "N/A"  ASDM
 SG_ Testing_Mode_Param_29_RL : 263|8@0+ (1,0) [0|255] "N/A"  ASDM
 SG_ Testing_Mode_Param_30_RL : 271|8@0+ (1,0) [0|255] "N/A"  ASDM
 SG_ Testing_Mode_Param_31_RL : 279|8@0+ (1,0) [0|255] "N/A"  ASDM
 SG_ Testing_Mode_Param_32_RL : 287|8@0+ (1,0) [0|255] "N/A"  ASDM
 SG_ Testing_Mode_Param_33_RL : 295|8@0+ (1,0) [0|255] "N/A"  ASDM
 SG_ Testing_Mode_Param_34_RL : 303|8@0+ (1,0) [0|255] "N/A"  ASDM
 SG_ Testing_Mode_Param_35_RL : 311|8@0+ (1,0) [0|255] "N/A"  ASDM
 SG_ Testing_Mode_Param_36_RL : 319|8@0+ (1,0) [0|255] "N/A"  ASDM
 SG_ Testing_Mode_Param_37_RL : 327|8@0+ (1,0) [0|255] "N/A"  ASDM
 SG_ Testing_Mode_Param_38_RL : 335|8@0+ (1,0) [0|255] "N/A"  ASDM
 SG_ Testing_Mode_Param_39_RL : 343|8@0+ (1,0) [0|255] "N/A"  ASDM
 SG_ Testing_Mode_Param_40_RL : 351|8@0+ (1,0) [0|255] "N/A"  ASDM
 SG_ Testing_Mode_Param_41_RL : 359|8@0+ (1,0) [0|255] "N/A"  ASDM
 SG_ Testing_Mode_Param_42_RL : 367|8@0+ (1,0) [0|255] "N/A"  ASDM
 SG_ Testing_Mode_Param_43_RL : 375|8@0+ (1,0) [0|255] "N/A"  ASDM
 SG_ Testing_Mode_Param_44_RL : 383|8@0+ (1,0) [0|255] "N/A"  ASDM
 SG_ Testing_Mode_Param_45_RL : 391|8@0+ (1,0) [0|255] "N/A"  ASDM
 SG_ Testing_Mode_Param_46_RL : 399|8@0+ (1,0) [0|255] "N/A"  ASDM
 SG_ Testing_Mode_Param_47_RL : 407|8@0+ (1,0) [0|255] "N/A"  ASDM
 SG_ Testing_Mode_Param_48_RL : 415|8@0+ (1,0) [0|255] "N/A"  ASDM
 SG_ Testing_Mode_Param_49_RL : 423|8@0+ (1,0) [0|255] "N/A"  ASDM
 SG_ Testing_Mode_Param_50_RL : 431|8@0+ (1,0) [0|255] "N/A"  ASDM
 SG_ Testing_Mode_Param_51_RL : 439|8@0+ (1,0) [0|255] "N/A"  ASDM
 SG_ Testing_Mode_Param_52_RL : 447|8@0+ (1,0) [0|255] "N/A"  ASDM
 SG_ Testing_Mode_Param_53_RL : 455|8@0+ (1,0) [0|255] "N/A"  ASDM
 SG_ Testing_Mode_Param_54_RL : 463|8@0+ (1,0) [0|255] "N/A"  ASDM
 SG_ Testing_Mode_Param_55_RL : 471|8@0+ (1,0) [0|255] "N/A"  ASDM
 SG_ Testing_Mode_Param_56_RL : 479|8@0+ (1,0) [0|255] "N/A"  ASDM
 SG_ Testing_Mode_Param_57_RL : 487|8@0+ (1,0) [0|255] "N/A"  ASDM
 SG_ Testing_Mode_Param_58_RL : 495|8@0+ (1,0) [0|255] "N/A"  ASDM
 SG_ Testing_Mode_Param_59_RL : 503|8@0+ (1,0) [0|255] "N/A"  ASDM
 SG_ Testing_Mode_Param_60_RL : 511|8@0+ (1,0) [0|255] "N/A"  ASDM

BO_ 1290 MB79_LLHT_HEADER_RL: 64 RSRL
 SG_ LLHT_Data_Header_Mode_ID_RL : 7|16@0+ (1,0) [0|65535] "N/A"  ASDM
 SG_ LLHT_Data_Header_SubID_RL : 23|8@0+ (1,0) [0|255] "N/A"  ASDM
 SG_ LLHT_Data_Header_MCC_RL : 31|32@0+ (1,0) [0|4294967295] "N/A"  ASDM
 SG_ LLHT_Data_Header_BlkLength_RL : 63|16@0+ (1,0) [0|65535] "N/A"  ASDM
 SG_ LLHT_Data_Header_BlockCnt_RL : 79|8@0+ (1,0) [0|255] "N/A"  ASDM
 SG_ LLHT_Data_Header_NumBlocks_RL : 87|8@0+ (1,0) [0|255] "N/A"  ASDM
 SG_ LLHT_Data_Header_FrmCnt_RL : 95|8@0+ (1,0) [0|255] "N/A"  ASDM
 SG_ LLHT_Data_Header_Reserved_RL : 103|16@0+ (1,0) [0|65535] "N/A"  ASDM
 SG_ LLHT_Data_Header_Config_0_RL : 119|8@0+ (1,0) [0|255] "N/A"  ASDM
 SG_ LLHT_Data_Header_Config_1_RL : 127|8@0+ (1,0) [0|255] "N/A"  ASDM
 SG_ LLHT_Data_Header_Config_2_RL : 135|8@0+ (1,0) [0|255] "N/A"  ASDM
 SG_ LLHT_Data_Header_Config_3_RL : 143|8@0+ (1,0) [0|255] "N/A"  ASDM
 SG_ LLHT_Data_Header_Config_4_RL : 151|8@0+ (1,0) [0|255] "N/A"  ASDM
 SG_ LLHT_Data_Header_Config_5_RL : 159|8@0+ (1,0) [0|255] "N/A"  ASDM
 SG_ LLHT_Data_Header_Config_6_RL : 167|8@0+ (1,0) [0|255] "N/A"  ASDM
 SG_ LLHT_Data_Header_Config_7_RL : 175|8@0+ (1,0) [0|255] "N/A"  ASDM
 SG_ LLHT_Data_Header_Config_8_RL : 183|8@0+ (1,0) [0|255] "N/A"  ASDM
 SG_ LLHT_Data_Header_Config_9_RL : 191|8@0+ (1,0) [0|255] "N/A"  ASDM
 SG_ LLHT_Data_Header_Config_10_RL : 199|8@0+ (1,0) [0|255] "N/A"  ASDM
 SG_ LLHT_Data_Header_Config_11_RL : 207|8@0+ (1,0) [0|255] "N/A"  ASDM
 SG_ LLHT_Data_Header_Config_12_RL : 215|8@0+ (1,0) [0|255] "N/A"  ASDM
 SG_ LLHT_Data_Header_Config_13_RL : 223|8@0+ (1,0) [0|255] "N/A"  ASDM
 SG_ LLHT_Data_Header_Config_14_RL : 231|8@0+ (1,0) [0|255] "N/A"  ASDM
 SG_ LLHT_Data_Header_Config_15_RL : 239|8@0+ (1,0) [0|255] "N/A"  ASDM
 SG_ LLHT_Data_Header_Config_16_RL : 247|8@0+ (1,0) [0|255] "N/A"  ASDM
 SG_ LLHT_Data_Header_Config_17_RL : 255|8@0+ (1,0) [0|255] "N/A"  ASDM
 SG_ LLHT_Data_Header_Config_18_RL : 263|8@0+ (1,0) [0|255] "N/A"  ASDM
 SG_ LLHT_Data_Header_Config_19_RL : 271|8@0+ (1,0) [0|255] "N/A"  ASDM
 SG_ LLHT_Data_Header_Config_20_RL : 279|8@0+ (1,0) [0|255] "N/A"  ASDM
 SG_ LLHT_Data_Header_Config_21_RL : 287|8@0+ (1,0) [0|255] "N/A"  ASDM
 SG_ LLHT_Data_Header_Config_22_RL : 295|8@0+ (1,0) [0|255] "N/A"  ASDM
 SG_ LLHT_Data_Header_Config_23_RL : 303|8@0+ (1,0) [0|255] "N/A"  ASDM
 SG_ LLHT_Data_Header_Config_24_RL : 311|8@0+ (1,0) [0|255] "N/A"  ASDM
 SG_ LLHT_Data_Header_Config_25_RL : 319|8@0+ (1,0) [0|255] "N/A"  ASDM
 SG_ LLHT_Data_Header_Config_26_RL : 327|8@0+ (1,0) [0|255] "N/A"  ASDM
 SG_ LLHT_Data_Header_Config_27_RL : 335|8@0+ (1,0) [0|255] "N/A"  ASDM
 SG_ LLHT_Data_Header_Config_28_RL : 343|8@0+ (1,0) [0|255] "N/A"  ASDM
 SG_ LLHT_Data_Header_Config_29_RL : 351|8@0+ (1,0) [0|255] "N/A"  ASDM
 SG_ LLHT_Data_Header_Config_30_RL : 359|8@0+ (1,0) [0|255] "N/A"  ASDM
 SG_ LLHT_Data_Header_Config_31_RL : 367|8@0+ (1,0) [0|255] "N/A"  ASDM
 SG_ LLHT_Data_Header_Config_32_RL : 375|8@0+ (1,0) [0|255] "N/A"  ASDM
 SG_ LLHT_Data_Header_Config_33_RL : 383|8@0+ (1,0) [0|255] "N/A"  ASDM
 SG_ LLHT_Data_Header_Config_34_RL : 391|8@0+ (1,0) [0|255] "N/A"  ASDM
 SG_ LLHT_Data_Header_Config_35_RL : 399|8@0+ (1,0) [0|255] "N/A"  ASDM
 SG_ LLHT_Data_Header_Config_36_RL : 407|8@0+ (1,0) [0|255] "N/A"  ASDM
 SG_ LLHT_Data_Header_Config_37_RL : 415|8@0+ (1,0) [0|255] "N/A"  ASDM
 SG_ LLHT_Data_Header_Config_38_RL : 423|8@0+ (1,0) [0|255] "N/A"  ASDM
 SG_ LLHT_Data_Header_Config_39_RL : 431|8@0+ (1,0) [0|255] "N/A"  ASDM
 SG_ LLHT_Data_Header_Config_40_RL : 439|8@0+ (1,0) [0|255] "N/A"  ASDM
 SG_ LLHT_Data_Header_Config_41_RL : 447|8@0+ (1,0) [0|255] "N/A"  ASDM
 SG_ LLHT_Data_Header_Config_42_RL : 455|8@0+ (1,0) [0|255] "N/A"  ASDM
 SG_ LLHT_Data_Header_Config_43_RL : 463|8@0+ (1,0) [0|255] "N/A"  ASDM
 SG_ LLHT_Data_Header_Config_44_RL : 471|8@0+ (1,0) [0|255] "N/A"  ASDM
 SG_ LLHT_Data_Header_Config_45_RL : 479|8@0+ (1,0) [0|255] "N/A"  ASDM
 SG_ LLHT_Data_Header_Config_46_RL : 487|8@0+ (1,0) [0|255] "N/A"  ASDM
 SG_ LLHT_Data_Header_Config_47_RL : 495|8@0+ (1,0) [0|255] "N/A"  ASDM
 SG_ LLHT_Data_Header_Config_48_RL : 503|8@0+ (1,0) [0|255] "N/A"  ASDM
 SG_ LLHT_Data_Header_Config_49_RL : 511|8@0+ (1,0) [0|255] "N/A"  ASDM

BO_ 1291 MB79_LLHT_0_RL: 64 RSRL
 SG_ LLHT_Data_0_payload_0_RL : 7|16@0+ (1,0) [0|65535] "N/A"  ASDM
 SG_ LLHT_Data_0_payload_1_RL : 23|16@0+ (1,0) [0|65535] "N/A"  ASDM
 SG_ LLHT_Data_0_payload_2_RL : 39|16@0+ (1,0) [0|65535] "N/A"  ASDM
 SG_ LLHT_Data_0_payload_3_RL : 55|16@0+ (1,0) [0|65535] "N/A"  ASDM
 SG_ LLHT_Data_0_payload_4_RL : 71|16@0+ (1,0) [0|65535] "N/A"  ASDM
 SG_ LLHT_Data_0_payload_5_RL : 87|16@0+ (1,0) [0|65535] "N/A"  ASDM
 SG_ LLHT_Data_0_payload_6_RL : 103|16@0+ (1,0) [0|65535] "N/A"  ASDM
 SG_ LLHT_Data_0_payload_7_RL : 119|16@0+ (1,0) [0|65535] "N/A"  ASDM
 SG_ LLHT_Data_0_payload_8_RL : 135|16@0+ (1,0) [0|65535] "N/A"  ASDM
 SG_ LLHT_Data_0_payload_9_RL : 151|16@0+ (1,0) [0|65535] "N/A"  ASDM
 SG_ LLHT_Data_0_payload_10_RL : 167|16@0+ (1,0) [0|65535] "N/A"  ASDM
 SG_ LLHT_Data_0_payload_11_RL : 183|16@0+ (1,0) [0|65535] "N/A"  ASDM
 SG_ LLHT_Data_0_payload_12_RL : 199|16@0+ (1,0) [0|65535] "N/A"  ASDM
 SG_ LLHT_Data_0_payload_13_RL : 215|16@0+ (1,0) [0|65535] "N/A"  ASDM
 SG_ LLHT_Data_0_payload_14_RL : 231|16@0+ (1,0) [0|65535] "N/A"  ASDM
 SG_ LLHT_Data_0_payload_15_RL : 247|16@0+ (1,0) [0|65535] "N/A"  ASDM
 SG_ LLHT_Data_0_payload_16_RL : 263|16@0+ (1,0) [0|65535] "N/A"  ASDM
 SG_ LLHT_Data_0_payload_17_RL : 279|16@0+ (1,0) [0|65535] "N/A"  ASDM
 SG_ LLHT_Data_0_payload_18_RL : 295|16@0+ (1,0) [0|65535] "N/A"  ASDM
 SG_ LLHT_Data_0_payload_19_RL : 311|16@0+ (1,0) [0|65535] "N/A"  ASDM
 SG_ LLHT_Data_0_payload_20_RL : 327|16@0+ (1,0) [0|65535] "N/A"  ASDM
 SG_ LLHT_Data_0_payload_21_RL : 343|16@0+ (1,0) [0|65535] "N/A"  ASDM
 SG_ LLHT_Data_0_payload_22_RL : 359|16@0+ (1,0) [0|65535] "N/A"  ASDM
 SG_ LLHT_Data_0_payload_23_RL : 375|16@0+ (1,0) [0|65535] "N/A"  ASDM
 SG_ LLHT_Data_0_payload_24_RL : 391|16@0+ (1,0) [0|65535] "N/A"  ASDM
 SG_ LLHT_Data_0_payload_25_RL : 407|16@0+ (1,0) [0|65535] "N/A"  ASDM
 SG_ LLHT_Data_0_payload_26_RL : 423|16@0+ (1,0) [0|65535] "N/A"  ASDM
 SG_ LLHT_Data_0_payload_27_RL : 439|16@0+ (1,0) [0|65535] "N/A"  ASDM
 SG_ LLHT_Data_0_payload_28_RL : 455|16@0+ (1,0) [0|65535] "N/A"  ASDM
 SG_ LLHT_Data_0_payload_29_RL : 471|16@0+ (1,0) [0|65535] "N/A"  ASDM
 SG_ LLHT_Data_0_payload_30_RL : 487|16@0+ (1,0) [0|65535] "N/A"  ASDM
 SG_ LLHT_Data_0_payload_31_RL : 503|16@0+ (1,0) [0|65535] "N/A"  ASDM

BO_ 1292 MB79_LLHT_1_RL: 64 RSRL
 SG_ LLHT_Data_1_payload_32_RL : 7|16@0+ (1,0) [0|65535] "N/A"  ASDM
 SG_ LLHT_Data_1_payload_33_RL : 23|16@0+ (1,0) [0|65535] "N/A"  ASDM
 SG_ LLHT_Data_1_payload_34_RL : 39|16@0+ (1,0) [0|65535] "N/A"  ASDM
 SG_ LLHT_Data_1_payload_35_RL : 55|16@0+ (1,0) [0|65535] "N/A"  ASDM
 SG_ LLHT_Data_1_payload_36_RL : 71|16@0+ (1,0) [0|65535] "N/A"  ASDM
 SG_ LLHT_Data_1_payload_37_RL : 87|16@0+ (1,0) [0|65535] "N/A"  ASDM
 SG_ LLHT_Data_1_payload_38_RL : 103|16@0+ (1,0) [0|65535] "N/A"  ASDM
 SG_ LLHT_Data_1_payload_39_RL : 119|16@0+ (1,0) [0|65535] "N/A"  ASDM
 SG_ LLHT_Data_1_payload_40_RL : 135|16@0+ (1,0) [0|65535] "N/A"  ASDM
 SG_ LLHT_Data_1_payload_41_RL : 151|16@0+ (1,0) [0|65535] "N/A"  ASDM
 SG_ LLHT_Data_1_payload_42_RL : 167|16@0+ (1,0) [0|65535] "N/A"  ASDM
 SG_ LLHT_Data_1_payload_43_RL : 183|16@0+ (1,0) [0|65535] "N/A"  ASDM
 SG_ LLHT_Data_1_payload_44_RL : 199|16@0+ (1,0) [0|65535] "N/A"  ASDM
 SG_ LLHT_Data_1_payload_45_RL : 215|16@0+ (1,0) [0|65535] "N/A"  ASDM
 SG_ LLHT_Data_1_payload_46_RL : 231|16@0+ (1,0) [0|65535] "N/A"  ASDM
 SG_ LLHT_Data_1_payload_47_RL : 247|16@0+ (1,0) [0|65535] "N/A"  ASDM
 SG_ LLHT_Data_1_payload_48_RL : 263|16@0+ (1,0) [0|65535] "N/A"  ASDM
 SG_ LLHT_Data_1_payload_49_RL : 279|16@0+ (1,0) [0|65535] "N/A"  ASDM
 SG_ LLHT_Data_1_payload_50_RL : 295|16@0+ (1,0) [0|65535] "N/A"  ASDM
 SG_ LLHT_Data_1_payload_51_RL : 311|16@0+ (1,0) [0|65535] "N/A"  ASDM
 SG_ LLHT_Data_1_payload_52_RL : 327|16@0+ (1,0) [0|65535] "N/A"  ASDM
 SG_ LLHT_Data_1_payload_53_RL : 343|16@0+ (1,0) [0|65535] "N/A"  ASDM
 SG_ LLHT_Data_1_payload_54_RL : 359|16@0+ (1,0) [0|65535] "N/A"  ASDM
 SG_ LLHT_Data_1_payload_55_RL : 375|16@0+ (1,0) [0|65535] "N/A"  ASDM
 SG_ LLHT_Data_1_payload_56_RL : 391|16@0+ (1,0) [0|65535] "N/A"  ASDM
 SG_ LLHT_Data_1_payload_57_RL : 407|16@0+ (1,0) [0|65535] "N/A"  ASDM
 SG_ LLHT_Data_1_payload_58_RL : 423|16@0+ (1,0) [0|65535] "N/A"  ASDM
 SG_ LLHT_Data_1_payload_59_RL : 439|16@0+ (1,0) [0|65535] "N/A"  ASDM
 SG_ LLHT_Data_1_payload_60_RL : 455|16@0+ (1,0) [0|65535] "N/A"  ASDM
 SG_ LLHT_Data_1_payload_61_RL : 471|16@0+ (1,0) [0|65535] "N/A"  ASDM
 SG_ LLHT_Data_1_payload_62_RL : 487|16@0+ (1,0) [0|65535] "N/A"  ASDM
 SG_ LLHT_Data_1_payload_63_RL : 503|16@0+ (1,0) [0|65535] "N/A"  ASDM

BO_ 1293 MB79_LLHT_2_RL: 64 RSRL
 SG_ LLHT_Data_2_payload_64_RL : 7|16@0+ (1,0) [0|65535] "N/A"  ASDM
 SG_ LLHT_Data_2_payload_65_RL : 23|16@0+ (1,0) [0|65535] "N/A"  ASDM
 SG_ LLHT_Data_2_payload_66_RL : 39|16@0+ (1,0) [0|65535] "N/A"  ASDM
 SG_ LLHT_Data_2_payload_67_RL : 55|16@0+ (1,0) [0|65535] "N/A"  ASDM
 SG_ LLHT_Data_2_payload_68_RL : 71|16@0+ (1,0) [0|65535] "N/A"  ASDM
 SG_ LLHT_Data_2_payload_69_RL : 87|16@0+ (1,0) [0|65535] "N/A"  ASDM
 SG_ LLHT_Data_2_payload_70_RL : 103|16@0+ (1,0) [0|65535] "N/A"  ASDM
 SG_ LLHT_Data_2_payload_71_RL : 119|16@0+ (1,0) [0|65535] "N/A"  ASDM
 SG_ LLHT_Data_2_payload_72_RL : 135|16@0+ (1,0) [0|65535] "N/A"  ASDM
 SG_ LLHT_Data_2_payload_73_RL : 151|16@0+ (1,0) [0|65535] "N/A"  ASDM
 SG_ LLHT_Data_2_payload_74_RL : 167|16@0+ (1,0) [0|65535] "N/A"  ASDM
 SG_ LLHT_Data_2_payload_75_RL : 183|16@0+ (1,0) [0|65535] "N/A"  ASDM
 SG_ LLHT_Data_2_payload_76_RL : 199|16@0+ (1,0) [0|65535] "N/A"  ASDM
 SG_ LLHT_Data_2_payload_77_RL : 215|16@0+ (1,0) [0|65535] "N/A"  ASDM
 SG_ LLHT_Data_2_payload_78_RL : 231|16@0+ (1,0) [0|65535] "N/A"  ASDM
 SG_ LLHT_Data_2_payload_79_RL : 247|16@0+ (1,0) [0|65535] "N/A"  ASDM
 SG_ LLHT_Data_2_payload_80_RL : 263|16@0+ (1,0) [0|65535] "N/A"  ASDM
 SG_ LLHT_Data_2_payload_81_RL : 279|16@0+ (1,0) [0|65535] "N/A"  ASDM
 SG_ LLHT_Data_2_payload_82_RL : 295|16@0+ (1,0) [0|65535] "N/A"  ASDM
 SG_ LLHT_Data_2_payload_83_RL : 311|16@0+ (1,0) [0|65535] "N/A"  ASDM
 SG_ LLHT_Data_2_payload_84_RL : 327|16@0+ (1,0) [0|65535] "N/A"  ASDM
 SG_ LLHT_Data_2_payload_85_RL : 343|16@0+ (1,0) [0|65535] "N/A"  ASDM
 SG_ LLHT_Data_2_payload_86_RL : 359|16@0+ (1,0) [0|65535] "N/A"  ASDM
 SG_ LLHT_Data_2_payload_87_RL : 375|16@0+ (1,0) [0|65535] "N/A"  ASDM
 SG_ LLHT_Data_2_payload_88_RL : 391|16@0+ (1,0) [0|65535] "N/A"  ASDM
 SG_ LLHT_Data_2_payload_89_RL : 407|16@0+ (1,0) [0|65535] "N/A"  ASDM
 SG_ LLHT_Data_2_payload_90_RL : 423|16@0+ (1,0) [0|65535] "N/A"  ASDM
 SG_ LLHT_Data_2_payload_91_RL : 439|16@0+ (1,0) [0|65535] "N/A"  ASDM
 SG_ LLHT_Data_2_payload_92_RL : 455|16@0+ (1,0) [0|65535] "N/A"  ASDM
 SG_ LLHT_Data_2_payload_93_RL : 471|16@0+ (1,0) [0|65535] "N/A"  ASDM
 SG_ LLHT_Data_2_payload_94_RL : 487|16@0+ (1,0) [0|65535] "N/A"  ASDM
 SG_ LLHT_Data_2_payload_95_RL : 503|16@0+ (1,0) [0|65535] "N/A"  ASDM

BO_ 1294 MB79_LLHT_3_RL: 64 RSRL
 SG_ LLHT_Data_3_payload_96_RL : 7|16@0+ (1,0) [0|65535] "N/A"  ASDM
 SG_ LLHT_Data_3_payload_97_RL : 23|16@0+ (1,0) [0|65535] "N/A"  ASDM
 SG_ LLHT_Data_3_payload_98_RL : 39|16@0+ (1,0) [0|65535] "N/A"  ASDM
 SG_ LLHT_Data_3_payload_99_RL : 55|16@0+ (1,0) [0|65535] "N/A"  ASDM
 SG_ LLHT_Data_3_payload_100_RL : 71|16@0+ (1,0) [0|65535] "N/A"  ASDM
 SG_ LLHT_Data_3_payload_101_RL : 87|16@0+ (1,0) [0|65535] "N/A"  ASDM
 SG_ LLHT_Data_3_payload_102_RL : 103|16@0+ (1,0) [0|65535] "N/A"  ASDM
 SG_ LLHT_Data_3_payload_103_RL : 119|16@0+ (1,0) [0|65535] "N/A"  ASDM
 SG_ LLHT_Data_3_payload_104_RL : 135|16@0+ (1,0) [0|65535] "N/A"  ASDM
 SG_ LLHT_Data_3_payload_105_RL : 151|16@0+ (1,0) [0|65535] "N/A"  ASDM
 SG_ LLHT_Data_3_payload_106_RL : 167|16@0+ (1,0) [0|65535] "N/A"  ASDM
 SG_ LLHT_Data_3_payload_107_RL : 183|16@0+ (1,0) [0|65535] "N/A"  ASDM
 SG_ LLHT_Data_3_payload_108_RL : 199|16@0+ (1,0) [0|65535] "N/A"  ASDM
 SG_ LLHT_Data_3_payload_109_RL : 215|16@0+ (1,0) [0|65535] "N/A"  ASDM
 SG_ LLHT_Data_3_payload_110_RL : 231|16@0+ (1,0) [0|65535] "N/A"  ASDM
 SG_ LLHT_Data_3_payload_111_RL : 247|16@0+ (1,0) [0|65535] "N/A"  ASDM
 SG_ LLHT_Data_3_payload_112_RL : 263|16@0+ (1,0) [0|65535] "N/A"  ASDM
 SG_ LLHT_Data_3_payload_113_RL : 279|16@0+ (1,0) [0|65535] "N/A"  ASDM
 SG_ LLHT_Data_3_payload_114_RL : 295|16@0+ (1,0) [0|65535] "N/A"  ASDM
 SG_ LLHT_Data_3_payload_115_RL : 311|16@0+ (1,0) [0|65535] "N/A"  ASDM
 SG_ LLHT_Data_3_payload_116_RL : 327|16@0+ (1,0) [0|65535] "N/A"  ASDM
 SG_ LLHT_Data_3_payload_117_RL : 343|16@0+ (1,0) [0|65535] "N/A"  ASDM
 SG_ LLHT_Data_3_payload_118_RL : 359|16@0+ (1,0) [0|65535] "N/A"  ASDM
 SG_ LLHT_Data_3_payload_119_RL : 375|16@0+ (1,0) [0|65535] "N/A"  ASDM
 SG_ LLHT_Data_3_payload_120_RL : 391|16@0+ (1,0) [0|65535] "N/A"  ASDM
 SG_ LLHT_Data_3_payload_121_RL : 407|16@0+ (1,0) [0|65535] "N/A"  ASDM
 SG_ LLHT_Data_3_payload_122_RL : 423|16@0+ (1,0) [0|65535] "N/A"  ASDM
 SG_ LLHT_Data_3_payload_123_RL : 439|16@0+ (1,0) [0|65535] "N/A"  ASDM
 SG_ LLHT_Data_3_payload_124_RL : 455|16@0+ (1,0) [0|65535] "N/A"  ASDM
 SG_ LLHT_Data_3_payload_125_RL : 471|16@0+ (1,0) [0|65535] "N/A"  ASDM
 SG_ LLHT_Data_3_payload_126_RL : 487|16@0+ (1,0) [0|65535] "N/A"  ASDM
 SG_ LLHT_Data_3_payload_127_RL : 503|16@0+ (1,0) [0|65535] "N/A"  ASDM

BO_ 1295 MB79_LLHT_4_RL: 64 RSRL
 SG_ LLHT_Data_4_payload_128_RL : 7|16@0+ (1,0) [0|65535] "N/A"  ASDM
 SG_ LLHT_Data_4_payload_129_RL : 23|16@0+ (1,0) [0|65535] "N/A"  ASDM
 SG_ LLHT_Data_4_payload_130_RL : 39|16@0+ (1,0) [0|65535] "N/A"  ASDM
 SG_ LLHT_Data_4_payload_131_RL : 55|16@0+ (1,0) [0|65535] "N/A"  ASDM
 SG_ LLHT_Data_4_payload_132_RL : 71|16@0+ (1,0) [0|65535] "N/A"  ASDM
 SG_ LLHT_Data_4_payload_133_RL : 87|16@0+ (1,0) [0|65535] "N/A"  ASDM
 SG_ LLHT_Data_4_payload_134_RL : 103|16@0+ (1,0) [0|65535] "N/A"  ASDM
 SG_ LLHT_Data_4_payload_135_RL : 119|16@0+ (1,0) [0|65535] "N/A"  ASDM
 SG_ LLHT_Data_4_payload_136_RL : 135|16@0+ (1,0) [0|65535] "N/A"  ASDM
 SG_ LLHT_Data_4_payload_137_RL : 151|16@0+ (1,0) [0|65535] "N/A"  ASDM
 SG_ LLHT_Data_4_payload_138_RL : 167|16@0+ (1,0) [0|65535] "N/A"  ASDM
 SG_ LLHT_Data_4_payload_139_RL : 183|16@0+ (1,0) [0|65535] "N/A"  ASDM
 SG_ LLHT_Data_4_payload_140_RL : 199|16@0+ (1,0) [0|65535] "N/A"  ASDM
 SG_ LLHT_Data_4_payload_141_RL : 215|16@0+ (1,0) [0|65535] "N/A"  ASDM
 SG_ LLHT_Data_4_payload_142_RL : 231|16@0+ (1,0) [0|65535] "N/A"  ASDM
 SG_ LLHT_Data_4_payload_143_RL : 247|16@0+ (1,0) [0|65535] "N/A"  ASDM
 SG_ LLHT_Data_4_payload_144_RL : 263|16@0+ (1,0) [0|65535] "N/A"  ASDM
 SG_ LLHT_Data_4_payload_145_RL : 279|16@0+ (1,0) [0|65535] "N/A"  ASDM
 SG_ LLHT_Data_4_payload_146_RL : 295|16@0+ (1,0) [0|65535] "N/A"  ASDM
 SG_ LLHT_Data_4_payload_147_RL : 311|16@0+ (1,0) [0|65535] "N/A"  ASDM
 SG_ LLHT_Data_4_payload_148_RL : 327|16@0+ (1,0) [0|65535] "N/A"  ASDM
 SG_ LLHT_Data_4_payload_149_RL : 343|16@0+ (1,0) [0|65535] "N/A"  ASDM
 SG_ LLHT_Data_4_payload_150_RL : 359|16@0+ (1,0) [0|65535] "N/A"  ASDM
 SG_ LLHT_Data_4_payload_151_RL : 375|16@0+ (1,0) [0|65535] "N/A"  ASDM
 SG_ LLHT_Data_4_payload_152_RL : 391|16@0+ (1,0) [0|65535] "N/A"  ASDM
 SG_ LLHT_Data_4_payload_153_RL : 407|16@0+ (1,0) [0|65535] "N/A"  ASDM
 SG_ LLHT_Data_4_payload_154_RL : 423|16@0+ (1,0) [0|65535] "N/A"  ASDM
 SG_ LLHT_Data_4_payload_155_RL : 439|16@0+ (1,0) [0|65535] "N/A"  ASDM
 SG_ LLHT_Data_4_payload_156_RL : 455|16@0+ (1,0) [0|65535] "N/A"  ASDM
 SG_ LLHT_Data_4_payload_157_RL : 471|16@0+ (1,0) [0|65535] "N/A"  ASDM
 SG_ LLHT_Data_4_payload_158_RL : 487|16@0+ (1,0) [0|65535] "N/A"  ASDM
 SG_ LLHT_Data_4_payload_159_RL : 503|16@0+ (1,0) [0|65535] "N/A"  ASDM

BO_ 1296 MB79_LLHT_5_RL: 64 RSRL
 SG_ LLHT_Data_5_payload_160_RL : 7|16@0+ (1,0) [0|65535] "N/A"  ASDM
 SG_ LLHT_Data_5_payload_161_RL : 23|16@0+ (1,0) [0|65535] "N/A"  ASDM
 SG_ LLHT_Data_5_payload_162_RL : 39|16@0+ (1,0) [0|65535] "N/A"  ASDM
 SG_ LLHT_Data_5_payload_163_RL : 55|16@0+ (1,0) [0|65535] "N/A"  ASDM
 SG_ LLHT_Data_5_payload_164_RL : 71|16@0+ (1,0) [0|65535] "N/A"  ASDM
 SG_ LLHT_Data_5_payload_165_RL : 87|16@0+ (1,0) [0|65535] "N/A"  ASDM
 SG_ LLHT_Data_5_payload_166_RL : 103|16@0+ (1,0) [0|65535] "N/A"  ASDM
 SG_ LLHT_Data_5_payload_167_RL : 119|16@0+ (1,0) [0|65535] "N/A"  ASDM
 SG_ LLHT_Data_5_payload_168_RL : 135|16@0+ (1,0) [0|65535] "N/A"  ASDM
 SG_ LLHT_Data_5_payload_169_RL : 151|16@0+ (1,0) [0|65535] "N/A"  ASDM
 SG_ LLHT_Data_5_payload_170_RL : 167|16@0+ (1,0) [0|65535] "N/A"  ASDM
 SG_ LLHT_Data_5_payload_171_RL : 183|16@0+ (1,0) [0|65535] "N/A"  ASDM
 SG_ LLHT_Data_5_payload_172_RL : 199|16@0+ (1,0) [0|65535] "N/A"  ASDM
 SG_ LLHT_Data_5_payload_173_RL : 215|16@0+ (1,0) [0|65535] "N/A"  ASDM
 SG_ LLHT_Data_5_payload_174_RL : 231|16@0+ (1,0) [0|65535] "N/A"  ASDM
 SG_ LLHT_Data_5_payload_175_RL : 247|16@0+ (1,0) [0|65535] "N/A"  ASDM
 SG_ LLHT_Data_5_payload_176_RL : 263|16@0+ (1,0) [0|65535] "N/A"  ASDM
 SG_ LLHT_Data_5_payload_177_RL : 279|16@0+ (1,0) [0|65535] "N/A"  ASDM
 SG_ LLHT_Data_5_payload_178_RL : 295|16@0+ (1,0) [0|65535] "N/A"  ASDM
 SG_ LLHT_Data_5_payload_179_RL : 311|16@0+ (1,0) [0|65535] "N/A"  ASDM
 SG_ LLHT_Data_5_payload_180_RL : 327|16@0+ (1,0) [0|65535] "N/A"  ASDM
 SG_ LLHT_Data_5_payload_181_RL : 343|16@0+ (1,0) [0|65535] "N/A"  ASDM
 SG_ LLHT_Data_5_payload_182_RL : 359|16@0+ (1,0) [0|65535] "N/A"  ASDM
 SG_ LLHT_Data_5_payload_183_RL : 375|16@0+ (1,0) [0|65535] "N/A"  ASDM
 SG_ LLHT_Data_5_payload_184_RL : 391|16@0+ (1,0) [0|65535] "N/A"  ASDM
 SG_ LLHT_Data_5_payload_185_RL : 407|16@0+ (1,0) [0|65535] "N/A"  ASDM
 SG_ LLHT_Data_5_payload_186_RL : 423|16@0+ (1,0) [0|65535] "N/A"  ASDM
 SG_ LLHT_Data_5_payload_187_RL : 439|16@0+ (1,0) [0|65535] "N/A"  ASDM
 SG_ LLHT_Data_5_payload_188_RL : 455|16@0+ (1,0) [0|65535] "N/A"  ASDM
 SG_ LLHT_Data_5_payload_189_RL : 471|16@0+ (1,0) [0|65535] "N/A"  ASDM
 SG_ LLHT_Data_5_payload_190_RL : 487|16@0+ (1,0) [0|65535] "N/A"  ASDM
 SG_ LLHT_Data_5_payload_191_RL : 503|16@0+ (1,0) [0|65535] "N/A"  ASDM

BO_ 1297 MB79_LLHT_6_RL: 64 RSRL
 SG_ LLHT_Data_6_payload_192_RL : 7|16@0+ (1,0) [0|65535] "N/A"  ASDM
 SG_ LLHT_Data_6_payload_193_RL : 23|16@0+ (1,0) [0|65535] "N/A"  ASDM
 SG_ LLHT_Data_6_payload_194_RL : 39|16@0+ (1,0) [0|65535] "N/A"  ASDM
 SG_ LLHT_Data_6_payload_195_RL : 55|16@0+ (1,0) [0|65535] "N/A"  ASDM
 SG_ LLHT_Data_6_payload_196_RL : 71|16@0+ (1,0) [0|65535] "N/A"  ASDM
 SG_ LLHT_Data_6_payload_197_RL : 87|16@0+ (1,0) [0|65535] "N/A"  ASDM
 SG_ LLHT_Data_6_payload_198_RL : 103|16@0+ (1,0) [0|65535] "N/A"  ASDM
 SG_ LLHT_Data_6_payload_199_RL : 119|16@0+ (1,0) [0|65535] "N/A"  ASDM
 SG_ LLHT_Data_6_payload_200_RL : 135|16@0+ (1,0) [0|65535] "N/A"  ASDM
 SG_ LLHT_Data_6_payload_201_RL : 151|16@0+ (1,0) [0|65535] "N/A"  ASDM
 SG_ LLHT_Data_6_payload_202_RL : 167|16@0+ (1,0) [0|65535] "N/A"  ASDM
 SG_ LLHT_Data_6_payload_203_RL : 183|16@0+ (1,0) [0|65535] "N/A"  ASDM
 SG_ LLHT_Data_6_payload_204_RL : 199|16@0+ (1,0) [0|65535] "N/A"  ASDM
 SG_ LLHT_Data_6_payload_205_RL : 215|16@0+ (1,0) [0|65535] "N/A"  ASDM
 SG_ LLHT_Data_6_payload_206_RL : 231|16@0+ (1,0) [0|65535] "N/A"  ASDM
 SG_ LLHT_Data_6_payload_207_RL : 247|16@0+ (1,0) [0|65535] "N/A"  ASDM
 SG_ LLHT_Data_6_payload_208_RL : 263|16@0+ (1,0) [0|65535] "N/A"  ASDM
 SG_ LLHT_Data_6_payload_209_RL : 279|16@0+ (1,0) [0|65535] "N/A"  ASDM
 SG_ LLHT_Data_6_payload_210_RL : 295|16@0+ (1,0) [0|65535] "N/A"  ASDM
 SG_ LLHT_Data_6_payload_211_RL : 311|16@0+ (1,0) [0|65535] "N/A"  ASDM
 SG_ LLHT_Data_6_payload_212_RL : 327|16@0+ (1,0) [0|65535] "N/A"  ASDM
 SG_ LLHT_Data_6_payload_213_RL : 343|16@0+ (1,0) [0|65535] "N/A"  ASDM
 SG_ LLHT_Data_6_payload_214_RL : 359|16@0+ (1,0) [0|65535] "N/A"  ASDM
 SG_ LLHT_Data_6_payload_215_RL : 375|16@0+ (1,0) [0|65535] "N/A"  ASDM
 SG_ LLHT_Data_6_payload_216_RL : 391|16@0+ (1,0) [0|65535] "N/A"  ASDM
 SG_ LLHT_Data_6_payload_217_RL : 407|16@0+ (1,0) [0|65535] "N/A"  ASDM
 SG_ LLHT_Data_6_payload_218_RL : 423|16@0+ (1,0) [0|65535] "N/A"  ASDM
 SG_ LLHT_Data_6_payload_219_RL : 439|16@0+ (1,0) [0|65535] "N/A"  ASDM
 SG_ LLHT_Data_6_payload_220_RL : 455|16@0+ (1,0) [0|65535] "N/A"  ASDM
 SG_ LLHT_Data_6_payload_221_RL : 471|16@0+ (1,0) [0|65535] "N/A"  ASDM
 SG_ LLHT_Data_6_payload_222_RL : 487|16@0+ (1,0) [0|65535] "N/A"  ASDM
 SG_ LLHT_Data_6_payload_223_RL : 503|16@0+ (1,0) [0|65535] "N/A"  ASDM

BO_ 1298 MB79_LLHT_7_RL: 64 RSRL
 SG_ LLHT_Data_7_payload_224_RL : 7|16@0+ (1,0) [0|65535] "N/A"  ASDM
 SG_ LLHT_Data_7_payload_225_RL : 23|16@0+ (1,0) [0|65535] "N/A"  ASDM
 SG_ LLHT_Data_7_payload_226_RL : 39|16@0+ (1,0) [0|65535] "N/A"  ASDM
 SG_ LLHT_Data_7_payload_227_RL : 55|16@0+ (1,0) [0|65535] "N/A"  ASDM
 SG_ LLHT_Data_7_payload_228_RL : 71|16@0+ (1,0) [0|65535] "N/A"  ASDM
 SG_ LLHT_Data_7_payload_229_RL : 87|16@0+ (1,0) [0|65535] "N/A"  ASDM
 SG_ LLHT_Data_7_payload_230_RL : 103|16@0+ (1,0) [0|65535] "N/A"  ASDM
 SG_ LLHT_Data_7_payload_231_RL : 119|16@0+ (1,0) [0|65535] "N/A"  ASDM
 SG_ LLHT_Data_7_payload_232_RL : 135|16@0+ (1,0) [0|65535] "N/A"  ASDM
 SG_ LLHT_Data_7_payload_233_RL : 151|16@0+ (1,0) [0|65535] "N/A"  ASDM
 SG_ LLHT_Data_7_payload_234_RL : 167|16@0+ (1,0) [0|65535] "N/A"  ASDM
 SG_ LLHT_Data_7_payload_235_RL : 183|16@0+ (1,0) [0|65535] "N/A"  ASDM
 SG_ LLHT_Data_7_payload_236_RL : 199|16@0+ (1,0) [0|65535] "N/A"  ASDM
 SG_ LLHT_Data_7_payload_237_RL : 215|16@0+ (1,0) [0|65535] "N/A"  ASDM
 SG_ LLHT_Data_7_payload_238_RL : 231|16@0+ (1,0) [0|65535] "N/A"  ASDM
 SG_ LLHT_Data_7_payload_239_RL : 247|16@0+ (1,0) [0|65535] "N/A"  ASDM
 SG_ LLHT_Data_7_payload_240_RL : 263|16@0+ (1,0) [0|65535] "N/A"  ASDM
 SG_ LLHT_Data_7_payload_241_RL : 279|16@0+ (1,0) [0|65535] "N/A"  ASDM
 SG_ LLHT_Data_7_payload_242_RL : 295|16@0+ (1,0) [0|65535] "N/A"  ASDM
 SG_ LLHT_Data_7_payload_243_RL : 311|16@0+ (1,0) [0|65535] "N/A"  ASDM
 SG_ LLHT_Data_7_payload_244_RL : 327|16@0+ (1,0) [0|65535] "N/A"  ASDM
 SG_ LLHT_Data_7_payload_245_RL : 343|16@0+ (1,0) [0|65535] "N/A"  ASDM
 SG_ LLHT_Data_7_payload_246_RL : 359|16@0+ (1,0) [0|65535] "N/A"  ASDM
 SG_ LLHT_Data_7_payload_247_RL : 375|16@0+ (1,0) [0|65535] "N/A"  ASDM
 SG_ LLHT_Data_7_payload_248_RL : 391|16@0+ (1,0) [0|65535] "N/A"  ASDM
 SG_ LLHT_Data_7_payload_249_RL : 407|16@0+ (1,0) [0|65535] "N/A"  ASDM
 SG_ LLHT_Data_7_payload_250_RL : 423|16@0+ (1,0) [0|65535] "N/A"  ASDM
 SG_ LLHT_Data_7_payload_251_RL : 439|16@0+ (1,0) [0|65535] "N/A"  ASDM
 SG_ LLHT_Data_7_payload_252_RL : 455|16@0+ (1,0) [0|65535] "N/A"  ASDM
 SG_ LLHT_Data_7_payload_253_RL : 471|16@0+ (1,0) [0|65535] "N/A"  ASDM
 SG_ LLHT_Data_7_payload_254_RL : 487|16@0+ (1,0) [0|65535] "N/A"  ASDM
 SG_ LLHT_Data_7_payload_255_RL : 503|16@0+ (1,0) [0|65535] "N/A"  ASDM

BO_ 1299 MB79_LLHT_8_RL: 64 RSRL
 SG_ LLHT_Data_8_payload_256_RL : 7|16@0+ (1,0) [0|65535] "N/A"  ASDM
 SG_ LLHT_Data_8_payload_257_RL : 23|16@0+ (1,0) [0|65535] "N/A"  ASDM
 SG_ LLHT_Data_8_payload_258_RL : 39|16@0+ (1,0) [0|65535] "N/A"  ASDM
 SG_ LLHT_Data_8_payload_259_RL : 55|16@0+ (1,0) [0|65535] "N/A"  ASDM
 SG_ LLHT_Data_8_payload_260_RL : 71|16@0+ (1,0) [0|65535] "N/A"  ASDM
 SG_ LLHT_Data_8_payload_261_RL : 87|16@0+ (1,0) [0|65535] "N/A"  ASDM
 SG_ LLHT_Data_8_payload_262_RL : 103|16@0+ (1,0) [0|65535] "N/A"  ASDM
 SG_ LLHT_Data_8_payload_263_RL : 119|16@0+ (1,0) [0|65535] "N/A"  ASDM
 SG_ LLHT_Data_8_payload_264_RL : 135|16@0+ (1,0) [0|65535] "N/A"  ASDM
 SG_ LLHT_Data_8_payload_265_RL : 151|16@0+ (1,0) [0|65535] "N/A"  ASDM
 SG_ LLHT_Data_8_payload_266_RL : 167|16@0+ (1,0) [0|65535] "N/A"  ASDM
 SG_ LLHT_Data_8_payload_267_RL : 183|16@0+ (1,0) [0|65535] "N/A"  ASDM
 SG_ LLHT_Data_8_payload_268_RL : 199|16@0+ (1,0) [0|65535] "N/A"  ASDM
 SG_ LLHT_Data_8_payload_269_RL : 215|16@0+ (1,0) [0|65535] "N/A"  ASDM
 SG_ LLHT_Data_8_payload_270_RL : 231|16@0+ (1,0) [0|65535] "N/A"  ASDM
 SG_ LLHT_Data_8_payload_271_RL : 247|16@0+ (1,0) [0|65535] "N/A"  ASDM
 SG_ LLHT_Data_8_payload_272_RL : 263|16@0+ (1,0) [0|65535] "N/A"  ASDM
 SG_ LLHT_Data_8_payload_273_RL : 279|16@0+ (1,0) [0|65535] "N/A"  ASDM
 SG_ LLHT_Data_8_payload_274_RL : 295|16@0+ (1,0) [0|65535] "N/A"  ASDM
 SG_ LLHT_Data_8_payload_275_RL : 311|16@0+ (1,0) [0|65535] "N/A"  ASDM
 SG_ LLHT_Data_8_payload_276_RL : 327|16@0+ (1,0) [0|65535] "N/A"  ASDM
 SG_ LLHT_Data_8_payload_277_RL : 343|16@0+ (1,0) [0|65535] "N/A"  ASDM
 SG_ LLHT_Data_8_payload_278_RL : 359|16@0+ (1,0) [0|65535] "N/A"  ASDM
 SG_ LLHT_Data_8_payload_279_RL : 375|16@0+ (1,0) [0|65535] "N/A"  ASDM
 SG_ LLHT_Data_8_payload_280_RL : 391|16@0+ (1,0) [0|65535] "N/A"  ASDM
 SG_ LLHT_Data_8_payload_281_RL : 407|16@0+ (1,0) [0|65535] "N/A"  ASDM
 SG_ LLHT_Data_8_payload_282_RL : 423|16@0+ (1,0) [0|65535] "N/A"  ASDM
 SG_ LLHT_Data_8_payload_283_RL : 439|16@0+ (1,0) [0|65535] "N/A"  ASDM
 SG_ LLHT_Data_8_payload_284_RL : 455|16@0+ (1,0) [0|65535] "N/A"  ASDM
 SG_ LLHT_Data_8_payload_285_RL : 471|16@0+ (1,0) [0|65535] "N/A"  ASDM
 SG_ LLHT_Data_8_payload_286_RL : 487|16@0+ (1,0) [0|65535] "N/A"  ASDM
 SG_ LLHT_Data_8_payload_287_RL : 503|16@0+ (1,0) [0|65535] "N/A"  ASDM

BO_ 1300 MB79_LLHT_9_RL: 64 RSRL
 SG_ LLHT_Data_9_payload_288_RL : 7|16@0+ (1,0) [0|65535] "N/A"  ASDM
 SG_ LLHT_Data_9_payload_289_RL : 23|16@0+ (1,0) [0|65535] "N/A"  ASDM
 SG_ LLHT_Data_9_payload_290_RL : 39|16@0+ (1,0) [0|65535] "N/A"  ASDM
 SG_ LLHT_Data_9_payload_291_RL : 55|16@0+ (1,0) [0|65535] "N/A"  ASDM
 SG_ LLHT_Data_9_payload_292_RL : 71|16@0+ (1,0) [0|65535] "N/A"  ASDM
 SG_ LLHT_Data_9_payload_293_RL : 87|16@0+ (1,0) [0|65535] "N/A"  ASDM
 SG_ LLHT_Data_9_payload_294_RL : 103|16@0+ (1,0) [0|65535] "N/A"  ASDM
 SG_ LLHT_Data_9_payload_295_RL : 119|16@0+ (1,0) [0|65535] "N/A"  ASDM
 SG_ LLHT_Data_9_payload_296_RL : 135|16@0+ (1,0) [0|65535] "N/A"  ASDM
 SG_ LLHT_Data_9_payload_297_RL : 151|16@0+ (1,0) [0|65535] "N/A"  ASDM
 SG_ LLHT_Data_9_payload_298_RL : 167|16@0+ (1,0) [0|65535] "N/A"  ASDM
 SG_ LLHT_Data_9_payload_299_RL : 183|16@0+ (1,0) [0|65535] "N/A"  ASDM
 SG_ LLHT_Data_9_payload_300_RL : 199|16@0+ (1,0) [0|65535] "N/A"  ASDM
 SG_ LLHT_Data_9_payload_301_RL : 215|16@0+ (1,0) [0|65535] "N/A"  ASDM
 SG_ LLHT_Data_9_payload_302_RL : 231|16@0+ (1,0) [0|65535] "N/A"  ASDM
 SG_ LLHT_Data_9_payload_303_RL : 247|16@0+ (1,0) [0|65535] "N/A"  ASDM
 SG_ LLHT_Data_9_payload_304_RL : 263|16@0+ (1,0) [0|65535] "N/A"  ASDM
 SG_ LLHT_Data_9_payload_305_RL : 279|16@0+ (1,0) [0|65535] "N/A"  ASDM
 SG_ LLHT_Data_9_payload_306_RL : 295|16@0+ (1,0) [0|65535] "N/A"  ASDM
 SG_ LLHT_Data_9_payload_307_RL : 311|16@0+ (1,0) [0|65535] "N/A"  ASDM
 SG_ LLHT_Data_9_payload_308_RL : 327|16@0+ (1,0) [0|65535] "N/A"  ASDM
 SG_ LLHT_Data_9_payload_309_RL : 343|16@0+ (1,0) [0|65535] "N/A"  ASDM
 SG_ LLHT_Data_9_payload_310_RL : 359|16@0+ (1,0) [0|65535] "N/A"  ASDM
 SG_ LLHT_Data_9_payload_311_RL : 375|16@0+ (1,0) [0|65535] "N/A"  ASDM
 SG_ LLHT_Data_9_payload_312_RL : 391|16@0+ (1,0) [0|65535] "N/A"  ASDM
 SG_ LLHT_Data_9_payload_313_RL : 407|16@0+ (1,0) [0|65535] "N/A"  ASDM
 SG_ LLHT_Data_9_payload_314_RL : 423|16@0+ (1,0) [0|65535] "N/A"  ASDM
 SG_ LLHT_Data_9_payload_315_RL : 439|16@0+ (1,0) [0|65535] "N/A"  ASDM
 SG_ LLHT_Data_9_payload_316_RL : 455|16@0+ (1,0) [0|65535] "N/A"  ASDM
 SG_ LLHT_Data_9_payload_317_RL : 471|16@0+ (1,0) [0|65535] "N/A"  ASDM
 SG_ LLHT_Data_9_payload_318_RL : 487|16@0+ (1,0) [0|65535] "N/A"  ASDM
 SG_ LLHT_Data_9_payload_319_RL : 503|16@0+ (1,0) [0|65535] "N/A"  ASDM

BO_ 1301 MB79_LLHT_10_RL: 64 RSRL
 SG_ LLHT_Data_10_payload_320_RL : 7|16@0+ (1,0) [0|65535] "N/A"  ASDM
 SG_ LLHT_Data_10_payload_321_RL : 23|16@0+ (1,0) [0|65535] "N/A"  ASDM
 SG_ LLHT_Data_10_payload_322_RL : 39|16@0+ (1,0) [0|65535] "N/A"  ASDM
 SG_ LLHT_Data_10_payload_323_RL : 55|16@0+ (1,0) [0|65535] "N/A"  ASDM
 SG_ LLHT_Data_10_payload_324_RL : 71|16@0+ (1,0) [0|65535] "N/A"  ASDM
 SG_ LLHT_Data_10_payload_325_RL : 87|16@0+ (1,0) [0|65535] "N/A"  ASDM
 SG_ LLHT_Data_10_payload_326_RL : 103|16@0+ (1,0) [0|65535] "N/A"  ASDM
 SG_ LLHT_Data_10_payload_327_RL : 119|16@0+ (1,0) [0|65535] "N/A"  ASDM
 SG_ LLHT_Data_10_payload_328_RL : 135|16@0+ (1,0) [0|65535] "N/A"  ASDM
 SG_ LLHT_Data_10_payload_329_RL : 151|16@0+ (1,0) [0|65535] "N/A"  ASDM
 SG_ LLHT_Data_10_payload_330_RL : 167|16@0+ (1,0) [0|65535] "N/A"  ASDM
 SG_ LLHT_Data_10_payload_331_RL : 183|16@0+ (1,0) [0|65535] "N/A"  ASDM
 SG_ LLHT_Data_10_payload_332_RL : 199|16@0+ (1,0) [0|65535] "N/A"  ASDM
 SG_ LLHT_Data_10_payload_333_RL : 215|16@0+ (1,0) [0|65535] "N/A"  ASDM
 SG_ LLHT_Data_10_payload_334_RL : 231|16@0+ (1,0) [0|65535] "N/A"  ASDM
 SG_ LLHT_Data_10_payload_335_RL : 247|16@0+ (1,0) [0|65535] "N/A"  ASDM
 SG_ LLHT_Data_10_payload_336_RL : 263|16@0+ (1,0) [0|65535] "N/A"  ASDM
 SG_ LLHT_Data_10_payload_337_RL : 279|16@0+ (1,0) [0|65535] "N/A"  ASDM
 SG_ LLHT_Data_10_payload_338_RL : 295|16@0+ (1,0) [0|65535] "N/A"  ASDM
 SG_ LLHT_Data_10_payload_339_RL : 311|16@0+ (1,0) [0|65535] "N/A"  ASDM
 SG_ LLHT_Data_10_payload_340_RL : 327|16@0+ (1,0) [0|65535] "N/A"  ASDM
 SG_ LLHT_Data_10_payload_341_RL : 343|16@0+ (1,0) [0|65535] "N/A"  ASDM
 SG_ LLHT_Data_10_payload_342_RL : 359|16@0+ (1,0) [0|65535] "N/A"  ASDM
 SG_ LLHT_Data_10_payload_343_RL : 375|16@0+ (1,0) [0|65535] "N/A"  ASDM
 SG_ LLHT_Data_10_payload_344_RL : 391|16@0+ (1,0) [0|65535] "N/A"  ASDM
 SG_ LLHT_Data_10_payload_345_RL : 407|16@0+ (1,0) [0|65535] "N/A"  ASDM
 SG_ LLHT_Data_10_payload_346_RL : 423|16@0+ (1,0) [0|65535] "N/A"  ASDM
 SG_ LLHT_Data_10_payload_347_RL : 439|16@0+ (1,0) [0|65535] "N/A"  ASDM
 SG_ LLHT_Data_10_payload_348_RL : 455|16@0+ (1,0) [0|65535] "N/A"  ASDM
 SG_ LLHT_Data_10_payload_349_RL : 471|16@0+ (1,0) [0|65535] "N/A"  ASDM
 SG_ LLHT_Data_10_payload_350_RL : 487|16@0+ (1,0) [0|65535] "N/A"  ASDM
 SG_ LLHT_Data_10_payload_351_RL : 503|16@0+ (1,0) [0|65535] "N/A"  ASDM

BO_ 1302 MB79_LLHT_11_RL: 64 RSRL
 SG_ LLHT_Data_11_payload_352_RL : 7|16@0+ (1,0) [0|65535] "N/A"  ASDM
 SG_ LLHT_Data_11_payload_353_RL : 23|16@0+ (1,0) [0|65535] "N/A"  ASDM
 SG_ LLHT_Data_11_payload_354_RL : 39|16@0+ (1,0) [0|65535] "N/A"  ASDM
 SG_ LLHT_Data_11_payload_355_RL : 55|16@0+ (1,0) [0|65535] "N/A"  ASDM
 SG_ LLHT_Data_11_payload_356_RL : 71|16@0+ (1,0) [0|65535] "N/A"  ASDM
 SG_ LLHT_Data_11_payload_357_RL : 87|16@0+ (1,0) [0|65535] "N/A"  ASDM
 SG_ LLHT_Data_11_payload_358_RL : 103|16@0+ (1,0) [0|65535] "N/A"  ASDM
 SG_ LLHT_Data_11_payload_359_RL : 119|16@0+ (1,0) [0|65535] "N/A"  ASDM
 SG_ LLHT_Data_11_payload_360_RL : 135|16@0+ (1,0) [0|65535] "N/A"  ASDM
 SG_ LLHT_Data_11_payload_361_RL : 151|16@0+ (1,0) [0|65535] "N/A"  ASDM
 SG_ LLHT_Data_11_payload_362_RL : 167|16@0+ (1,0) [0|65535] "N/A"  ASDM
 SG_ LLHT_Data_11_payload_363_RL : 183|16@0+ (1,0) [0|65535] "N/A"  ASDM
 SG_ LLHT_Data_11_payload_364_RL : 199|16@0+ (1,0) [0|65535] "N/A"  ASDM
 SG_ LLHT_Data_11_payload_365_RL : 215|16@0+ (1,0) [0|65535] "N/A"  ASDM
 SG_ LLHT_Data_11_payload_366_RL : 231|16@0+ (1,0) [0|65535] "N/A"  ASDM
 SG_ LLHT_Data_11_payload_367_RL : 247|16@0+ (1,0) [0|65535] "N/A"  ASDM
 SG_ LLHT_Data_11_payload_368_RL : 263|16@0+ (1,0) [0|65535] "N/A"  ASDM
 SG_ LLHT_Data_11_payload_369_RL : 279|16@0+ (1,0) [0|65535] "N/A"  ASDM
 SG_ LLHT_Data_11_payload_370_RL : 295|16@0+ (1,0) [0|65535] "N/A"  ASDM
 SG_ LLHT_Data_11_payload_371_RL : 311|16@0+ (1,0) [0|65535] "N/A"  ASDM
 SG_ LLHT_Data_11_payload_372_RL : 327|16@0+ (1,0) [0|65535] "N/A"  ASDM
 SG_ LLHT_Data_11_payload_373_RL : 343|16@0+ (1,0) [0|65535] "N/A"  ASDM
 SG_ LLHT_Data_11_payload_374_RL : 359|16@0+ (1,0) [0|65535] "N/A"  ASDM
 SG_ LLHT_Data_11_payload_375_RL : 375|16@0+ (1,0) [0|65535] "N/A"  ASDM
 SG_ LLHT_Data_11_payload_376_RL : 391|16@0+ (1,0) [0|65535] "N/A"  ASDM
 SG_ LLHT_Data_11_payload_377_RL : 407|16@0+ (1,0) [0|65535] "N/A"  ASDM
 SG_ LLHT_Data_11_payload_378_RL : 423|16@0+ (1,0) [0|65535] "N/A"  ASDM
 SG_ LLHT_Data_11_payload_379_RL : 439|16@0+ (1,0) [0|65535] "N/A"  ASDM
 SG_ LLHT_Data_11_payload_380_RL : 455|16@0+ (1,0) [0|65535] "N/A"  ASDM
 SG_ LLHT_Data_11_payload_381_RL : 471|16@0+ (1,0) [0|65535] "N/A"  ASDM
 SG_ LLHT_Data_11_payload_382_RL : 487|16@0+ (1,0) [0|65535] "N/A"  ASDM
 SG_ LLHT_Data_11_payload_383_RL : 503|16@0+ (1,0) [0|65535] "N/A"  ASDM

BO_ 1303 MB79_LLHT_12_RL: 64 RSRL
 SG_ LLHT_Data_12_payload_384_RL : 7|16@0+ (1,0) [0|65535] "N/A"  ASDM
 SG_ LLHT_Data_12_payload_385_RL : 23|16@0+ (1,0) [0|65535] "N/A"  ASDM
 SG_ LLHT_Data_12_payload_386_RL : 39|16@0+ (1,0) [0|65535] "N/A"  ASDM
 SG_ LLHT_Data_12_payload_387_RL : 55|16@0+ (1,0) [0|65535] "N/A"  ASDM
 SG_ LLHT_Data_12_payload_388_RL : 71|16@0+ (1,0) [0|65535] "N/A"  ASDM
 SG_ LLHT_Data_12_payload_389_RL : 87|16@0+ (1,0) [0|65535] "N/A"  ASDM
 SG_ LLHT_Data_12_payload_390_RL : 103|16@0+ (1,0) [0|65535] "N/A"  ASDM
 SG_ LLHT_Data_12_payload_391_RL : 119|16@0+ (1,0) [0|65535] "N/A"  ASDM
 SG_ LLHT_Data_12_payload_392_RL : 135|16@0+ (1,0) [0|65535] "N/A"  ASDM
 SG_ LLHT_Data_12_payload_393_RL : 151|16@0+ (1,0) [0|65535] "N/A"  ASDM
 SG_ LLHT_Data_12_payload_394_RL : 167|16@0+ (1,0) [0|65535] "N/A"  ASDM
 SG_ LLHT_Data_12_payload_395_RL : 183|16@0+ (1,0) [0|65535] "N/A"  ASDM
 SG_ LLHT_Data_12_payload_396_RL : 199|16@0+ (1,0) [0|65535] "N/A"  ASDM
 SG_ LLHT_Data_12_payload_397_RL : 215|16@0+ (1,0) [0|65535] "N/A"  ASDM
 SG_ LLHT_Data_12_payload_398_RL : 231|16@0+ (1,0) [0|65535] "N/A"  ASDM
 SG_ LLHT_Data_12_payload_399_RL : 247|16@0+ (1,0) [0|65535] "N/A"  ASDM
 SG_ LLHT_Data_12_payload_400_RL : 263|16@0+ (1,0) [0|65535] "N/A"  ASDM
 SG_ LLHT_Data_12_payload_401_RL : 279|16@0+ (1,0) [0|65535] "N/A"  ASDM
 SG_ LLHT_Data_12_payload_402_RL : 295|16@0+ (1,0) [0|65535] "N/A"  ASDM
 SG_ LLHT_Data_12_payload_403_RL : 311|16@0+ (1,0) [0|65535] "N/A"  ASDM
 SG_ LLHT_Data_12_payload_404_RL : 327|16@0+ (1,0) [0|65535] "N/A"  ASDM
 SG_ LLHT_Data_12_payload_405_RL : 343|16@0+ (1,0) [0|65535] "N/A"  ASDM
 SG_ LLHT_Data_12_payload_406_RL : 359|16@0+ (1,0) [0|65535] "N/A"  ASDM
 SG_ LLHT_Data_12_payload_407_RL : 375|16@0+ (1,0) [0|65535] "N/A"  ASDM
 SG_ LLHT_Data_12_payload_408_RL : 391|16@0+ (1,0) [0|65535] "N/A"  ASDM
 SG_ LLHT_Data_12_payload_409_RL : 407|16@0+ (1,0) [0|65535] "N/A"  ASDM
 SG_ LLHT_Data_12_payload_410_RL : 423|16@0+ (1,0) [0|65535] "N/A"  ASDM
 SG_ LLHT_Data_12_payload_411_RL : 439|16@0+ (1,0) [0|65535] "N/A"  ASDM
 SG_ LLHT_Data_12_payload_412_RL : 455|16@0+ (1,0) [0|65535] "N/A"  ASDM
 SG_ LLHT_Data_12_payload_413_RL : 471|16@0+ (1,0) [0|65535] "N/A"  ASDM
 SG_ LLHT_Data_12_payload_414_RL : 487|16@0+ (1,0) [0|65535] "N/A"  ASDM
 SG_ LLHT_Data_12_payload_415_RL : 503|16@0+ (1,0) [0|65535] "N/A"  ASDM

BO_ 1304 MB79_LLHT_13_RL: 64 RSRL
 SG_ LLHT_Data_13_payload_416_RL : 7|16@0+ (1,0) [0|65535] "N/A"  ASDM
 SG_ LLHT_Data_13_payload_417_RL : 23|16@0+ (1,0) [0|65535] "N/A"  ASDM
 SG_ LLHT_Data_13_payload_418_RL : 39|16@0+ (1,0) [0|65535] "N/A"  ASDM
 SG_ LLHT_Data_13_payload_419_RL : 55|16@0+ (1,0) [0|65535] "N/A"  ASDM
 SG_ LLHT_Data_13_payload_420_RL : 71|16@0+ (1,0) [0|65535] "N/A"  ASDM
 SG_ LLHT_Data_13_payload_421_RL : 87|16@0+ (1,0) [0|65535] "N/A"  ASDM
 SG_ LLHT_Data_13_payload_422_RL : 103|16@0+ (1,0) [0|65535] "N/A"  ASDM
 SG_ LLHT_Data_13_payload_423_RL : 119|16@0+ (1,0) [0|65535] "N/A"  ASDM
 SG_ LLHT_Data_13_payload_424_RL : 135|16@0+ (1,0) [0|65535] "N/A"  ASDM
 SG_ LLHT_Data_13_payload_425_RL : 151|16@0+ (1,0) [0|65535] "N/A"  ASDM
 SG_ LLHT_Data_13_payload_426_RL : 167|16@0+ (1,0) [0|65535] "N/A"  ASDM
 SG_ LLHT_Data_13_payload_427_RL : 183|16@0+ (1,0) [0|65535] "N/A"  ASDM
 SG_ LLHT_Data_13_payload_428_RL : 199|16@0+ (1,0) [0|65535] "N/A"  ASDM
 SG_ LLHT_Data_13_payload_429_RL : 215|16@0+ (1,0) [0|65535] "N/A"  ASDM
 SG_ LLHT_Data_13_payload_430_RL : 231|16@0+ (1,0) [0|65535] "N/A"  ASDM
 SG_ LLHT_Data_13_payload_431_RL : 247|16@0+ (1,0) [0|65535] "N/A"  ASDM
 SG_ LLHT_Data_13_payload_432_RL : 263|16@0+ (1,0) [0|65535] "N/A"  ASDM
 SG_ LLHT_Data_13_payload_433_RL : 279|16@0+ (1,0) [0|65535] "N/A"  ASDM
 SG_ LLHT_Data_13_payload_434_RL : 295|16@0+ (1,0) [0|65535] "N/A"  ASDM
 SG_ LLHT_Data_13_payload_435_RL : 311|16@0+ (1,0) [0|65535] "N/A"  ASDM
 SG_ LLHT_Data_13_payload_436_RL : 327|16@0+ (1,0) [0|65535] "N/A"  ASDM
 SG_ LLHT_Data_13_payload_437_RL : 343|16@0+ (1,0) [0|65535] "N/A"  ASDM
 SG_ LLHT_Data_13_payload_438_RL : 359|16@0+ (1,0) [0|65535] "N/A"  ASDM
 SG_ LLHT_Data_13_payload_439_RL : 375|16@0+ (1,0) [0|65535] "N/A"  ASDM
 SG_ LLHT_Data_13_payload_440_RL : 391|16@0+ (1,0) [0|65535] "N/A"  ASDM
 SG_ LLHT_Data_13_payload_441_RL : 407|16@0+ (1,0) [0|65535] "N/A"  ASDM
 SG_ LLHT_Data_13_payload_442_RL : 423|16@0+ (1,0) [0|65535] "N/A"  ASDM
 SG_ LLHT_Data_13_payload_443_RL : 439|16@0+ (1,0) [0|65535] "N/A"  ASDM
 SG_ LLHT_Data_13_payload_444_RL : 455|16@0+ (1,0) [0|65535] "N/A"  ASDM
 SG_ LLHT_Data_13_payload_445_RL : 471|16@0+ (1,0) [0|65535] "N/A"  ASDM
 SG_ LLHT_Data_13_payload_446_RL : 487|16@0+ (1,0) [0|65535] "N/A"  ASDM
 SG_ LLHT_Data_13_payload_447_RL : 503|16@0+ (1,0) [0|65535] "N/A"  ASDM

BO_ 1305 MB79_LLHT_14_RL: 64 RSRL
 SG_ LLHT_Data_14_payload_448_RL : 7|16@0+ (1,0) [0|65535] "N/A"  ASDM
 SG_ LLHT_Data_14_payload_449_RL : 23|16@0+ (1,0) [0|65535] "N/A"  ASDM
 SG_ LLHT_Data_14_payload_450_RL : 39|16@0+ (1,0) [0|65535] "N/A"  ASDM
 SG_ LLHT_Data_14_payload_451_RL : 55|16@0+ (1,0) [0|65535] "N/A"  ASDM
 SG_ LLHT_Data_14_payload_452_RL : 71|16@0+ (1,0) [0|65535] "N/A"  ASDM
 SG_ LLHT_Data_14_payload_453_RL : 87|16@0+ (1,0) [0|65535] "N/A"  ASDM
 SG_ LLHT_Data_14_payload_454_RL : 103|16@0+ (1,0) [0|65535] "N/A"  ASDM
 SG_ LLHT_Data_14_payload_455_RL : 119|16@0+ (1,0) [0|65535] "N/A"  ASDM
 SG_ LLHT_Data_14_payload_456_RL : 135|16@0+ (1,0) [0|65535] "N/A"  ASDM
 SG_ LLHT_Data_14_payload_457_RL : 151|16@0+ (1,0) [0|65535] "N/A"  ASDM
 SG_ LLHT_Data_14_payload_458_RL : 167|16@0+ (1,0) [0|65535] "N/A"  ASDM
 SG_ LLHT_Data_14_payload_459_RL : 183|16@0+ (1,0) [0|65535] "N/A"  ASDM
 SG_ LLHT_Data_14_payload_460_RL : 199|16@0+ (1,0) [0|65535] "N/A"  ASDM
 SG_ LLHT_Data_14_payload_461_RL : 215|16@0+ (1,0) [0|65535] "N/A"  ASDM
 SG_ LLHT_Data_14_payload_462_RL : 231|16@0+ (1,0) [0|65535] "N/A"  ASDM
 SG_ LLHT_Data_14_payload_463_RL : 247|16@0+ (1,0) [0|65535] "N/A"  ASDM
 SG_ LLHT_Data_14_payload_464_RL : 263|16@0+ (1,0) [0|65535] "N/A"  ASDM
 SG_ LLHT_Data_14_payload_465_RL : 279|16@0+ (1,0) [0|65535] "N/A"  ASDM
 SG_ LLHT_Data_14_payload_466_RL : 295|16@0+ (1,0) [0|65535] "N/A"  ASDM
 SG_ LLHT_Data_14_payload_467_RL : 311|16@0+ (1,0) [0|65535] "N/A"  ASDM
 SG_ LLHT_Data_14_payload_468_RL : 327|16@0+ (1,0) [0|65535] "N/A"  ASDM
 SG_ LLHT_Data_14_payload_469_RL : 343|16@0+ (1,0) [0|65535] "N/A"  ASDM
 SG_ LLHT_Data_14_payload_470_RL : 359|16@0+ (1,0) [0|65535] "N/A"  ASDM
 SG_ LLHT_Data_14_payload_471_RL : 375|16@0+ (1,0) [0|65535] "N/A"  ASDM
 SG_ LLHT_Data_14_payload_472_RL : 391|16@0+ (1,0) [0|65535] "N/A"  ASDM
 SG_ LLHT_Data_14_payload_473_RL : 407|16@0+ (1,0) [0|65535] "N/A"  ASDM
 SG_ LLHT_Data_14_payload_474_RL : 423|16@0+ (1,0) [0|65535] "N/A"  ASDM
 SG_ LLHT_Data_14_payload_475_RL : 439|16@0+ (1,0) [0|65535] "N/A"  ASDM
 SG_ LLHT_Data_14_payload_476_RL : 455|16@0+ (1,0) [0|65535] "N/A"  ASDM
 SG_ LLHT_Data_14_payload_477_RL : 471|16@0+ (1,0) [0|65535] "N/A"  ASDM
 SG_ LLHT_Data_14_payload_478_RL : 487|16@0+ (1,0) [0|65535] "N/A"  ASDM
 SG_ LLHT_Data_14_payload_479_RL : 503|16@0+ (1,0) [0|65535] "N/A"  ASDM

BO_ 1306 MB79_LLHT_15_RL: 64 RSRL
 SG_ LLHT_Data_15_payload_480_RL : 7|16@0+ (1,0) [0|65535] "N/A"  ASDM
 SG_ LLHT_Data_15_payload_481_RL : 23|16@0+ (1,0) [0|65535] "N/A"  ASDM
 SG_ LLHT_Data_15_payload_482_RL : 39|16@0+ (1,0) [0|65535] "N/A"  ASDM
 SG_ LLHT_Data_15_payload_483_RL : 55|16@0+ (1,0) [0|65535] "N/A"  ASDM
 SG_ LLHT_Data_15_payload_484_RL : 71|16@0+ (1,0) [0|65535] "N/A"  ASDM
 SG_ LLHT_Data_15_payload_485_RL : 87|16@0+ (1,0) [0|65535] "N/A"  ASDM
 SG_ LLHT_Data_15_payload_486_RL : 103|16@0+ (1,0) [0|65535] "N/A"  ASDM
 SG_ LLHT_Data_15_payload_487_RL : 119|16@0+ (1,0) [0|65535] "N/A"  ASDM
 SG_ LLHT_Data_15_payload_488_RL : 135|16@0+ (1,0) [0|65535] "N/A"  ASDM
 SG_ LLHT_Data_15_payload_489_RL : 151|16@0+ (1,0) [0|65535] "N/A"  ASDM
 SG_ LLHT_Data_15_payload_490_RL : 167|16@0+ (1,0) [0|65535] "N/A"  ASDM
 SG_ LLHT_Data_15_payload_491_RL : 183|16@0+ (1,0) [0|65535] "N/A"  ASDM
 SG_ LLHT_Data_15_payload_492_RL : 199|16@0+ (1,0) [0|65535] "N/A"  ASDM
 SG_ LLHT_Data_15_payload_493_RL : 215|16@0+ (1,0) [0|65535] "N/A"  ASDM
 SG_ LLHT_Data_15_payload_494_RL : 231|16@0+ (1,0) [0|65535] "N/A"  ASDM
 SG_ LLHT_Data_15_payload_495_RL : 247|16@0+ (1,0) [0|65535] "N/A"  ASDM
 SG_ LLHT_Data_15_payload_496_RL : 263|16@0+ (1,0) [0|65535] "N/A"  ASDM
 SG_ LLHT_Data_15_payload_497_RL : 279|16@0+ (1,0) [0|65535] "N/A"  ASDM
 SG_ LLHT_Data_15_payload_498_RL : 295|16@0+ (1,0) [0|65535] "N/A"  ASDM
 SG_ LLHT_Data_15_payload_499_RL : 311|16@0+ (1,0) [0|65535] "N/A"  ASDM
 SG_ LLHT_Data_15_payload_500_RL : 327|16@0+ (1,0) [0|65535] "N/A"  ASDM
 SG_ LLHT_Data_15_payload_501_RL : 343|16@0+ (1,0) [0|65535] "N/A"  ASDM
 SG_ LLHT_Data_15_payload_502_RL : 359|16@0+ (1,0) [0|65535] "N/A"  ASDM
 SG_ LLHT_Data_15_payload_503_RL : 375|16@0+ (1,0) [0|65535] "N/A"  ASDM
 SG_ LLHT_Data_15_payload_504_RL : 391|16@0+ (1,0) [0|65535] "N/A"  ASDM
 SG_ LLHT_Data_15_payload_505_RL : 407|16@0+ (1,0) [0|65535] "N/A"  ASDM
 SG_ LLHT_Data_15_payload_506_RL : 423|16@0+ (1,0) [0|65535] "N/A"  ASDM
 SG_ LLHT_Data_15_payload_507_RL : 439|16@0+ (1,0) [0|65535] "N/A"  ASDM
 SG_ LLHT_Data_15_payload_508_RL : 455|16@0+ (1,0) [0|65535] "N/A"  ASDM
 SG_ LLHT_Data_15_payload_509_RL : 471|16@0+ (1,0) [0|65535] "N/A"  ASDM
 SG_ LLHT_Data_15_payload_510_RL : 487|16@0+ (1,0) [0|65535] "N/A"  ASDM
 SG_ LLHT_Data_15_payload_511_RL : 503|16@0+ (1,0) [0|65535] "N/A"  ASDM

BO_ 1307 MB79_ASC_CORRECTION_0_RL: 64 RSRL
 SG_ ASC_Azimuth_Correction_0_RL : 0|16@1- (0.01,0) [-20|20] "degree"  ASDM
 SG_ ASC_Azimuth_Correction_1_RL : 16|16@1- (0.01,0) [-20|20] "degree"  ASDM
 SG_ ASC_Azimuth_Correction_2_RL : 32|16@1- (0.01,0) [-20|20] "degree"  ASDM
 SG_ ASC_Azimuth_Correction_3_RL : 48|16@1- (0.01,0) [-20|20] "degree"  ASDM
 SG_ ASC_Azimuth_Correction_4_RL : 64|16@1- (0.01,0) [-20|20] "degree"  ASDM
 SG_ ASC_Azimuth_Correction_5_RL : 80|16@1- (0.01,0) [-20|20] "degree"  ASDM
 SG_ ASC_Azimuth_Correction_6_RL : 96|16@1- (0.01,0) [-20|20] "degree"  ASDM
 SG_ ASC_Azimuth_Correction_7_RL : 112|16@1- (0.01,0) [-20|20] "degree"  ASDM
 SG_ ASC_Azimuth_Correction_8_RL : 128|16@1- (0.01,0) [-20|20] "degree"  ASDM
 SG_ ASC_Azimuth_Correction_9_RL : 144|16@1- (0.01,0) [-20|20] "degree"  ASDM
 SG_ ASC_Azimuth_Correction_10_RL : 160|16@1- (0.01,0) [-20|20] "degree"  ASDM
 SG_ ASC_Azimuth_Correction_11_RL : 176|16@1- (0.01,0) [-20|20] "degree"  ASDM
 SG_ ASC_Azimuth_Correction_12_RL : 192|16@1- (0.01,0) [-20|20] "degree"  ASDM
 SG_ ASC_Azimuth_Correction_13_RL : 208|16@1- (0.01,0) [-20|20] "degree"  ASDM
 SG_ ASC_Azimuth_Correction_14_RL : 224|16@1- (0.01,0) [-20|20] "degree"  ASDM
 SG_ ASC_Azimuth_Correction_15_RL : 240|16@1- (0.01,0) [-20|20] "degree"  ASDM
 SG_ ASC_Azimuth_Correction_16_RL : 256|16@1- (0.01,0) [-20|20] "degree"  ASDM
 SG_ ASC_Azimuth_Correction_17_RL : 272|16@1- (0.01,0) [-20|20] "degree"  ASDM
 SG_ ASC_Azimuth_Correction_18_RL : 288|16@1- (0.01,0) [-20|20] "degree"  ASDM
 SG_ ASC_Azimuth_Correction_19_RL : 304|16@1- (0.01,0) [-20|20] "degree"  ASDM
 SG_ ASC_Azimuth_Correction_20_RL : 320|16@1- (0.01,0) [-20|20] "degree"  ASDM
 SG_ ASC_Azimuth_Correction_21_RL : 336|16@1- (0.01,0) [-20|20] "degree"  ASDM
 SG_ ASC_Azimuth_Correction_22_RL : 352|16@1- (0.01,0) [-20|20] "degree"  ASDM
 SG_ ASC_Azimuth_Correction_23_RL : 368|16@1- (0.01,0) [-20|20] "degree"  ASDM
 SG_ ASC_Azimuth_Correction_24_RL : 384|16@1- (0.01,0) [-20|20] "degree"  ASDM
 SG_ ASC_Azimuth_Correction_25_RL : 400|16@1- (0.01,0) [-20|20] "degree"  ASDM
 SG_ ASC_Azimuth_Correction_26_RL : 416|16@1- (0.01,0) [-20|20] "degree"  ASDM
 SG_ ASC_Azimuth_Correction_27_RL : 432|16@1- (0.01,0) [-20|20] "degree"  ASDM
 SG_ ASC_Azimuth_Correction_28_RL : 448|16@1- (0.01,0) [-20|20] "degree"  ASDM
 SG_ ASC_Azimuth_Correction_29_RL : 464|16@1- (0.01,0) [-20|20] "degree"  ASDM
 SG_ ASC_Azimuth_Correction_30_RL : 480|16@1- (0.01,0) [-20|20] "degree"  ASDM
 SG_ ASC_Azimuth_Correction_31_RL : 496|16@1- (0.01,0) [-20|20] "degree"  ASDM

BO_ 1308 MB79_ASC_CORRECTION_1_RL: 64 RSRL
 SG_ ASC_Azimuth_Correction_32_RL : 0|16@1- (0.01,0) [-20|20] "degree"  ASDM
 SG_ ASC_Azimuth_Correction_33_RL : 16|16@1- (0.01,0) [-20|20] "degree"  ASDM
 SG_ ASC_Azimuth_Correction_34_RL : 32|16@1- (0.01,0) [-20|20] "degree"  ASDM
 SG_ ASC_Azimuth_Correction_35_RL : 48|16@1- (0.01,0) [-20|20] "degree"  ASDM
 SG_ ASC_Azimuth_Correction_36_RL : 64|16@1- (0.01,0) [-20|20] "degree"  ASDM
 SG_ ASC_Azimuth_Correction_37_RL : 80|16@1- (0.01,0) [-20|20] "degree"  ASDM
 SG_ ASC_Azimuth_Correction_38_RL : 96|16@1- (0.01,0) [-20|20] "degree"  ASDM
 SG_ ASC_Azimuth_Correction_39_RL : 112|16@1- (0.01,0) [-20|20] "degree"  ASDM
 SG_ ASC_Azimuth_Correction_40_RL : 128|16@1- (0.01,0) [-20|20] "degree"  ASDM
 SG_ ASC_Azimuth_Correction_41_RL : 144|16@1- (0.01,0) [-20|20] "degree"  ASDM
 SG_ ASC_Azimuth_Correction_42_RL : 160|16@1- (0.01,0) [-20|20] "degree"  ASDM
 SG_ ASC_Azimuth_Correction_43_RL : 176|16@1- (0.01,0) [-20|20] "degree"  ASDM
 SG_ ASC_Azimuth_Correction_44_RL : 192|16@1- (0.01,0) [-20|20] "degree"  ASDM
 SG_ ASC_Azimuth_Correction_45_RL : 208|16@1- (0.01,0) [-20|20] "degree"  ASDM
 SG_ ASC_Azimuth_Correction_46_RL : 224|16@1- (0.01,0) [-20|20] "degree"  ASDM
 SG_ ASC_Azimuth_Correction_47_RL : 240|16@1- (0.01,0) [-20|20] "degree"  ASDM
 SG_ ASC_Azimuth_Correction_48_RL : 256|16@1- (0.01,0) [-20|20] "degree"  ASDM
 SG_ ASC_Azimuth_Correction_49_RL : 272|16@1- (0.01,0) [-20|20] "degree"  ASDM
 SG_ ASC_Azimuth_Correction_50_RL : 288|16@1- (0.01,0) [-20|20] "degree"  ASDM
 SG_ ASC_Azimuth_Correction_51_RL : 304|16@1- (0.01,0) [-20|20] "degree"  ASDM
 SG_ ASC_Azimuth_Correction_52_RL : 320|16@1- (0.01,0) [-20|20] "degree"  ASDM
 SG_ ASC_Azimuth_Correction_53_RL : 336|16@1- (0.01,0) [-20|20] "degree"  ASDM
 SG_ ASC_Azimuth_Correction_54_RL : 352|16@1- (0.01,0) [-20|20] "degree"  ASDM
 SG_ ASC_Azimuth_Correction_55_RL : 368|16@1- (0.01,0) [-20|20] "degree"  ASDM
 SG_ ASC_Azimuth_Correction_56_RL : 384|16@1- (0.01,0) [-20|20] "degree"  ASDM
 SG_ ASC_Azimuth_Correction_57_RL : 400|16@1- (0.01,0) [-20|20] "degree"  ASDM
 SG_ ASC_Azimuth_Correction_58_RL : 416|16@1- (0.01,0) [-20|20] "degree"  ASDM
 SG_ ASC_Azimuth_Correction_59_RL : 432|16@1- (0.01,0) [-20|20] "degree"  ASDM
 SG_ ASC_Azimuth_Correction_60_RL : 448|16@1- (0.01,0) [-20|20] "degree"  ASDM
 SG_ ASC_Azimuth_Correction_61_RL : 464|16@1- (0.01,0) [-20|20] "degree"  ASDM
 SG_ ASC_Azimuth_Correction_62_RL : 480|16@1- (0.01,0) [-20|20] "degree"  ASDM
 SG_ ASC_Azimuth_Correction_63_RL : 496|16@1- (0.01,0) [-20|20] "degree"  ASDM

BO_ 1309 MB79_ASC_CORRECTION_2_RL: 64 RSRL
 SG_ ASC_Azimuth_Correction_64_RL : 0|16@1- (0.01,0) [-20|20] "degree"  ASDM
 SG_ ASC_Azimuth_Correction_65_RL : 16|16@1- (0.01,0) [-20|20] "degree"  ASDM
 SG_ ASC_Azimuth_Correction_66_RL : 32|16@1- (0.01,0) [-20|20] "degree"  ASDM
 SG_ ASC_Azimuth_Correction_67_RL : 48|16@1- (0.01,0) [-20|20] "degree"  ASDM
 SG_ ASC_Azimuth_Correction_68_RL : 64|16@1- (0.01,0) [-20|20] "degree"  ASDM
 SG_ ASC_Azimuth_Correction_69_RL : 80|16@1- (0.01,0) [-20|20] "degree"  ASDM
 SG_ ASC_Azimuth_Correction_70_RL : 96|16@1- (0.01,0) [-20|20] "degree"  ASDM
 SG_ ASC_Azimuth_Correction_71_RL : 112|16@1- (0.01,0) [-20|20] "degree"  ASDM
 SG_ ASC_Azimuth_Correction_72_RL : 128|16@1- (0.01,0) [-20|20] "degree"  ASDM
 SG_ ASC_Azimuth_Correction_73_RL : 144|16@1- (0.01,0) [-20|20] "degree"  ASDM
 SG_ ASC_Azimuth_Correction_74_RL : 160|16@1- (0.01,0) [-20|20] "degree"  ASDM
 SG_ ASC_Azimuth_Correction_75_RL : 176|16@1- (0.01,0) [-20|20] "degree"  ASDM
 SG_ ASC_Azimuth_Correction_76_RL : 192|16@1- (0.01,0) [-20|20] "degree"  ASDM
 SG_ ASC_Azimuth_Correction_77_RL : 208|16@1- (0.01,0) [-20|20] "degree"  ASDM
 SG_ ASC_Azimuth_Correction_78_RL : 224|16@1- (0.01,0) [-20|20] "degree"  ASDM
 SG_ ASC_Azimuth_Correction_79_RL : 240|16@1- (0.01,0) [-20|20] "degree"  ASDM
 SG_ ASC_Azimuth_Correction_80_RL : 256|16@1- (0.01,0) [-20|20] "degree"  ASDM
 SG_ ASC_Azimuth_Correction_81_RL : 272|16@1- (0.01,0) [-20|20] "degree"  ASDM
 SG_ ASC_Azimuth_Correction_82_RL : 288|16@1- (0.01,0) [-20|20] "degree"  ASDM
 SG_ ASC_Azimuth_Correction_83_RL : 304|16@1- (0.01,0) [-20|20] "degree"  ASDM
 SG_ ASC_Azimuth_Correction_84_RL : 320|16@1- (0.01,0) [-20|20] "degree"  ASDM
 SG_ ASC_Azimuth_Correction_85_RL : 336|16@1- (0.01,0) [-20|20] "degree"  ASDM
 SG_ ASC_Azimuth_Correction_86_RL : 352|16@1- (0.01,0) [-20|20] "degree"  ASDM
 SG_ ASC_Azimuth_Correction_87_RL : 368|16@1- (0.01,0) [-20|20] "degree"  ASDM
 SG_ ASC_Azimuth_Correction_88_RL : 384|16@1- (0.01,0) [-20|20] "degree"  ASDM
 SG_ ASC_Azimuth_Correction_89_RL : 400|16@1- (0.01,0) [-20|20] "degree"  ASDM
 SG_ ASC_Azimuth_Correction_90_RL : 416|16@1- (0.01,0) [-20|20] "degree"  ASDM
 SG_ ASC_Azimuth_Correction_91_RL : 432|16@1- (0.01,0) [-20|20] "degree"  ASDM
 SG_ ASC_Azimuth_Correction_92_RL : 448|16@1- (0.01,0) [-20|20] "degree"  ASDM
 SG_ ASC_Azimuth_Correction_93_RL : 464|16@1- (0.01,0) [-20|20] "degree"  ASDM
 SG_ ASC_Azimuth_Correction_94_RL : 480|16@1- (0.01,0) [-20|20] "degree"  ASDM
 SG_ ASC_Azimuth_Correction_95_RL : 496|16@1- (0.01,0) [-20|20] "degree"  ASDM

// Node Comments
CM_ BU_ RSRL "Rear Side Radar Left (RSRL)";
CM_ BU_ RSRR "Rear Side Radar Right (RSRR)";

CM_ BO_ 1281 "ECU_WAKE_UP";
CM_ BO_ 416 "used for network Management";
CM_ SG_ 416 NM_Sig_0_ASDM "Network Manegement Signal";
CM_ SG_ 416 NM_Sig_1_ASDM "Network Manegement Signal";
CM_ SG_ 416 NM_Sig_2_ASDM "Network Manegement Signal";
CM_ SG_ 416 NM_Sig_3_ASDM "Network Manegement Signal";
CM_ SG_ 416 NM_Sig_4_ASDM "Network Manegement Signal";
CM_ SG_ 416 NM_Sig_5_ASDM "Network Manegement Signal";
CM_ SG_ 416 NM_Sig_6_ASDM "Network Manegement Signal";
CM_ SG_ 416 NM_Sig_7_ASDM "Network Manegement Signal";
CM_ BO_ 1028 "This MSG is Received by sensor for XCP calibration";
CM_ SG_ 1028 XCP_Master_0_ASDM_RL "This signal is received by sensor for XCP calibration";
CM_ SG_ 1028 XCP_Master_1_ASDM_RL "This signal is received by sensor for XCP calibration";
CM_ SG_ 1028 XCP_Master_2_ASDM_RL "This signal is received by sensor for XCP calibration";
CM_ SG_ 1028 XCP_Master_3_ASDM_RL "This signal is received by sensor for XCP calibration";
CM_ SG_ 1028 XCP_Master_4_ASDM_RL "This signal is received by sensor for XCP calibration";
CM_ SG_ 1028 XCP_Master_5_ASDM_RL "This signal is received by sensor for XCP calibration";
CM_ SG_ 1028 XCP_Master_6_ASDM_RL "This signal is received by sensor for XCP calibration";
CM_ SG_ 1028 XCP_Master_7_ASDM_RL "This signal is received by sensor for XCP calibration";
CM_ BO_ 1029 "This MSG is Sent by sensor for XCP calibration";
CM_ SG_ 1029 XCP_Slave_0_RL "This signal is sent by sensor for XCP calibration";
CM_ SG_ 1029 XCP_Slave_1_RL "This signal is sent by sensor for XCP calibration";
CM_ SG_ 1029 XCP_Slave_2_RL "This signal is sent by sensor for XCP calibration";
CM_ SG_ 1029 XCP_Slave_3_RL "This signal is sent by sensor for XCP calibration";
CM_ SG_ 1029 XCP_Slave_4_RL "This signal is sent by sensor for XCP calibration";
CM_ SG_ 1029 XCP_Slave_5_RL "This signal is sent by sensor for XCP calibration";
CM_ SG_ 1029 XCP_Slave_6_RL "This signal is sent by sensor for XCP calibration";
CM_ SG_ 1029 XCP_Slave_7_RL "This signal is sent by sensor for XCP calibration";
CM_ BO_ 1282 "ECU_WAKE_UP";
CM_ BO_ 2002 "This MSG is Received by sensor for XCP calibration";
CM_ SG_ 2002 XCP_Master_0_ASDM_RR "This signal is received by sensor for XCP calibration";
CM_ SG_ 2002 XCP_Master_1_ASDM_RR "This signal is received by sensor for XCP calibration";
CM_ SG_ 2002 XCP_Master_2_ASDM_RR "This signal is received by sensor for XCP calibration";
CM_ SG_ 2002 XCP_Master_3_ASDM_RR "This signal is received by sensor for XCP calibration";
CM_ SG_ 2002 XCP_Master_4_ASDM_RR "This signal is received by sensor for XCP calibration";
CM_ SG_ 2002 XCP_Master_5_ASDM_RR "This signal is received by sensor for XCP calibration";
CM_ SG_ 2002 XCP_Master_6_ASDM_RR "This signal is received by sensor for XCP calibration";
CM_ SG_ 2002 XCP_Master_7_ASDM_RR "This signal is received by sensor for XCP calibration";
CM_ BO_ 2003 "This MSG is Sent by sensor for XCP calibration";
CM_ SG_ 2003 XCP_Slave_0_RR "This signal is sent by sensor for XCP calibration";
CM_ SG_ 2003 XCP_Slave_1_RR "This signal is sent by sensor for XCP calibration";
CM_ SG_ 2003 XCP_Slave_2_RR "This signal is sent by sensor for XCP calibration";
CM_ SG_ 2003 XCP_Slave_3_RR "This signal is sent by sensor for XCP calibration";
CM_ SG_ 2003 XCP_Slave_4_RR "This signal is sent by sensor for XCP calibration";
CM_ SG_ 2003 XCP_Slave_5_RR "This signal is sent by sensor for XCP calibration";
CM_ SG_ 2003 XCP_Slave_6_RR "This signal is sent by sensor for XCP calibration";
CM_ SG_ 2003 XCP_Slave_7_RR "This signal is sent by sensor for XCP calibration";
CM_ BO_ 3 "Time Sync Message used by CanTSync for Syncing FR with DSF";
CM_ BO_ 257 "Detection Header Message";
CM_ SG_ 257 CycleNumber_RL "AliveCounter/MCC";
CM_ BO_ 304 "DetectionList";
CM_ BO_ 305 "DetectionList";
CM_ BO_ 306 "DetectionList";
CM_ BO_ 307 "DetectionList";
CM_ BO_ 308 "DetectionList";
CM_ BO_ 309 "DetectionList";
CM_ BO_ 310 "DetectionList";
CM_ BO_ 311 "DetectionList";
CM_ BO_ 312 "DetectionList";
CM_ BO_ 313 "DetectionList";
CM_ BO_ 314 "DetectionList";
CM_ BO_ 315 "DetectionList";
CM_ BO_ 316 "DetectionList";
CM_ BO_ 317 "DetectionList";
CM_ BO_ 318 "DetectionList";
CM_ BO_ 319 "DetectionList";
CM_ BO_ 320 "DetectionList";
CM_ BO_ 321 "DetectionList";
CM_ BO_ 322 "DetectionList";
CM_ BO_ 323 "DetectionList";
CM_ BO_ 324 "DetectionList";
CM_ BO_ 325 "DetectionList";
CM_ BO_ 326 "DetectionList";
CM_ BO_ 327 "DetectionList";
CM_ BO_ 328 "DetectionList";
CM_ BO_ 329 "DetectionList";
CM_ BO_ 330 "DetectionList";
CM_ BO_ 331 "DetectionList";
CM_ BO_ 332 "DetectionList";
CM_ BO_ 333 "DetectionList";
CM_ BO_ 334 "DetectionList";
CM_ BO_ 335 "DetectionList";
CM_ BO_ 336 "DetectionList";
CM_ BO_ 337 "DetectionList";
CM_ BO_ 338 "DetectionList";
CM_ BO_ 339 "DetectionList";
CM_ BO_ 340 "DetectionList";
CM_ BO_ 341 "DetectionList";
CM_ BO_ 342 "DetectionList";
CM_ BO_ 343 "DetectionList";
CM_ BO_ 344 "DetectionList";
CM_ BO_ 345 "DetectionList";
CM_ BO_ 346 "DetectionList";
CM_ BO_ 347 "DetectionList";
CM_ BO_ 348 "DetectionList";
CM_ BO_ 349 "DetectionList";
CM_ BO_ 350 "DetectionList";
CM_ BO_ 351 "DetectionList";
CM_ BO_ 352 "DetectionList";
CM_ BO_ 353 "DetectionList";
CM_ BO_ 354 "DetectionList";
CM_ BO_ 355 "DetectionList";
CM_ BO_ 356 "DetectionList";
CM_ BO_ 357 "DetectionList";
CM_ BO_ 358 "DetectionList";
CM_ BO_ 359 "DetectionList";
CM_ BO_ 769 "Vehicle Data Message used by comh to recieve the Vehicle Data";
CM_ SG_ 769 HostGear_ASDM "Host gear shift";
CM_ BO_ 784 "Processing Profil Message used by app to send Profiling Data To PC when available";
CM_ BO_ 785 "AASC Result";
CM_ BO_ 786 "Send the Voltage state to PC";
CM_ BO_ 787 "Send Eagle and MCU Tempreture to PC";
CM_ BO_ 788 "Versions Message used by comh to send SW versions";
CM_ SG_ 788 LCP2_Data_Ver_Major_RL "LCP2 version";
CM_ SG_ 788 LCP2_Data_Ver_Minor_RL "LCP2 version";
CM_ SG_ 788 LCP2_Design_Ver_Major_RL "LCP2 version";
CM_ SG_ 788 LCP2_Design_Ver_Minor_RL "LCP2 version";
CM_ SG_ 788 LCP3_SR_Ver_Major_RL "LCP3 Version Major - Parking mode (Short Range)";
CM_ SG_ 788 LCP3_SR_Ver_Minor_RL "LCP3 Version Minor - Parking mode (Short Range)";
CM_ SG_ 788 LCP3_SR_Ver_Build_RL "LCP3 Version Build - Parking mode (Short Range)";
CM_ SG_ 788 LCP3_LR_Ver_Major_RL "LCP3 Version Major - Driving mode (Long Range)";
CM_ SG_ 788 LCP3_LR_Ver_Minor_RL "LCP3 Version Minor - Driving mode (Long Range)";
CM_ SG_ 788 LCP3_LR_Ver_Build_RL "LCP3 Version Build - Driving mode (Long Range)";
CM_ BO_ 1290 "LLST Response";
CM_ BO_ 1291 "LLST Response";
CM_ BO_ 1292 "LLST Response";
CM_ BO_ 1293 "LLST Response";
CM_ BO_ 1294 "LLST Response";
CM_ BO_ 1295 "LLST Response";
CM_ BO_ 1296 "LLST Response";
CM_ BO_ 1297 "LLST Response";
CM_ BO_ 1298 "LLST Response";
CM_ BO_ 1299 "LLST Response";
CM_ BO_ 1300 "LLST Response";
CM_ BO_ 1301 "LLST Response";
CM_ BO_ 1302 "LLST Response";
CM_ BO_ 1303 "LLST Response";
CM_ BO_ 1304 "LLST Response";
CM_ BO_ 1305 "LLST Response";
CM_ BO_ 1306 "LLST Response";
CM_ BO_ 1307 "Azimuth Corections from AASC";
CM_ BO_ 1308 "Azimuth Corections from AASC";
CM_ BO_ 1309 "Azimuth Corections from AASC";

// Attribute definitions
BA_DEF_  "BaudRateCANFD" FLOAT 1000 10000000; // [bps]
BA_DEF_  "Baudrate" INT 1000 1000000; // [bps]
BA_DEF_  "BusType" STRING;
BA_DEF_  "DBName" STRING;
BA_DEF_  "ProtocolType" STRING;
BA_DEF_ BO_ "CANFD_BRS" ENUM "0","1";
BA_DEF_ BO_ "GenMsgCycleTime" INT 0 65536; // [ms]
BA_DEF_ BO_ "GenMsgDelayTime" INT 0 65536; // [ms]
BA_DEF_ BO_ "GenMsgSendType" ENUM "cyclic", "spontaneous", "not-used", "not-used", "not-used", "cyclicAndSpontaneous", "not-used", "cyclicIfActive", "NoMsgSendType"; // [us]
BA_DEF_ BO_ "VFrameFormat" ENUM "StandardCAN","ExtendedCAN","reserved","J1939PG","reserved","reserved","reserved","reserved","reserved","reserved","reserved","reserved","reserved","reserved","StandardCAN_FD","ExtendedCAN_FD";
BA_DEF_ SG_ "GenSigSendType" ENUM "Cyclic","OnWrite","OnWriteWithRepetition","OnChange","OnChangeWithRepetition","IfActive","IfActiveWithRepetition","NoSigSendType";
BA_DEF_ SG_ "SystemSignalLongSymbol" STRING ;
BA_DEF_ SG_ "GenSigStartValue" FLOAT -1.79769313486232E+019 1.84467440737096E+019;
BA_DEF_ BO_ "GenMsgILSupport" ENUM "No","Yes";
BA_DEF_ BO_ "NmAsrMessage" ENUM "No","Yes";
BA_DEF_  "NmAsrBaseAddress" HEX 0 536870911;
BA_DEF_  "NmAsrMessageCount" INT 0 255;
BA_DEF_ BU_ "NodeLayerModules" STRING;
BA_DEF_ BU_ "ILused" ENUM "No","Yes";
BA_DEF_ SG_ "GenSigFuncType" ENUM "NoFun","n","n","n","n","n","n","n","n","n","n","n","n","n","n","CHK","CNT","n","n","n","CNT1","CRC1B","CRC1A","CRC1L","CRC1N","CNT4","CRC4A","CNT5","CRC5","n","n","n","n","CNT2","CRC2","CNT11","CRC11B","n","n","CRC11N";

BA_DEF_DEF_ "BusType" "";
BA_DEF_DEF_ "DBName" "";
BA_DEF_DEF_ "ProtocolType" "";
BA_DEF_DEF_ "CANFD_BRS" "1";
BA_DEF_DEF_ "GenSigStartValue" 0;
BA_DEF_DEF_ "VFrameFormat" "J1939PG";
BA_DEF_DEF_ "GenSigSendType" "NoSigSendType";
BA_DEF_DEF_ "GenMsgCycleTime" 0;
BA_DEF_DEF_ "GenMsgDelayTime" 0;
BA_DEF_DEF_ "GenMsgSendType" "Spontaneous";
BA_DEF_DEF_ "GenMsgILSupport" "Yes";
BA_DEF_DEF_ "NmAsrMessage" "No";
BA_DEF_DEF_ "NmAsrBaseAddress" 1280;
BA_DEF_DEF_ "NmAsrMessageCount" 64;
BA_DEF_DEF_ "NodeLayerModules" "CANoeILNLVector.dll";
BA_DEF_DEF_ "ILused" "Yes";
BA_DEF_DEF_ "GenSigFuncType" "NoFun";
BA_DEF_DEF_  "SystemSignalLongSymbol" "";

BA_ "BaudRateCANFD" 2500000;
BA_ "Baudrate" 830000;
BA_ "BusType" "CAN FD";
BA_ "DBName" "ASDM3CANFD";
BA_ "ProtocolType" "CAN";
// Network
// ECU: ASDM
BA_ "ILused" BU_ ASDM 0;
// ECU: RSRL
BA_ "ILused" BU_ RSRL 0;
// ECU: RSRR
BA_ "ILused" BU_ RSRR 0;
// Frame: AsdmToAllFuncAsdm3CanDiagReqFrame
BA_ "GenMsgDelayTime" BO_ 2047 5.000;
BA_ "GenMsgSendType" BO_ 2047 1;
BA_ "VFrameFormat" BO_ 2047 14;
// Frame: AsdmToRsrlAsdm3CanDiagReqFrame
BA_ "GenMsgDelayTime" BO_ 1953 5.000;
BA_ "GenMsgSendType" BO_ 1953 1;
BA_ "VFrameFormat" BO_ 1953 14;
// Frame: AsdmToRsrrAsdm3CanDiagReqFrame
BA_ "GenMsgDelayTime" BO_ 1954 5.000;
BA_ "GenMsgSendType" BO_ 1954 1;
BA_ "VFrameFormat" BO_ 1954 14;
// Frame: RsrlToAsdmAsdm3CanDiagResFrame
BA_ "GenMsgDelayTime" BO_ 1697 5.000;
BA_ "GenMsgSendType" BO_ 1697 1;
BA_ "VFrameFormat" BO_ 1697 14;
// Frame: RsrrToAsdmAsdm3CanDiagResFrame
BA_ "GenMsgDelayTime" BO_ 1698 5.000;
BA_ "GenMsgSendType" BO_ 1698 1;
BA_ "VFrameFormat" BO_ 1698 14;

BA_ "GenMsgSendType" BO_ 134 1;
BA_ "VFrameFormat" BO_ 134 14;
BA_ "GenMsgSendType" BO_ 6 1;
BA_ "VFrameFormat" BO_ 6 14;
BA_ "GenMsgSendType" BO_ 917 0;
BA_ "GenMsgCycleTime" BO_ 917 1000;
BA_ "VFrameFormat" BO_ 917 14;
BA_ "GenMsgSendType" BO_ 789 0;
BA_ "GenMsgCycleTime" BO_ 789 1000;
BA_ "VFrameFormat" BO_ 789 14;
BA_ "GenMsgSendType" BO_ 898 0;
BA_ "GenMsgCycleTime" BO_ 898 50;
BA_ "VFrameFormat" BO_ 898 14;
BA_ "GenMsgSendType" BO_ 770 0;
BA_ "GenMsgCycleTime" BO_ 770 50;
BA_ "VFrameFormat" BO_ 770 14;
BA_ "GenMsgSendType" BO_ 918 1;
BA_ "VFrameFormat" BO_ 918 14;
BA_ "GenMsgSendType" BO_ 790 1;
BA_ "VFrameFormat" BO_ 790 14;
BA_ "GenMsgSendType" BO_ 1281 0;
BA_ "GenMsgCycleTime" BO_ 1281 50;
BA_ "VFrameFormat" BO_ 1281 14;
BA_ "GenMsgSendType" BO_ 416 1;
BA_ "VFrameFormat" BO_ 416 14;
BA_ "GenMsgSendType" BO_ 288 0;
BA_ "GenMsgCycleTime" BO_ 288 25;
BA_ "VFrameFormat" BO_ 288 14;
BA_ "GenMsgILSupport" BO_ 1028 0;
BA_ "GenMsgSendType" BO_ 1028 1;
BA_ "VFrameFormat" BO_ 1028 14;
BA_ "GenMsgILSupport" BO_ 1029 0;
BA_ "GenMsgSendType" BO_ 1029 1;
BA_ "VFrameFormat" BO_ 1029 14;
BA_ "GenMsgSendType" BO_ 1282 0;
BA_ "GenMsgCycleTime" BO_ 1282 50;
BA_ "VFrameFormat" BO_ 1282 14;
BA_ "GenMsgSendType" BO_ 2002 1;
BA_ "GenMsgILSupport" BO_ 2002 0;
BA_ "VFrameFormat" BO_ 2002 14;
BA_ "GenMsgSendType" BO_ 2003 1;
BA_ "GenMsgILSupport" BO_ 2003 0;
BA_ "VFrameFormat" BO_ 2003 14;
BA_ "GenMsgSendType" BO_ 3 1;
BA_ "VFrameFormat" BO_ 3 14;
BA_ "GenMsgSendType" BO_ 257 1;
BA_ "VFrameFormat" BO_ 257 14;
BA_ "GenMsgSendType" BO_ 304 1;
BA_ "VFrameFormat" BO_ 304 14;
BA_ "GenMsgSendType" BO_ 305 1;
BA_ "VFrameFormat" BO_ 305 14;
BA_ "GenMsgSendType" BO_ 306 1;
BA_ "VFrameFormat" BO_ 306 14;
BA_ "GenMsgSendType" BO_ 307 1;
BA_ "VFrameFormat" BO_ 307 14;
BA_ "GenMsgSendType" BO_ 308 1;
BA_ "VFrameFormat" BO_ 308 14;
BA_ "GenMsgSendType" BO_ 309 1;
BA_ "VFrameFormat" BO_ 309 14;
BA_ "GenMsgSendType" BO_ 310 1;
BA_ "VFrameFormat" BO_ 310 14;
BA_ "GenMsgSendType" BO_ 311 1;
BA_ "VFrameFormat" BO_ 311 14;
BA_ "GenMsgSendType" BO_ 312 1;
BA_ "VFrameFormat" BO_ 312 14;
BA_ "GenMsgSendType" BO_ 313 1;
BA_ "VFrameFormat" BO_ 313 14;
BA_ "GenMsgSendType" BO_ 314 1;
BA_ "VFrameFormat" BO_ 314 14;
BA_ "GenMsgSendType" BO_ 315 1;
BA_ "VFrameFormat" BO_ 315 14;
BA_ "GenMsgSendType" BO_ 316 1;
BA_ "VFrameFormat" BO_ 316 14;
BA_ "GenMsgSendType" BO_ 317 1;
BA_ "VFrameFormat" BO_ 317 14;
BA_ "GenMsgSendType" BO_ 318 1;
BA_ "VFrameFormat" BO_ 318 14;
BA_ "GenMsgSendType" BO_ 319 1;
BA_ "VFrameFormat" BO_ 319 14;
BA_ "GenMsgSendType" BO_ 320 1;
BA_ "VFrameFormat" BO_ 320 14;
BA_ "GenMsgSendType" BO_ 321 1;
BA_ "VFrameFormat" BO_ 321 14;
BA_ "GenMsgSendType" BO_ 322 1;
BA_ "VFrameFormat" BO_ 322 14;
BA_ "GenMsgSendType" BO_ 323 1;
BA_ "VFrameFormat" BO_ 323 14;
BA_ "GenMsgSendType" BO_ 324 1;
BA_ "VFrameFormat" BO_ 324 14;
BA_ "GenMsgSendType" BO_ 325 1;
BA_ "VFrameFormat" BO_ 325 14;
BA_ "GenMsgSendType" BO_ 326 1;
BA_ "VFrameFormat" BO_ 326 14;
BA_ "GenMsgSendType" BO_ 327 1;
BA_ "VFrameFormat" BO_ 327 14;
BA_ "GenMsgSendType" BO_ 328 1;
BA_ "VFrameFormat" BO_ 328 14;
BA_ "GenMsgSendType" BO_ 329 1;
BA_ "VFrameFormat" BO_ 329 14;
BA_ "GenMsgSendType" BO_ 330 1;
BA_ "VFrameFormat" BO_ 330 14;
BA_ "GenMsgSendType" BO_ 331 1;
BA_ "VFrameFormat" BO_ 331 14;
BA_ "GenMsgSendType" BO_ 332 1;
BA_ "VFrameFormat" BO_ 332 14;
BA_ "GenMsgSendType" BO_ 333 1;
BA_ "VFrameFormat" BO_ 333 14;
BA_ "GenMsgSendType" BO_ 334 1;
BA_ "VFrameFormat" BO_ 334 14;
BA_ "GenMsgSendType" BO_ 335 1;
BA_ "VFrameFormat" BO_ 335 14;
BA_ "GenMsgSendType" BO_ 336 1;
BA_ "VFrameFormat" BO_ 336 14;
BA_ "GenMsgSendType" BO_ 337 1;
BA_ "VFrameFormat" BO_ 337 14;
BA_ "GenMsgSendType" BO_ 338 1;
BA_ "VFrameFormat" BO_ 338 14;
BA_ "GenMsgSendType" BO_ 339 1;
BA_ "VFrameFormat" BO_ 339 14;
BA_ "GenMsgSendType" BO_ 340 1;
BA_ "VFrameFormat" BO_ 340 14;
BA_ "GenMsgSendType" BO_ 341 1;
BA_ "VFrameFormat" BO_ 341 14;
BA_ "GenMsgSendType" BO_ 342 1;
BA_ "VFrameFormat" BO_ 342 14;
BA_ "GenMsgSendType" BO_ 343 1;
BA_ "VFrameFormat" BO_ 343 14;
BA_ "GenMsgSendType" BO_ 344 1;
BA_ "VFrameFormat" BO_ 344 14;
BA_ "GenMsgSendType" BO_ 345 1;
BA_ "VFrameFormat" BO_ 345 14;
BA_ "GenMsgSendType" BO_ 346 1;
BA_ "VFrameFormat" BO_ 346 14;
BA_ "GenMsgSendType" BO_ 347 1;
BA_ "VFrameFormat" BO_ 347 14;
BA_ "GenMsgSendType" BO_ 348 1;
BA_ "VFrameFormat" BO_ 348 14;
BA_ "GenMsgSendType" BO_ 349 1;
BA_ "VFrameFormat" BO_ 349 14;
BA_ "GenMsgSendType" BO_ 350 1;
BA_ "VFrameFormat" BO_ 350 14;
BA_ "GenMsgSendType" BO_ 351 1;
BA_ "VFrameFormat" BO_ 351 14;
BA_ "GenMsgSendType" BO_ 352 1;
BA_ "VFrameFormat" BO_ 352 14;
BA_ "GenMsgSendType" BO_ 353 1;
BA_ "VFrameFormat" BO_ 353 14;
BA_ "GenMsgSendType" BO_ 354 1;
BA_ "VFrameFormat" BO_ 354 14;
BA_ "GenMsgSendType" BO_ 355 1;
BA_ "VFrameFormat" BO_ 355 14;
BA_ "GenMsgSendType" BO_ 356 1;
BA_ "VFrameFormat" BO_ 356 14;
BA_ "GenMsgSendType" BO_ 357 1;
BA_ "VFrameFormat" BO_ 357 14;
BA_ "GenMsgSendType" BO_ 358 1;
BA_ "VFrameFormat" BO_ 358 14;
BA_ "GenMsgSendType" BO_ 359 1;
BA_ "VFrameFormat" BO_ 359 14;
BA_ "GenMsgSendType" BO_ 769 0;
BA_ "GenMsgCycleTime" BO_ 769 25;
BA_ "VFrameFormat" BO_ 769 14;
BA_ "GenMsgSendType" BO_ 784 1;
BA_ "VFrameFormat" BO_ 784 14;
BA_ "GenMsgSendType" BO_ 785 0;
BA_ "GenMsgCycleTime" BO_ 785 50;
BA_ "VFrameFormat" BO_ 785 14;
BA_ "GenMsgSendType" BO_ 786 0;
BA_ "GenMsgCycleTime" BO_ 786 50;
BA_ "VFrameFormat" BO_ 786 14;
BA_ "GenMsgSendType" BO_ 787 0;
BA_ "GenMsgCycleTime" BO_ 787 50;
BA_ "VFrameFormat" BO_ 787 14;
BA_ "GenMsgSendType" BO_ 788 1;
BA_ "VFrameFormat" BO_ 788 14;
BA_ "GenMsgSendType" BO_ 1280 1;
BA_ "VFrameFormat" BO_ 1280 14;
BA_ "GenMsgSendType" BO_ 1290 1;
BA_ "VFrameFormat" BO_ 1290 14;
BA_ "GenMsgSendType" BO_ 1291 1;
BA_ "VFrameFormat" BO_ 1291 14;
BA_ "GenMsgSendType" BO_ 1292 1;
BA_ "VFrameFormat" BO_ 1292 14;
BA_ "GenMsgSendType" BO_ 1293 1;
BA_ "VFrameFormat" BO_ 1293 14;
BA_ "GenMsgSendType" BO_ 1294 1;
BA_ "VFrameFormat" BO_ 1294 14;
BA_ "GenMsgSendType" BO_ 1295 1;
BA_ "VFrameFormat" BO_ 1295 14;
BA_ "GenMsgSendType" BO_ 1296 1;
BA_ "VFrameFormat" BO_ 1296 14;
BA_ "GenMsgSendType" BO_ 1297 1;
BA_ "VFrameFormat" BO_ 1297 14;
BA_ "GenMsgSendType" BO_ 1298 1;
BA_ "VFrameFormat" BO_ 1298 14;
BA_ "GenMsgSendType" BO_ 1299 1;
BA_ "VFrameFormat" BO_ 1299 14;
BA_ "GenMsgSendType" BO_ 1300 1;
BA_ "VFrameFormat" BO_ 1300 14;
BA_ "GenMsgSendType" BO_ 1301 1;
BA_ "VFrameFormat" BO_ 1301 14;
BA_ "GenMsgSendType" BO_ 1302 1;
BA_ "VFrameFormat" BO_ 1302 14;
BA_ "GenMsgSendType" BO_ 1303 1;
BA_ "VFrameFormat" BO_ 1303 14;
BA_ "GenMsgSendType" BO_ 1304 1;
BA_ "VFrameFormat" BO_ 1304 14;
BA_ "GenMsgSendType" BO_ 1305 1;
BA_ "VFrameFormat" BO_ 1305 14;
BA_ "GenMsgSendType" BO_ 1306 1;
BA_ "VFrameFormat" BO_ 1306 14;
BA_ "GenMsgSendType" BO_ 1307 1;
BA_ "VFrameFormat" BO_ 1307 14;
BA_ "GenMsgSendType" BO_ 1308 1;
BA_ "VFrameFormat" BO_ 1308 14;
BA_ "GenMsgSendType" BO_ 1309 1;
BA_ "VFrameFormat" BO_ 1309 14;

BA_ "SystemSignalLongSymbol" SG_ 898 Sensor_Error_Synchronization_Err "Sensor_Error_Synchronization_Error_RR";
BA_ "SystemSignalLongSymbol" SG_ 898 Sensor_Error_Software_Incompatib "Sensor_Error_Software_Incompatible_RR";
BA_ "SystemSignalLongSymbol" SG_ 898 Sensor_Error_Calibration_Error_R "Sensor_Error_Calibration_Error_RR";
BA_ "SystemSignalLongSymbol" SG_ 770 Sensor_Error_Synchronizatio_0000 "Sensor_Error_Synchronization_Error_RL";
BA_ "SystemSignalLongSymbol" SG_ 770 Sensor_Error_Software_Incom_0000 "Sensor_Error_Software_Incompatible_RL";
BA_ "SystemSignalLongSymbol" SG_ 770 Sensor_Error_Calibration_Er_0000 "Sensor_Error_Calibration_Error_RL";
BA_ "GenSigStartValue" SG_ 769 HostGear_ASDM 1;
VAL_ 898 Sensor_Operation_Mode_RR 0 "Undefined" 1 "Startup" 2 "Normal_Run" 3 "Faulty" 5 "Shutdown" 7 "Testing" 15 "Transaction_Mode" ;
VAL_ 770 Sensor_Operation_Mode_RL 0 "Undefined" 1 "Startup" 2 "Normal_Run" 3 "Faulty" 5 "Shutdown" 7 "Testing" 15 "Transaction_Mode" ;
VAL_ 3 Type_EXT_ASDM 16 "CANTSYN_SYNC_NOT_CRC_SECURED" 32 "CANTSYN_SYNC_CRC_SECURED" 24 "CANTSYN_FUP_NOT_CRC_SECURED" 40 "CANTSYN_FUP_CRC_SECURED" 48 "CANTSYN_OFS_NOT_CRC_SECURED" 64 "CANTSYN_OFS_CRC_SECURED" 56 "CANTSYN_OFNS_NOT_CRC_SECURED" 72 "CANTSYN_OFNS_CRC_SECURED" ;
VAL_ 257 ElevAlignment_Status_RL 2 "MBASC_ELEV_MISALIGNED" 1 "MBASC_ELEV_ALIGNED" 0 "MBASC_ELEV_CALIBRATING" ;
VAL_ 257 UnambiguousVelMeas1_RL 0 "TPRI_69us" 1 "TPRI_82.8us" 2 "TPRI_96.6us" ;
VAL_ 257 Radar_Sensor_type_RL 0 "Gen1.1" 1 "Gen1.2" 2 "MB79_A6" 3 "MCR2" 4 "MFR1" 5 "MFR1_2" 6 "MCR1_2_E" 7 "MFR1_2_E" ;
VAL_ 257 Sensor_Position_ID_RL 0 "FL" 1 "FR" 2 "RL" 3 "RR" 4 "MFR" 5 "Reserved" 6 "Reserved" 7 "Reserved" ;
VAL_ 257 interferenceDetected_RL 0 "False" 1 "True" ;
VAL_ 257 Blockage_Status_RL 0 "Unblocked" 1 "Blocked" 2 "Partial_Low" 3 "Partial_Medium" 4 "Partial_High" ;
VAL_ 257 AutoAlignment_Status_RL 0 "Reserved" 1 "Reserved" 2 "Reserved" 3 "Online Validation" 4 "Online DBAA (or Coarse Alignment)" 5 "Online ASC (or Fine Alignment)" 6 "Aligned" 7 "MisAligned" 14 "Manual" 15 "Inactive" ;
VAL_ 257 Testing_Mode_RL 0 "No_Test_Mode_Active" 1 "END_OF_LINE_TEST" 2 "HILT" 3 "LLHT_beam_pattern" 4 "LLHT_video" 5 "LLHT_FFT2D" 6 "LLHT_FFT3D_CMPLX" 7 "EIRP" 8 "LLHT_FFT3D_SPEC" 9 "Z7_CORES_IDLE" 10 "OSM_MODE" 11 "EMC" ;
VAL_ 257 Detection_Data_Mode_RL 1 "Parking mode data" 0 "Driving mode data" ;
VAL_ 257 Sensor_Topology_RL 0 "Master" 1 "Slave" ;
VAL_ 257 AASC_Calibration_flag_RL 1 "Calibration complete" 0 "Calibration Not complete" ;
VAL_ 257 selected_chirp_config_RL 0 "64" 1 "128" 2 "256" 3 "512" 4 "1024" 5 "2048" ;
VAL_ 769 VehiclePower_Gear_ASDM 15 "Invalid" 8 "Start" 4 "Run" 3 "ON" 2 "ACC" 1 "OFF" 0 "Uknown" ;
VAL_ 769 HostTrailerAttached_ASDM 0 "not_connected" 1 "connected" ;
VAL_ 769 HostDrivingForward_ASDM 0 "False" 1 "True" ;
VAL_ 769 HostGear_ASDM 0 "Gear_P" 1 "Gear_1" 2 "Gear_2" 3 "Gear_3" 4 "Gear_4" 5 "Gear_5" 6 "Gear_6" 7 "Gear_7" 8 "Gear_R" 9 "Gear_N" 11 "Gear_8" 12 "Gear_9" 14 "Gear_not_defined" 15 "Error" ;
VAL_ 784 Function_ID_0_RL 0 "Empty_FUNC_ID" 1 "ICCM_DSS_FUNC_HWA1D_RUN" 2 "ICCM_DSS_FUNC_HWA2D_CONFIG" 3 "ICCM_DSS_FUNC_HWA2D_RUN" 4 "ICCM_DSS_FUNC_C1SA_RUN" 5 "ICCM_DSS_FUNC_C1CG_RUN" 6 "ICCM_DSS_FUNC_NRLC" 7 "ICCM_DSS_FUNC_SPEC" 8 "ICCM_DSS_FUNC_CFAR" 9 "ICCM_DSS_FUNC_DETC" 10 "ICCM_DSS_FUNC_DOAE" 11 "ICCM_DSS_FUNC_FECL" 12 "ICCM_DSS_FUNC_HPRM" 13 "ICCM_DSS_FUNC_AASC" 14 "ICCM_DSS_FUNC_INFC" 15 "ICCM_DSS_FUNC_RVVP" 16 "ICCM_DSS_FUNC_PRPC" 17 "ICCM_DSS_FUNC_PRPC_HWA_CONFIG" 18 "ICCM_DSS_FUNC_PRPC_RECONFIG" 19 "ICCM_DSS_FUNC_PRPC_AASC_MSG" 20 "ICCM_DSS_FUNC_PRPC_LAST_MSG" 255 "STACK_USAGE" ;
VAL_ 784 Function_ID_1_RL 0 "Empty_FUNC_ID" 1 "ICCM_DSS_FUNC_HWA1D_RUN" 2 "ICCM_DSS_FUNC_HWA2D_CONFIG" 3 "ICCM_DSS_FUNC_HWA2D_RUN" 4 "ICCM_DSS_FUNC_C1SA_RUN" 5 "ICCM_DSS_FUNC_C1CG_RUN" 6 "ICCM_DSS_FUNC_NRLC" 7 "ICCM_DSS_FUNC_SPEC" 8 "ICCM_DSS_FUNC_CFAR" 9 "ICCM_DSS_FUNC_DETC" 10 "ICCM_DSS_FUNC_DOAE" 11 "ICCM_DSS_FUNC_FECL" 12 "ICCM_DSS_FUNC_HPRM" 13 "ICCM_DSS_FUNC_AASC" 14 "ICCM_DSS_FUNC_INFC" 15 "ICCM_DSS_FUNC_RVVP" 16 "ICCM_DSS_FUNC_PRPC" 17 "ICCM_DSS_FUNC_PRPC_HWA_CONFIG" 18 "ICCM_DSS_FUNC_PRPC_RECONFIG" 19 "ICCM_DSS_FUNC_PRPC_AASC_MSG" 20 "ICCM_DSS_FUNC_PRPC_LAST_MSG" 255 "STACK_USAGE" ;
VAL_ 784 Function_ID_2_RL 0 "Empty_FUNC_ID" 1 "ICCM_DSS_FUNC_HWA1D_RUN" 2 "ICCM_DSS_FUNC_HWA2D_CONFIG" 3 "ICCM_DSS_FUNC_HWA2D_RUN" 4 "ICCM_DSS_FUNC_C1SA_RUN" 5 "ICCM_DSS_FUNC_C1CG_RUN" 6 "ICCM_DSS_FUNC_NRLC" 7 "ICCM_DSS_FUNC_SPEC" 8 "ICCM_DSS_FUNC_CFAR" 9 "ICCM_DSS_FUNC_DETC" 10 "ICCM_DSS_FUNC_DOAE" 11 "ICCM_DSS_FUNC_FECL" 12 "ICCM_DSS_FUNC_HPRM" 13 "ICCM_DSS_FUNC_AASC" 14 "ICCM_DSS_FUNC_INFC" 15 "ICCM_DSS_FUNC_RVVP" 16 "ICCM_DSS_FUNC_PRPC" 17 "ICCM_DSS_FUNC_PRPC_HWA_CONFIG" 18 "ICCM_DSS_FUNC_PRPC_RECONFIG" 19 "ICCM_DSS_FUNC_PRPC_AASC_MSG" 20 "ICCM_DSS_FUNC_PRPC_LAST_MSG" 255 "STACK_USAGE" ;
VAL_ 784 Function_ID_3_RL 0 "Empty_FUNC_ID" 1 "ICCM_DSS_FUNC_HWA1D_RUN" 2 "ICCM_DSS_FUNC_HWA2D_CONFIG" 3 "ICCM_DSS_FUNC_HWA2D_RUN" 4 "ICCM_DSS_FUNC_C1SA_RUN" 5 "ICCM_DSS_FUNC_C1CG_RUN" 6 "ICCM_DSS_FUNC_NRLC" 7 "ICCM_DSS_FUNC_SPEC" 8 "ICCM_DSS_FUNC_CFAR" 9 "ICCM_DSS_FUNC_DETC" 10 "ICCM_DSS_FUNC_DOAE" 11 "ICCM_DSS_FUNC_FECL" 12 "ICCM_DSS_FUNC_HPRM" 13 "ICCM_DSS_FUNC_AASC" 14 "ICCM_DSS_FUNC_INFC" 15 "ICCM_DSS_FUNC_RVVP" 16 "ICCM_DSS_FUNC_PRPC" 17 "ICCM_DSS_FUNC_PRPC_HWA_CONFIG" 18 "ICCM_DSS_FUNC_PRPC_RECONFIG" 19 "ICCM_DSS_FUNC_PRPC_AASC_MSG" 20 "ICCM_DSS_FUNC_PRPC_LAST_MSG" 255 "STACK_USAGE" ;
VAL_ 785 AutoAlignment_ErrorType_RL 0 "OV - not enough detections (upon timeout)" 1 "OV - error too big" 2 "DBAA - estimated MAO too large" 3 "DBAA - too many bins empty" 4 "DBAA - repeatedly too many bins empty" 5 "ASC - too many bins empty" 6 "Unused" 7 "Unused" ;
VAL_ 785 AutoCalib_Status_RL 0 "Calib Not Started" 1 "Calib InProgress" 2 "Calib Successful" 3 "Not Enough Detections" 4 "Calib Not Precise Enough" 5 "Misaligned to the Left" 6 "Misaligned to the Right" 7 "MisAligned Upward" 8 "MisAligned Downward" 9 "Unused" 15 "Unused" ;
VAL_ 787 MCU_Temp_Status_RL 11 "OverThreshold" 10 "Normal" 14 "UnderThreshold" ;
VAL_ 1290 LLHT_Data_Header_Mode_ID_RL 1 "Video Mode" 2 "FFT2D Mode" 3 "FFT3D CMPLX Mode" 4 "FFT3D SPEC Mode" 5 "Beam Pattern Mode" 6 "EIRP Mode" 7 "Eagle BB" 8 "Eagle Tx" ;
SIG_GROUP_ 1281 ECU_WAKE_UP_RL 1 : ECU_Wake_UP_0_RL ECU_Wake_UP_1_RL ECU_Wake_UP_2_RL ECU_Wake_UP_3_RL ECU_Wake_UP_4_RL ECU_Wake_UP_5_RL ECU_Wake_UP_6_RL ECU_Wake_UP_7_RL;
SIG_GROUP_ 1028 XCP_MASTER_RL 1 : XCP_Master_0_ASDM_RL XCP_Master_1_ASDM_RL XCP_Master_2_ASDM_RL XCP_Master_3_ASDM_RL XCP_Master_4_ASDM_RL XCP_Master_5_ASDM_RL XCP_Master_6_ASDM_RL XCP_Master_7_ASDM_RL;
SIG_GROUP_ 1029 XCP_SLAVE_RL 1 : XCP_Slave_0_RL XCP_Slave_1_RL XCP_Slave_2_RL XCP_Slave_3_RL XCP_Slave_4_RL XCP_Slave_5_RL XCP_Slave_6_RL XCP_Slave_7_RL;
SIG_GROUP_ 1282 ECU_WAKE_UP_RR 1 : ECU_Wake_UP_0_RR ECU_Wake_UP_1_RR ECU_Wake_UP_2_RR ECU_Wake_UP_3_RR ECU_Wake_UP_4_RR ECU_Wake_UP_5_RR ECU_Wake_UP_6_RR ECU_Wake_UP_7_RR;
SIG_GROUP_ 2002 XCP_MASTER_RR 1 : XCP_Master_0_ASDM_RR XCP_Master_1_ASDM_RR XCP_Master_2_ASDM_RR XCP_Master_3_ASDM_RR XCP_Master_4_ASDM_RR XCP_Master_5_ASDM_RR XCP_Master_6_ASDM_RR XCP_Master_7_ASDM_RR;
SIG_GROUP_ 2003 XCP_SLAVE_RR 1 : XCP_Slave_0_RR XCP_Slave_1_RR XCP_Slave_2_RR XCP_Slave_3_RR XCP_Slave_4_RR XCP_Slave_5_RR XCP_Slave_6_RR XCP_Slave_7_RR;
SIG_GROUP_ 785 AUTOALIGN_RESULT_RL_SG_311 1 : AutoCalib_Status_RL AutoAlignment_ErrorType_RL;
